VERSION "HNNBNNNYNNNNNNNNNNNNNNNNNNNNNNNNNNNNNNNNNN/4/%%%/4/'%**4NNN///"

NS_ :

BS_:

BU_: BAP_Tester BMS_NV_12V Gateway_Max Klima

BO_ 1413 Systeminfo_01: 8 Gateway_Max
 SG_ SI_Sammel_SG_Fehler : 0|6@1+ (1,0) [0|60] ""  Vector__XXX
 SG_ SI_P_Mode_gueltig : 6|1@1+ (1.0,0.0) [0.0|1] ""  Klima
 SG_ SI_Diagnose_Aktiv : 7|1@1+ (1.0,0.0) [0.0|1] ""  Vector__XXX
 SG_ SI_QRS_Mode : 8|1@1+ (1.0,0.0) [0.0|1] ""  Klima
 SG_ SI_T_Mode : 9|1@1+ (1.0,0.0) [0.0|1] ""  Klima
 SG_ SI_NWDF : 10|1@1+ (1.0,0.0) [0.0|1] ""  Klima
 SG_ SI_NWDF_gueltig : 11|1@1+ (1.0,0.0) [0.0|1] ""  Klima
 SG_ SI_Sammelfehler : 12|1@1+ (1.0,0.0) [0.0|1] ""  Vector__XXX
 SG_ GW_KD_Fehler : 13|1@1+ (1.0,0.0) [0.0|1] ""  Vector__XXX
 SG_ SI_T_Schutz : 14|1@1+ (1.0,0.0) [0.0|1] ""  Klima
 SG_ SI_P_Mode : 15|1@1+ (1.0,0.0) [0.0|1] ""  Klima
 SG_ SI_BUS_01 : 16|1@1+ (1.0,0.0) [0.0|1] ""  Vector__XXX
 SG_ SI_BUS_02 : 17|1@1+ (1.0,0.0) [0.0|1] ""  Vector__XXX
 SG_ SI_BUS_03 : 18|1@1+ (1.0,0.0) [0.0|1] ""  Vector__XXX
 SG_ SI_BUS_04 : 19|1@1+ (1.0,0.0) [0.0|1] ""  Klima
 SG_ SI_BUS_05 : 20|1@1+ (1.0,0.0) [0.0|1] ""  Vector__XXX
 SG_ SI_BUS_06 : 21|1@1+ (1.0,0.0) [0.0|1] ""  Vector__XXX
 SG_ SI_BUS_07 : 22|1@1+ (1.0,0.0) [0.0|1] ""  Vector__XXX
 SG_ SI_BUS_08 : 23|1@1+ (1.0,0.0) [0.0|1] ""  Vector__XXX
 SG_ SI_BUS_09 : 24|1@1+ (1.0,0.0) [0.0|1] ""  Vector__XXX
 SG_ SI_BUS_10 : 25|1@1+ (1.0,0.0) [0.0|1] ""  Vector__XXX
 SG_ SI_BUS_11 : 26|1@1+ (1.0,0.0) [0.0|1] ""  Vector__XXX
 SG_ SI_BUS_12 : 27|1@1+ (1.0,0.0) [0.0|1] ""  Vector__XXX
 SG_ SI_BUS_13 : 28|1@1+ (1.0,0.0) [0.0|1] ""  Vector__XXX
 SG_ SI_BUS_14 : 29|1@1+ (1.0,0.0) [0.0|1] ""  Vector__XXX
 SG_ SI_BUS_15 : 30|1@1+ (1.0,0.0) [0.0|1] ""  Vector__XXX
 SG_ SI_NWDF_30 : 31|1@1+ (1.0,0.0) [0.0|1] ""  Vector__XXX
 SG_ SI_Bus_Identifikation : 32|8@1+ (1.0,0.0) [0.0|255] ""  Vector__XXX
 SG_ SI_CAB_V14 : 40|24@1+ (1.0,0.0) [0.0|16777215] ""  Klima

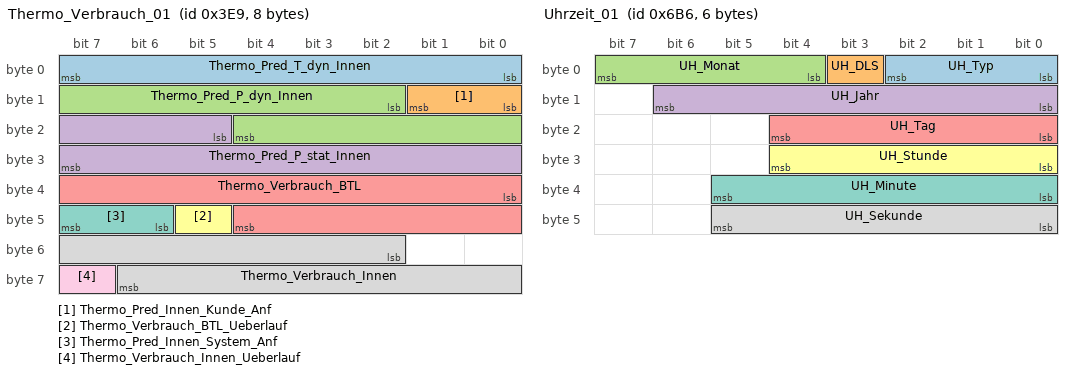
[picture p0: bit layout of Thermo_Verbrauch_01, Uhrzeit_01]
BO_ 1001 Thermo_Verbrauch_01: 8 Klima
 SG_ Thermo_Pred_T_dyn_Innen : 0|8@1+ (1,0) [0|253] "Unit_Minut"  Gateway_Max
 SG_ Thermo_Pred_Innen_Kunde_Anf : 8|2@1+ (1,0) [0|3] "Unit_None"  Gateway_Max
 SG_ Thermo_Pred_P_dyn_Innen : 10|11@1+ (10,0) [0|20450] "Unit_Watt"  Gateway_Max
 SG_ Thermo_Pred_P_stat_Innen : 21|11@1+ (10,0) [0|20450] "Unit_Watt"  Gateway_Max
 SG_ Thermo_Verbrauch_BTL : 32|13@1+ (1,0) [0|8191] "Unit_WattSecond"  Gateway_Max
 SG_ Thermo_Verbrauch_BTL_Ueberlauf : 45|1@1+ (1.0,0.0) [0.0|1] ""  Gateway_Max
 SG_ Thermo_Pred_Innen_System_Anf : 46|2@1+ (1,0) [0|3] "Unit_None"  Gateway_Max
 SG_ Thermo_Verbrauch_Innen : 50|13@1+ (1,0) [0|8191] "Unit_WattSecond"  Gateway_Max
 SG_ Thermo_Verbrauch_Innen_Ueberlauf : 63|1@1+ (1.0,0.0) [0.0|1] ""  Gateway_Max

BO_ 2527679738 Thermo_Verbrauch_02: 16 Klima
 SG_ Thermo_Pred_T_dyn_In_Standard : 12|8@1+ (1,0) [0|253] "Unit_Minut"  Vector__XXX
 SG_ Thermo_Pred_P_stat_In_Standard : 20|11@1+ (10,0) [0|20450] "Unit_Watt"  Vector__XXX
 SG_ Thermo_Pred_T_dyn_In_Efficien1 : 31|8@1+ (1,0) [0|253] "Unit_Minut"  Vector__XXX
 SG_ Thermo_Pred_P_dyn_In_Efficien1 : 39|11@1+ (10,0) [0|20450] "Unit_Watt"  Vector__XXX
 SG_ Thermo_Pred_P_stat_In_Efficien1 : 50|11@1+ (10,0) [0|20450] "Unit_Watt"  Vector__XXX
 SG_ Thermo_Pred_P_dyn_In_Efficien2 : 76|11@1+ (10,0) [0|20450] "Unit_Watt"  Vector__XXX
 SG_ Thermo_Pred_P_stat_In_Efficien2 : 87|11@1+ (10,0) [0|20450] "Unit_Watt"  Vector__XXX
 SG_ Thermo_Pred_T_dyn_In_Efficien2 : 98|8@1+ (1,0) [0|253] "Unit_Minut"  Vector__XXX
 SG_ Thermo_Pred_P_dyn_In_Standard : 106|11@1+ (10,0) [0|20450] "Unit_Watt"  Vector__XXX

BO_ 1447 TM_01: 8 Gateway_Max
 SG_ ORU_KombiTimer : 20|2@1+ (1.0,0.0) [0.0|3] ""  Vector__XXX
 SG_ MOD_Energie_Anf : 22|2@1+ (1.0,0.0) [0.0|3] ""  Vector__XXX
 SG_ FaceRec_Enroll_Challenge_Request : 24|1@1+ (1.0,0.0) [0.0|1] ""  Vector__XXX
 SG_ eCall_Mute_Anf : 25|1@1+ (1.0,0.0) [0.0|1] ""  Vector__XXX
 SG_ eCall_MCC : 26|10@1+ (1,0) [0|999] "Unit_None"  Vector__XXX
 SG_ FoD_Anz_Funktionsabschaltung : 36|2@1+ (1.0,0.0) [0.0|3] ""  Vector__XXX
 SG_ iCall_active : 38|1@1+ (1.0,0.0) [0.0|1] ""  Vector__XXX
 SG_ bCall_active : 39|1@1+ (1.0,0.0) [0.0|1] ""  Vector__XXX
 SG_ MOD_Request_ServiceKey : 40|1@1+ (1.0,0.0) [0.0|1] ""  Vector__XXX
 SG_ eCall_Funktionsstatus_02 : 41|3@1+ (1.0,0.0) [0.0|7] ""  Klima
 SG_ eCall_Funktionsstatus : 44|3@1+ (1.0,0.0) [0.0|7] ""  Vector__XXX
 SG_ TM_Spiegel_Anklappen : 47|1@1+ (1.0,0.0) [0.0|1] ""  Vector__XXX
 SG_ TM_Nur_Hupen : 48|1@1+ (1.0,0.0) [0.0|1] ""  Vector__XXX
 SG_ TM_Door_Lock : 49|1@1+ (1.0,0.0) [0.0|1] ""  Vector__XXX
 SG_ TM_Door_Unlock : 50|1@1+ (1.0,0.0) [0.0|1] ""  Vector__XXX
 SG_ TM_Warnblinken : 51|1@1+ (1.0,0.0) [0.0|1] ""  Vector__XXX
 SG_ TM_Panik_Alarm : 52|1@1+ (1.0,0.0) [0.0|1] ""  Vector__XXX
 SG_ TM_ZV_Signatur : 53|11@1+ (1,0) [1|2047] "Unit_None"  Vector__XXX

BO_ 977 TSG_BT_01: 8 Gateway_Max
 SG_ BT_Tuer_geoeffnet : 0|1@1+ (1.0,0.0) [0.0|1] ""  Vector__XXX
 SG_ BT_verriegelt : 1|1@1+ (1.0,0.0) [0.0|1] ""  Vector__XXX
 SG_ BT_gesafet : 2|1@1+ (1.0,0.0) [0.0|1] ""  Vector__XXX
 SG_ BT_Schluesselschalter_auf : 3|1@1+ (1.0,0.0) [0.0|1] ""  Vector__XXX
 SG_ BT_Schluesselschalter_zu : 4|1@1+ (1.0,0.0) [0.0|1] ""  Vector__XXX
 SG_ BT_Unlock_Taster : 5|1@1+ (1.0,0.0) [0.0|1] ""  Vector__XXX
 SG_ BT_Lock_Taster : 6|1@1+ (1.0,0.0) [0.0|1] ""  Vector__XXX
 SG_ BT_Sperrklinke : 7|1@1+ (1.0,0.0) [0.0|1] ""  Vector__XXX
 SG_ BT_TAG_betaetigt : 8|1@1+ (1.0,0.0) [0.0|1] ""  Vector__XXX
 SG_ BT_TIG_betaetigt : 9|1@1+ (1.0,0.0) [0.0|1] ""  Vector__XXX
 SG_ BT_EC_Spiegel_Helligkeit : 10|5@1+ (3.125,0) [0.000|96.875] "Unit_PerCent"  Vector__XXX
 SG_ BT_Sp_Heizung_Anf : 15|1@1+ (100,0) [0|100] "Unit_PerCent"  Vector__XXX
 SG_ BT_Tuer_Status : 16|2@1+ (1.0,0.0) [0.0|3] ""  Vector__XXX
 SG_ BT_TSG_hinten_verbaut : 18|1@1+ (1.0,0.0) [0.0|1] ""  Vector__XXX
 SG_ BT_Sp_Blk_def : 19|1@1+ (1.0,0.0) [0.0|1] ""  Vector__XXX
 SG_ BT_FH_S_ManHoch : 20|1@1+ (1.0,0.0) [0.0|1] ""  Vector__XXX
 SG_ BT_FH_S_AutoHoch : 21|1@1+ (1.0,0.0) [0.0|1] ""  Vector__XXX
 SG_ BT_FH_S_ManTief : 22|1@1+ (1.0,0.0) [0.0|1] ""  Vector__XXX
 SG_ BT_FH_S_AutoTief : 23|1@1+ (1.0,0.0) [0.0|1] ""  Vector__XXX
 SG_ BT_FH_Oeffnung : 24|8@1+ (0.5,0) [0.0|100.0] "Unit_PerCent"  Klima
 SG_ BT_FH_Bew_hoch : 32|1@1+ (1.0,0.0) [0.0|1] ""  Vector__XXX
 SG_ BT_FH_Bew_tief : 33|1@1+ (1.0,0.0) [0.0|1] ""  Vector__XXX
 SG_ BT_FH_Fang : 34|1@1+ (1.0,0.0) [0.0|1] ""  Vector__XXX
 SG_ BT_FH_Block : 35|1@1+ (1.0,0.0) [0.0|1] ""  Vector__XXX
 SG_ BT_FH_Thermo : 36|1@1+ (1.0,0.0) [0.0|1] ""  Vector__XXX
 SG_ BT_UEKB_aktiviert : 37|1@1+ (1.0,0.0) [0.0|1] ""  Vector__XXX
 SG_ BT_Kisi_Fehler : 38|1@1+ (1.0,0.0) [0.0|1] ""  Vector__XXX
 SG_ BT_FH_normiert : 39|1@1+ (1.0,0.0) [0.0|1] ""  Vector__XXX
 SG_ BT_Schliesstaster : 40|1@1+ (1.0,0.0) [0.0|1] ""  Vector__XXX
 SG_ BT_Zuziehhilfe_aktiv : 41|1@1+ (1.0,0.0) [0.0|1] ""  Vector__XXX
 SG_ BT_SP_ausgerastet : 42|1@1+ (1.0,0.0) [0.0|1] ""  Vector__XXX
 SG_ BT_SP_lr_aktiv : 43|1@1+ (1.0,0.0) [0.0|1] ""  Vector__XXX
 SG_ BT_SP_ht_aktiv : 44|1@1+ (1.0,0.0) [0.0|1] ""  Vector__XXX
 SG_ BT_SP_Heizung_aktiv : 45|1@1+ (1.0,0.0) [0.0|1] ""  Vector__XXX
 SG_ BT_Oben_Block_erw : 46|1@1+ (1.0,0.0) [0.0|1] ""  Vector__XXX
 SG_ BT_Unten_Block_erw : 47|1@1+ (1.0,0.0) [0.0|1] ""  Vector__XXX
 SG_ BT_Tuer_Status_QBit : 48|1@1+ (1.0,0.0) [0.0|1] ""  Vector__XXX
 SG_ BFS_Status_eTAG : 49|2@1+ (1.0,0.0) [0.0|3] ""  Vector__XXX
 SG_ BT_TCR_Mode_aktiv : 51|1@1+ (1.0,0.0) [0.0|1] ""  Vector__XXX
 SG_ BT_Lock_Unlock_Taster : 52|1@1+ (1.0,0.0) [0.0|1] ""  Vector__XXX
 SG_ BT_SP_Heizung_Status : 55|1@1+ (1.0,0.0) [0.0|1] ""  Vector__XXX
 SG_ ASW_Warnung_aktiv_BFS : 56|1@1+ (1.0,0.0) [0.0|1] ""  Vector__XXX
 SG_ BT_FH_Pos_oben : 57|1@1+ (1.0,0.0) [0.0|1] ""  Vector__XXX
 SG_ BT_Tuerschloss_defekt : 58|1@1+ (1.0,0.0) [0.0|1] ""  Vector__XXX
 SG_ BT_Tueroeffnen_Warnung : 59|1@1+ (1.0,0.0) [0.0|1] ""  Vector__XXX
 SG_ BT_Lock_Taster_inv : 60|1@1+ (1.0,0.0) [0.0|1] ""  Vector__XXX
 SG_ BT_Schluesselschalter_zu_inv : 61|1@1+ (1.0,0.0) [0.0|1] ""  Vector__XXX
 SG_ BT_SWA_HMI_defekt : 62|1@1+ (1.0,0.0) [0.0|1] ""  Vector__XXX
 SG_ BT_ASW_HMI_defekt : 63|1@1+ (1.0,0.0) [0.0|1] ""  Vector__XXX

BO_ 976 TSG_FT_01: 8 Gateway_Max
 SG_ FT_Tuer_geoeffnet : 0|1@1+ (1.0,0.0) [0.0|1] ""  Klima
 SG_ FT_verriegelt : 1|1@1+ (1.0,0.0) [0.0|1] ""  Vector__XXX
 SG_ FT_gesafet : 2|1@1+ (1.0,0.0) [0.0|1] ""  Vector__XXX
 SG_ FT_Schluesselschalter_auf : 3|1@1+ (1.0,0.0) [0.0|1] ""  Vector__XXX
 SG_ FT_Schluesselschalter_zu : 4|1@1+ (1.0,0.0) [0.0|1] ""  Vector__XXX
 SG_ FT_Unlock_Taster : 5|1@1+ (1.0,0.0) [0.0|1] ""  Vector__XXX
 SG_ FT_Lock_Taster : 6|1@1+ (1.0,0.0) [0.0|1] ""  Vector__XXX
 SG_ FT_Sperrklinke : 7|1@1+ (1.0,0.0) [0.0|1] ""  Vector__XXX
 SG_ FT_TAG_betaetigt : 8|1@1+ (1.0,0.0) [0.0|1] ""  Vector__XXX
 SG_ FT_TIG_betaetigt : 9|1@1+ (1.0,0.0) [0.0|1] ""  Vector__XXX
 SG_ FT_IRUE_Taste : 10|1@1+ (1.0,0.0) [0.0|1] ""  Vector__XXX
 SG_ FT_HD_Taste : 11|1@1+ (1.0,0.0) [0.0|1] ""  Vector__XXX
 SG_ FT_TD_Taste_Fehler : 12|1@1+ (1.0,0.0) [0.0|1] ""  Vector__XXX
 SG_ FT_TD_Taste : 13|1@1+ (1.0,0.0) [0.0|1] ""  Vector__XXX
 SG_ SSR_Temp_Freigabe : 14|1@1+ (1.0,0.0) [0.0|1] ""  Vector__XXX
 SG_ FT_Sp_Heizung_Anf : 15|1@1+ (100,0) [0|100] "Unit_PerCent"  Vector__XXX
 SG_ FT_HD_Taste_2 : 16|1@1+ (1.0,0.0) [0.0|1] ""  Vector__XXX
 SG_ FT_Lock_Unlock_Taster : 17|1@1+ (1.0,0.0) [0.0|1] ""  Vector__XXX
 SG_ FT_TSG_hinten_verbaut : 18|1@1+ (1.0,0.0) [0.0|1] ""  Vector__XXX
 SG_ FT_Sp_Blk_def : 19|1@1+ (1.0,0.0) [0.0|1] ""  Vector__XXX
 SG_ FT_FH_S_ManHoch : 20|1@1+ (1.0,0.0) [0.0|1] ""  Vector__XXX
 SG_ FT_FH_S_AutoHoch : 21|1@1+ (1.0,0.0) [0.0|1] ""  Vector__XXX
 SG_ FT_FH_S_ManTief : 22|1@1+ (1.0,0.0) [0.0|1] ""  Vector__XXX
 SG_ FT_FH_S_AutoTief : 23|1@1+ (1.0,0.0) [0.0|1] ""  Vector__XXX
 SG_ FT_FH_Oeffnung : 24|8@1+ (0.5,0) [0.0|100.0] "Unit_PerCent"  Klima
 SG_ FT_FH_Bew_hoch : 32|1@1+ (1.0,0.0) [0.0|1] ""  Vector__XXX
 SG_ FT_FH_Bew_tief : 33|1@1+ (1.0,0.0) [0.0|1] ""  Vector__XXX
 SG_ FT_FH_Fang : 34|1@1+ (1.0,0.0) [0.0|1] ""  Vector__XXX
 SG_ FT_FH_Block : 35|1@1+ (1.0,0.0) [0.0|1] ""  Vector__XXX
 SG_ FT_FH_Thermo : 36|1@1+ (1.0,0.0) [0.0|1] ""  Vector__XXX
 SG_ FT_UEKB_aktiviert : 37|1@1+ (1.0,0.0) [0.0|1] ""  Vector__XXX
 SG_ ASW_HMI_defekt : 38|1@1+ (1.0,0.0) [0.0|1] ""  Vector__XXX
 SG_ FT_FH_normiert : 39|1@1+ (1.0,0.0) [0.0|1] ""  Vector__XXX
 SG_ FT_Schliesstaster : 40|1@1+ (1.0,0.0) [0.0|1] ""  Vector__XXX
 SG_ FT_Zuziehhilfe_aktiv : 41|1@1+ (1.0,0.0) [0.0|1] ""  Vector__XXX
 SG_ FT_SP_ausgerastet : 42|1@1+ (1.0,0.0) [0.0|1] ""  Vector__XXX
 SG_ FT_SP_lr_aktiv : 43|1@1+ (1.0,0.0) [0.0|1] ""  Vector__XXX
 SG_ FT_SP_ht_aktiv : 44|1@1+ (1.0,0.0) [0.0|1] ""  Vector__XXX
 SG_ ASW_wakeup : 45|1@1+ (1.0,0.0) [0.0|1] ""  Vector__XXX
 SG_ FT_Oben_Block_erw : 46|1@1+ (1.0,0.0) [0.0|1] ""  Vector__XXX
 SG_ FT_Unten_Block_erw : 47|1@1+ (1.0,0.0) [0.0|1] ""  Vector__XXX
 SG_ FT_Kisi_li_aktiv : 48|1@1+ (1.0,0.0) [0.0|1] ""  Klima
 SG_ FT_Kisi_re_aktiv : 49|1@1+ (1.0,0.0) [0.0|1] ""  Vector__XXX
 SG_ FT_Kisi_Taster_li : 50|1@1+ (1.0,0.0) [0.0|1] ""  Vector__XXX
 SG_ FT_Kisi_Taster_re : 51|1@1+ (1.0,0.0) [0.0|1] ""  Vector__XXX
 SG_ FT_BFS_Fond_Freigabe : 52|1@1+ (1.0,0.0) [0.0|1] ""  Vector__XXX
 SG_ FT_Kisi_Fehler : 53|1@1+ (1.0,0.0) [0.0|1] ""  Vector__XXX
 SG_ FT_Daemmglas : 54|1@1+ (1.0,0.0) [0.0|1] ""  Vector__XXX
 SG_ FT_SP_Heizung_Status : 55|1@1+ (1.0,0.0) [0.0|1] ""  Vector__XXX
 SG_ ASW_Warnung_aktiv_FS : 56|1@1+ (1.0,0.0) [0.0|1] ""  Vector__XXX
 SG_ FT_FH_Pos_oben : 57|1@1+ (1.0,0.0) [0.0|1] ""  Vector__XXX
 SG_ FT_Tuerschloss_defekt : 58|1@1+ (1.0,0.0) [0.0|1] ""  Vector__XXX
 SG_ FT_SWA_Taster : 59|1@1+ (1.0,0.0) [0.0|1] ""  Vector__XXX
 SG_ SWA_HMI_Diagnose : 60|2@1+ (1.0,0.0) [0.0|3] ""  Vector__XXX
 SG_ FS_Status_eTAG : 62|2@1+ (1.0,0.0) [0.0|3] ""  Vector__XXX

BO_ 975 TSG_HBFS_01: 8 Gateway_Max
 SG_ HBFS_Tuer_geoeffnet : 0|1@1+ (1.0,0.0) [0.0|1] ""  Klima
 SG_ HBFS_verriegelt : 1|1@1+ (1.0,0.0) [0.0|1] ""  Vector__XXX
 SG_ HBFS_gesafet : 2|1@1+ (1.0,0.0) [0.0|1] ""  Vector__XXX
 SG_ HBFS_Heckrollotaster_betaetigt : 3|1@1+ (1.0,0.0) [0.0|1] ""  Vector__XXX
 SG_ HBFS_Tuerschloss_defekt : 4|1@1+ (1.0,0.0) [0.0|1] ""  Vector__XXX
 SG_ HBFS_Unlock_Taster : 5|1@1+ (1.0,0.0) [0.0|1] ""  Vector__XXX
 SG_ HBFS_Lock_Taster : 6|1@1+ (1.0,0.0) [0.0|1] ""  Vector__XXX
 SG_ HBFS_Sperrklinke : 7|1@1+ (1.0,0.0) [0.0|1] ""  Vector__XXX
 SG_ HBFS_TAG_betaetigt : 8|1@1+ (1.0,0.0) [0.0|1] ""  Vector__XXX
 SG_ HBFS_TIG_betaetigt : 9|1@1+ (1.0,0.0) [0.0|1] ""  Vector__XXX
 SG_ HBFS_FH_S_HFS_AutoHoch : 10|1@1+ (1.0,0.0) [0.0|1] ""  Vector__XXX
 SG_ HBFS_FH_S_HFS_AutoTief : 11|1@1+ (1.0,0.0) [0.0|1] ""  Vector__XXX
 SG_ HBFS_FH_S_HFS_ManHoch : 12|1@1+ (1.0,0.0) [0.0|1] ""  Vector__XXX
 SG_ HBFS_FH_S_HFS_ManTief : 13|1@1+ (1.0,0.0) [0.0|1] ""  Vector__XXX
 SG_ HBFS_Tuer_Status : 14|2@1+ (1.0,0.0) [0.0|3] ""  Vector__XXX
 SG_ HBFS_SAD_Schalter : 16|4@1+ (1.0,0.0) [0.0|15] ""  Vector__XXX
 SG_ HBFS_FH_S_ManHoch : 20|1@1+ (1.0,0.0) [0.0|1] ""  Vector__XXX
 SG_ HBFS_FH_S_AutoHoch : 21|1@1+ (1.0,0.0) [0.0|1] ""  Vector__XXX
 SG_ HBFS_FH_S_ManTief : 22|1@1+ (1.0,0.0) [0.0|1] ""  Vector__XXX
 SG_ HBFS_FH_S_AutoTief : 23|1@1+ (1.0,0.0) [0.0|1] ""  Vector__XXX
 SG_ HBFS_FH_Oeffnung : 24|8@1+ (0.5,0) [0.0|100.0] "Unit_PerCent"  Klima
 SG_ HBFS_FH_Bew_hoch : 32|1@1+ (1.0,0.0) [0.0|1] ""  Vector__XXX
 SG_ HBFS_FH_Bew_tief : 33|1@1+ (1.0,0.0) [0.0|1] ""  Vector__XXX
 SG_ HBFS_FH_Fang : 34|1@1+ (1.0,0.0) [0.0|1] ""  Vector__XXX
 SG_ HBFS_FH_Block : 35|1@1+ (1.0,0.0) [0.0|1] ""  Vector__XXX
 SG_ HBFS_FH_Thermo : 36|1@1+ (1.0,0.0) [0.0|1] ""  Vector__XXX
 SG_ HBFS_UEKB_aktiviert : 37|1@1+ (1.0,0.0) [0.0|1] ""  Vector__XXX
 SG_ HBFS_Tueroeffnen_Warnung : 38|1@1+ (1.0,0.0) [0.0|1] ""  Vector__XXX
 SG_ HBFS_FH_normiert : 39|1@1+ (1.0,0.0) [0.0|1] ""  Vector__XXX
 SG_ ASW_Warnung_aktiv_HBFS : 40|1@1+ (1.0,0.0) [0.0|1] ""  Vector__XXX
 SG_ HBFS_Zuziehhilfe_aktiv : 41|1@1+ (1.0,0.0) [0.0|1] ""  Vector__XXX
 SG_ HBFS_Seitenrollo_hoch : 42|1@1+ (1.0,0.0) [0.0|1] ""  Vector__XXX
 SG_ HBFS_Seitenrollo_tief : 43|1@1+ (1.0,0.0) [0.0|1] ""  Vector__XXX
 SG_ HBFS_Status_KiSi : 44|1@1+ (1.0,0.0) [0.0|1] ""  Vector__XXX
 SG_ SSR_HBFS_Pos_Unten : 45|1@1+ (1.0,0.0) [0.0|1] ""  Vector__XXX
 SG_ HBFS_Oben_Block_erw : 46|1@1+ (1.0,0.0) [0.0|1] ""  Vector__XXX
 SG_ HBFS_Unten_Block_erw : 47|1@1+ (1.0,0.0) [0.0|1] ""  Vector__XXX
 SG_ MTHBFS_M_Taste : 48|1@1+ (1.0,0.0) [0.0|1] ""  Vector__XXX
 SG_ MTHBFS_Pos1 : 49|1@1+ (1.0,0.0) [0.0|1] ""  Vector__XXX
 SG_ MTHBFS_Pos2 : 50|1@1+ (1.0,0.0) [0.0|1] ""  Vector__XXX
 SG_ MTHBFS_Pos3 : 51|1@1+ (1.0,0.0) [0.0|1] ""  Vector__XXX
 SG_ HBFS_MRollo_Schalter : 52|3@1+ (1.0,0.0) [0.0|7] ""  Vector__XXX
 SG_ HBFS_Lock_Taster_inv : 55|1@1+ (1.0,0.0) [0.0|1] ""  Vector__XXX
 SG_ HBFS_Status_KiSi_inv : 56|1@1+ (1.0,0.0) [0.0|1] ""  Vector__XXX
 SG_ HBFS_Status_eTAG : 57|2@1+ (1.0,0.0) [0.0|3] ""  Vector__XXX
 SG_ HBFS_Tuer_Status_QBit : 59|1@1+ (1.0,0.0) [0.0|1] ""  Vector__XXX
 SG_ HBFS_TIG_betaetigt_schliessen : 60|1@1+ (1.0,0.0) [0.0|1] ""  Vector__XXX
 SG_ HBFS_TIG_betaetigt_oeffnen : 61|1@1+ (1.0,0.0) [0.0|1] ""  Vector__XXX
 SG_ HBFS_Vorraste_betaetigt : 62|1@1+ (1.0,0.0) [0.0|1] ""  Vector__XXX
 SG_ HBFS_SK_betaetigt : 63|1@1+ (1.0,0.0) [0.0|1] ""  Vector__XXX

BO_ 974 TSG_HFS_01: 8 Gateway_Max
 SG_ HFS_Tuer_geoeffnet : 0|1@1+ (1.0,0.0) [0.0|1] ""  Klima
 SG_ HFS_verriegelt : 1|1@1+ (1.0,0.0) [0.0|1] ""  Vector__XXX
 SG_ HFS_gesafet : 2|1@1+ (1.0,0.0) [0.0|1] ""  Vector__XXX
 SG_ HFS_Heckrollotaster_betaetigt : 3|1@1+ (1.0,0.0) [0.0|1] ""  Vector__XXX
 SG_ HFS_Tuerschloss_defekt : 4|1@1+ (1.0,0.0) [0.0|1] ""  Vector__XXX
 SG_ HFS_Unlock_Taster : 5|1@1+ (1.0,0.0) [0.0|1] ""  Vector__XXX
 SG_ HFS_Lock_Taster : 6|1@1+ (1.0,0.0) [0.0|1] ""  Vector__XXX
 SG_ HFS_Sperrklinke : 7|1@1+ (1.0,0.0) [0.0|1] ""  Vector__XXX
 SG_ HFS_TAG_betaetigt : 8|1@1+ (1.0,0.0) [0.0|1] ""  Vector__XXX
 SG_ HFS_TIG_betaetigt : 9|1@1+ (1.0,0.0) [0.0|1] ""  Vector__XXX
 SG_ HFS_FH_S_HBFS_AutoHoch : 10|1@1+ (1.0,0.0) [0.0|1] ""  Vector__XXX
 SG_ HFS_FH_S_HBFS_AutoTief : 11|1@1+ (1.0,0.0) [0.0|1] ""  Vector__XXX
 SG_ HFS_FH_S_HBFS_ManHoch : 12|1@1+ (1.0,0.0) [0.0|1] ""  Vector__XXX
 SG_ HFS_FH_S_HBFS_ManTief : 13|1@1+ (1.0,0.0) [0.0|1] ""  Vector__XXX
 SG_ HFS_Tuer_Status : 14|2@1+ (1.0,0.0) [0.0|3] ""  Vector__XXX
 SG_ HFS_SAD_Schalter : 16|4@1+ (1.0,0.0) [0.0|15] ""  Vector__XXX
 SG_ HFS_FH_S_ManHoch : 20|1@1+ (1.0,0.0) [0.0|1] ""  Vector__XXX
 SG_ HFS_FH_S_AutoHoch : 21|1@1+ (1.0,0.0) [0.0|1] ""  Vector__XXX
 SG_ HFS_FH_S_ManTief : 22|1@1+ (1.0,0.0) [0.0|1] ""  Vector__XXX
 SG_ HFS_FH_S_AutoTief : 23|1@1+ (1.0,0.0) [0.0|1] ""  Vector__XXX
 SG_ HFS_FH_Oeffnung : 24|8@1+ (0.5,0) [0.0|100.0] "Unit_PerCent"  Klima
 SG_ HFS_FH_Bew_hoch : 32|1@1+ (1.0,0.0) [0.0|1] ""  Vector__XXX
 SG_ HFS_FH_Bew_tief : 33|1@1+ (1.0,0.0) [0.0|1] ""  Vector__XXX
 SG_ HFS_FH_Fang : 34|1@1+ (1.0,0.0) [0.0|1] ""  Vector__XXX
 SG_ HFS_FH_Block : 35|1@1+ (1.0,0.0) [0.0|1] ""  Vector__XXX
 SG_ HFS_FH_Thermo : 36|1@1+ (1.0,0.0) [0.0|1] ""  Vector__XXX
 SG_ HFS_UEKB_aktiviert : 37|1@1+ (1.0,0.0) [0.0|1] ""  Vector__XXX
 SG_ HFS_Tueroeffnen_Warnung : 38|1@1+ (1.0,0.0) [0.0|1] ""  Vector__XXX
 SG_ HFS_FH_normiert : 39|1@1+ (1.0,0.0) [0.0|1] ""  Vector__XXX
 SG_ ASW_Warnung_aktiv_HFS : 40|1@1+ (1.0,0.0) [0.0|1] ""  Vector__XXX
 SG_ HFS_Zuziehhilfe_aktiv : 41|1@1+ (1.0,0.0) [0.0|1] ""  Vector__XXX
 SG_ HFS_Seitenrollo_hoch : 42|1@1+ (1.0,0.0) [0.0|1] ""  Vector__XXX
 SG_ HFS_Seitenrollo_tief : 43|1@1+ (1.0,0.0) [0.0|1] ""  Vector__XXX
 SG_ HFS_Status_KiSi : 44|1@1+ (1.0,0.0) [0.0|1] ""  Vector__XXX
 SG_ SSR_HFS_Pos_Unten : 45|1@1+ (1.0,0.0) [0.0|1] ""  Vector__XXX
 SG_ HFS_Oben_Block_erw : 46|1@1+ (1.0,0.0) [0.0|1] ""  Vector__XXX
 SG_ HFS_Unten_Block_erw : 47|1@1+ (1.0,0.0) [0.0|1] ""  Vector__XXX
 SG_ MTHFS_M_Taste : 48|1@1+ (1.0,0.0) [0.0|1] ""  Vector__XXX
 SG_ MTHFS_Pos1 : 49|1@1+ (1.0,0.0) [0.0|1] ""  Vector__XXX
 SG_ MTHFS_Pos2 : 50|1@1+ (1.0,0.0) [0.0|1] ""  Vector__XXX
 SG_ MTHFS_Pos3 : 51|1@1+ (1.0,0.0) [0.0|1] ""  Vector__XXX
 SG_ HFS_MRollo_Schalter : 52|3@1+ (1.0,0.0) [0.0|7] ""  Vector__XXX
 SG_ HFS_Lock_Taster_inv : 55|1@1+ (1.0,0.0) [0.0|1] ""  Vector__XXX
 SG_ HFS_Status_eTAG : 56|2@1+ (1.0,0.0) [0.0|3] ""  Vector__XXX
 SG_ HFS_Tuer_Status_QBit : 58|1@1+ (1.0,0.0) [0.0|1] ""  Vector__XXX
 SG_ HFS_TCR_Mode_aktiv : 59|1@1+ (1.0,0.0) [0.0|1] ""  Vector__XXX
 SG_ HFS_TIG_betaetigt_schliessen : 60|1@1+ (1.0,0.0) [0.0|1] ""  Vector__XXX
 SG_ HFS_TIG_betaetigt_oeffnen : 61|1@1+ (1.0,0.0) [0.0|1] ""  Vector__XXX
 SG_ HFS_Vorraste_betaetigt : 62|1@1+ (1.0,0.0) [0.0|1] ""  Vector__XXX
 SG_ HFS_SK_betaetigt : 63|1@1+ (1.0,0.0) [0.0|1] ""  Vector__XXX

BO_ 1718 Uhrzeit_01: 6 Gateway_Max
 SG_ UH_Typ : 0|3@1+ (1.0,0.0) [0.0|7] ""  Vector__XXX
 SG_ UH_DLS : 3|1@1+ (1.0,0.0) [0.0|1] ""  Klima
 SG_ UH_Monat : 4|4@1+ (1,0) [1|12] "Unit_Month"  Vector__XXX
 SG_ UH_Jahr : 8|7@1+ (1,2000) [2000|2127] "Unit_Year"  Vector__XXX
 SG_ UH_Tag : 16|5@1+ (1,0) [1|31] "Unit_Day"  Vector__XXX
 SG_ UH_Stunde : 24|5@1+ (1,0) [0|23] "Unit_Hours"  Vector__XXX
 SG_ UH_Minute : 32|6@1+ (1,0) [0|59] "Unit_Minut"  Vector__XXX
 SG_ UH_Sekunde : 40|6@1+ (1,0) [0|59] "Unit_Secon"  Vector__XXX

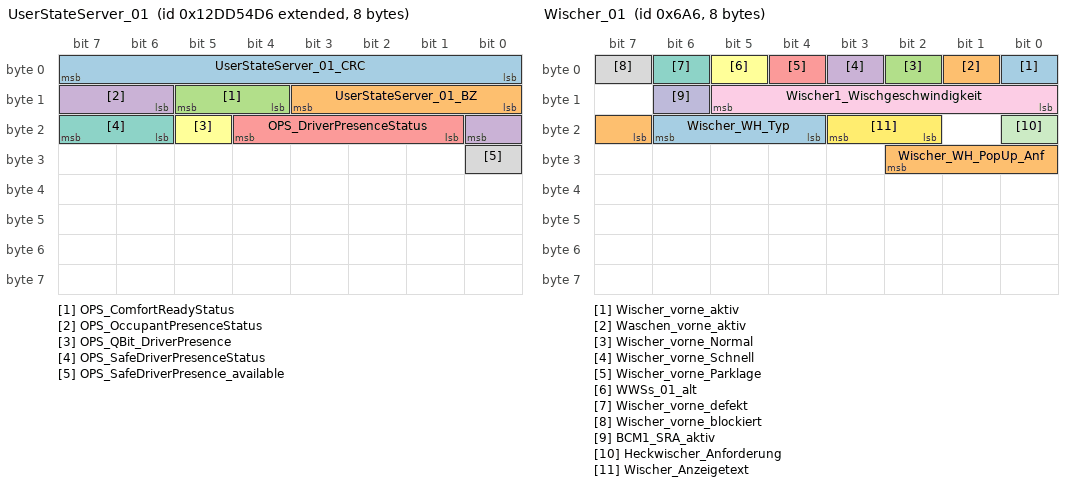
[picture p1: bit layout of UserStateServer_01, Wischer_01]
BO_ 2463978710 UserStateServer_01: 8 Gateway_Max
 SG_ UserStateServer_01_CRC : 0|8@1+ (1,0) [0|255] ""  Vector__XXX
 SG_ UserStateServer_01_BZ : 8|4@1+ (1,0) [0|15] ""  Vector__XXX
 SG_ OPS_ComfortReadyStatus : 12|2@1+ (1.0,0.0) [0.0|3] ""  Klima
 SG_ OPS_OccupantPresenceStatus : 14|3@1+ (1.0,0.0) [0.0|7] ""  Klima
 SG_ OPS_DriverPresenceStatus : 17|4@1+ (1.0,0.0) [0.0|15] ""  Klima
 SG_ OPS_QBit_DriverPresence : 21|1@1+ (1.0,0.0) [0.0|1] ""  Klima
 SG_ OPS_SafeDriverPresenceStatus : 22|2@1+ (1.0,0.0) [0.0|3] ""  Vector__XXX
 SG_ OPS_SafeDriverPresence_available : 24|1@1+ (1.0,0.0) [0.0|1] ""  Vector__XXX

BO_ 995 Verdeck_01: 8 Gateway_Max
 SG_ VS_VD_zu_ver : 16|1@1+ (1.0,0.0) [0.0|1] ""  Klima
 SG_ VS_VD_entriegelt : 17|1@1+ (1.0,0.0) [0.0|1] ""  Vector__XXX
 SG_ VS_VD_offen_ver : 18|1@1+ (1.0,0.0) [0.0|1] ""  Vector__XXX
 SG_ VS_VD_Zwischenposition : 19|1@1+ (1.0,0.0) [0.0|1] ""  Vector__XXX
 SG_ VS_VD_Bew_auf : 20|1@1+ (1.0,0.0) [0.0|1] ""  Klima
 SG_ VS_VD_Bew_zu : 21|1@1+ (1.0,0.0) [0.0|1] ""  Klima
 SG_ VS_Verdeck_Anf : 22|1@1+ (1.0,0.0) [0.0|1] ""  Vector__XXX
 SG_ VS_Hardtop : 23|1@1+ (1.0,0.0) [0.0|1] ""  Vector__XXX
 SG_ VS_VD_Fehler : 24|1@1+ (1.0,0.0) [0.0|1] ""  Vector__XXX
 SG_ VS_Lampe_Blk : 25|1@1+ (1.0,0.0) [0.0|1] ""  Vector__XXX
 SG_ VS_Buzzer : 26|1@1+ (1.0,0.0) [0.0|1] ""  Vector__XXX
 SG_ VS_HD_sperren : 27|1@1+ (1.0,0.0) [0.0|1] ""  Vector__XXX
 SG_ VS_HHS_enable : 28|1@1+ (1.0,0.0) [0.0|1] ""  Vector__XXX
 SG_ VD_SpannungsAnf : 29|2@1+ (1.0,0.0) [0.0|3] ""  Vector__XXX
 SG_ VS_VDKD_auf : 31|1@1+ (1.0,0.0) [0.0|1] ""  Vector__XXX
 SG_ VS_FS_AutoHoch : 32|1@1+ (1.0,0.0) [0.0|1] ""  Vector__XXX
 SG_ VS_FS_AutoTief : 33|1@1+ (1.0,0.0) [0.0|1] ""  Vector__XXX
 SG_ VS_FS_ManHoch : 34|1@1+ (1.0,0.0) [0.0|1] ""  Vector__XXX
 SG_ VS_FS_ManTief : 35|1@1+ (1.0,0.0) [0.0|1] ""  Vector__XXX
 SG_ VS_BFS_AutoHoch : 36|1@1+ (1.0,0.0) [0.0|1] ""  Vector__XXX
 SG_ VS_BFS_AutoTief : 37|1@1+ (1.0,0.0) [0.0|1] ""  Vector__XXX
 SG_ VS_BFS_ManHoch : 38|1@1+ (1.0,0.0) [0.0|1] ""  Vector__XXX
 SG_ VS_BFS_ManTief : 39|1@1+ (1.0,0.0) [0.0|1] ""  Vector__XXX
 SG_ VS_HFS_AutoHoch : 40|1@1+ (1.0,0.0) [0.0|1] ""  Vector__XXX
 SG_ VS_HFS_AutoTief : 41|1@1+ (1.0,0.0) [0.0|1] ""  Vector__XXX
 SG_ VS_HFS_ManHoch : 42|1@1+ (1.0,0.0) [0.0|1] ""  Vector__XXX
 SG_ VS_HFS_ManTief : 43|1@1+ (1.0,0.0) [0.0|1] ""  Vector__XXX
 SG_ VS_HBFS_AutoHoch : 44|1@1+ (1.0,0.0) [0.0|1] ""  Vector__XXX
 SG_ VS_HBFS_AutoTief : 45|1@1+ (1.0,0.0) [0.0|1] ""  Vector__XXX
 SG_ VS_HBFS_ManHoch : 46|1@1+ (1.0,0.0) [0.0|1] ""  Vector__XXX
 SG_ VS_HBFS_ManTief : 47|1@1+ (1.0,0.0) [0.0|1] ""  Vector__XXX
 SG_ VS_FH_FT_Langhub : 49|1@1+ (1.0,0.0) [0.0|1] ""  Vector__XXX
 SG_ VS_Windschott_nicht_abgelegt : 50|1@1+ (1.0,0.0) [0.0|1] ""  Vector__XXX
 SG_ VS_FH_BT_Langhub : 51|1@1+ (1.0,0.0) [0.0|1] ""  Vector__XXX
 SG_ VS_FH_HFS_Langhub : 53|1@1+ (1.0,0.0) [0.0|1] ""  Vector__XXX
 SG_ VS_Heckschloss_auf : 54|1@1+ (1.0,0.0) [0.0|1] ""  Vector__XXX
 SG_ VS_FH_HBFS_Langhub : 55|1@1+ (1.0,0.0) [0.0|1] ""  Vector__XXX
 SG_ VSG_Meldungen : 56|6@1+ (1,0) [1|63] "Unit_None"  Vector__XXX
 SG_ VS_StartStopp_Info : 62|2@1+ (1.0,0.0) [0.0|3] ""  Vector__XXX

BO_ 1716 VIN_01: 8 Gateway_Max
 SG_ VIN_01_MUX M  : 0|2@1+ (1,0) [0|3] ""  Klima
 SG_ KS_Geheimnis_1 m0  : 8|8@1+ (1,0) [0|255] ""  Vector__XXX
 SG_ VIN_4 m1  : 8|8@1+ (1,0) [0|255] ""  Klima
 SG_ VIN_11 m2  : 8|8@1+ (1,0) [0|255] ""  Klima
 SG_ KS_Geheimnis_2 m0  : 16|8@1+ (1,0) [0|255] ""  Vector__XXX
 SG_ VIN_5 m1  : 16|8@1+ (1,0) [0|255] ""  Klima
 SG_ VIN_12 m2  : 16|8@1+ (1,0) [0|255] ""  Klima
 SG_ KS_Geheimnis_3 m0  : 24|8@1+ (1,0) [0|255] ""  Vector__XXX
 SG_ VIN_6 m1  : 24|8@1+ (1,0) [0|255] ""  Klima
 SG_ VIN_13 m2  : 24|8@1+ (1,0) [0|255] ""  Klima
 SG_ KS_Geheimnis_4 m0  : 32|8@1+ (1,0) [0|255] ""  Vector__XXX
 SG_ VIN_7 m1  : 32|8@1+ (1,0) [0|255] ""  Klima
 SG_ VIN_14 m2  : 32|8@1+ (1,0) [0|255] ""  Klima
 SG_ VIN_1 m0  : 40|8@1+ (1,0) [0|255] ""  Klima
 SG_ VIN_8 m1  : 40|8@1+ (1,0) [0|255] ""  Klima
 SG_ VIN_15 m2  : 40|8@1+ (1,0) [0|255] ""  Klima
 SG_ VIN_2 m0  : 48|8@1+ (1,0) [0|255] ""  Klima
 SG_ VIN_9 m1  : 48|8@1+ (1,0) [0|255] ""  Klima
 SG_ VIN_16 m2  : 48|8@1+ (1,0) [0|255] ""  Klima
 SG_ VIN_3 m0  : 56|8@1+ (1,0) [0|255] ""  Klima
 SG_ VIN_10 m1  : 56|8@1+ (1,0) [0|255] ""  Klima
 SG_ VIN_17 m2  : 56|8@1+ (1,0) [0|255] ""  Klima

BO_ 1702 Wischer_01: 8 Gateway_Max
 SG_ Wischer_vorne_aktiv : 0|1@1+ (1.0,0.0) [0.0|1] ""  Klima
 SG_ Waschen_vorne_aktiv : 1|1@1+ (1.0,0.0) [0.0|1] ""  Klima
 SG_ Wischer_vorne_Normal : 2|1@1+ (1.0,0.0) [0.0|1] ""  Vector__XXX
 SG_ Wischer_vorne_Schnell : 3|1@1+ (1.0,0.0) [0.0|1] ""  Vector__XXX
 SG_ Wischer_vorne_Parklage : 4|1@1+ (1.0,0.0) [0.0|1] ""  Vector__XXX
 SG_ WWSs_01_alt : 5|1@1+ (1.0,0.0) [0.0|1] ""  Vector__XXX
 SG_ Wischer_vorne_defekt : 6|1@1+ (1.0,0.0) [0.0|1] ""  Klima
 SG_ Wischer_vorne_blockiert : 7|1@1+ (1.0,0.0) [0.0|1] ""  Vector__XXX
 SG_ Wischer1_Wischgeschwindigkeit : 8|6@1+ (1,9) [10|70] "Unit_MinutInver"  Klima
 SG_ BCM1_SRA_aktiv : 14|1@1+ (1.0,0.0) [0.0|1] ""  Vector__XXX
 SG_ Heckwischer_Anforderung : 16|1@1+ (1.0,0.0) [0.0|1] ""  Vector__XXX
 SG_ Wischer_Anzeigetext : 18|2@1+ (1.0,0.0) [0.0|3] ""  Vector__XXX
 SG_ Wischer_WH_Typ : 20|3@1+ (1.0,0.0) [0.0|7] ""  Vector__XXX
 SG_ Wischer_WH_PopUp_Anf : 23|4@1+ (1.0,0.0) [0.0|15] ""  Vector__XXX

BO_ 1411 ZV_02: 8 Gateway_Max
 SG_ ZV_verriegeln_Anf : 0|1@1+ (1.0,0.0) [0.0|1] ""  Vector__XXX
 SG_ ZV_STSG_HFS_Anf : 1|1@1+ (1.0,0.0) [0.0|1] ""  Vector__XXX
 SG_ ZV_STSG_HBFS_Anf : 2|1@1+ (1.0,0.0) [0.0|1] ""  Vector__XXX
 SG_ ZV_Anf_Challenge_Auth : 3|1@1+ (1.0,0.0) [0.0|1] ""  Vector__XXX
 SG_ ZV_STSG_Crashzustand : 4|1@1+ (1.0,0.0) [0.0|1] ""  Vector__XXX
 SG_ ZV_STSG_eKiSi_defekt : 5|1@1+ (1.0,0.0) [0.0|1] ""  Vector__XXX
 SG_ ZV_eRWK_Umfeld_Pruefung : 6|1@1+ (1.0,0.0) [0.0|1] ""  Vector__XXX
 SG_ VIP_Sensor_STSG_HFS_betaetigt : 10|1@1+ (1.0,0.0) [0.0|1] ""  Vector__XXX
 SG_ VIP_Sensor_STSG_HBFS_betaetigt : 11|1@1+ (1.0,0.0) [0.0|1] ""  Vector__XXX
 SG_ BCM_FH_Freigabe : 12|1@1+ (1.0,0.0) [0.0|1] ""  Vector__XXX
 SG_ BCM_Komfortfkt_Freigabe : 13|1@1+ (1.0,0.0) [0.0|1] ""  Vector__XXX
 SG_ BCM_HSK_Freigabe : 14|1@1+ (1.0,0.0) [0.0|1] ""  Vector__XXX
 SG_ BCM_Verdeck_Freigabe : 15|1@1+ (1.0,0.0) [0.0|1] ""  Vector__XXX
 SG_ ZV_verriegelt_intern_ist : 16|1@1+ (1.0,0.0) [0.0|1] ""  Klima
 SG_ ZV_verriegelt_extern_ist : 17|1@1+ (1.0,0.0) [0.0|1] ""  Klima
 SG_ ZV_verriegelt_intern_soll : 18|1@1+ (1.0,0.0) [0.0|1] ""  Klima
 SG_ ZV_verriegelt_extern_soll : 19|1@1+ (1.0,0.0) [0.0|1] ""  Klima
 SG_ ZV_gesafet_extern_ist : 20|1@1+ (1.0,0.0) [0.0|1] ""  Klima
 SG_ ZV_gesafet_extern_soll : 21|1@1+ (1.0,0.0) [0.0|1] ""  Vector__XXX
 SG_ ZV_Einzeltuerentriegelung : 22|1@1+ (1.0,0.0) [0.0|1] ""  Vector__XXX
 SG_ ZV_Heckeinzelentriegelung : 23|1@1+ (1.0,0.0) [0.0|1] ""  Vector__XXX
 SG_ ZV_FT_offen : 24|1@1+ (1.0,0.0) [0.0|1] ""  Klima
 SG_ ZV_BT_offen : 25|1@1+ (1.0,0.0) [0.0|1] ""  Klima
 SG_ ZV_HFS_offen : 26|1@1+ (1.0,0.0) [0.0|1] ""  Klima
 SG_ ZV_HBFS_offen : 27|1@1+ (1.0,0.0) [0.0|1] ""  Klima
 SG_ ZV_HD_offen : 28|1@1+ (1.0,0.0) [0.0|1] ""  Klima
 SG_ ZV_HS_offen : 29|1@1+ (1.0,0.0) [0.0|1] ""  Vector__XXX
 SG_ IRUE_aktiv : 30|1@1+ (1.0,0.0) [0.0|1] ""  Vector__XXX
 SG_ DWA_aktiv : 31|1@1+ (1.0,0.0) [0.0|1] ""  Vector__XXX
 SG_ HD_Hauptraste : 32|1@1+ (1.0,0.0) [0.0|1] ""  Vector__XXX
 SG_ HD_Vorraste : 33|1@1+ (1.0,0.0) [0.0|1] ""  Vector__XXX
 SG_ FFB_HDF_Taste : 34|1@1+ (1.0,0.0) [0.0|1] ""  Vector__XXX
 SG_ FFB_Panik_Taste : 35|1@1+ (1.0,0.0) [0.0|1] ""  Vector__XXX
 SG_ FFB_Auf_Taste : 36|1@1+ (1.0,0.0) [0.0|1] ""  Vector__XXX
 SG_ FFB_Zu_Taste : 37|1@1+ (1.0,0.0) [0.0|1] ""  Vector__XXX
 SG_ FFB_CarFinder : 38|1@1+ (1.0,0.0) [0.0|1] ""  Vector__XXX
 SG_ FFB_Komfortoeffnen : 39|1@1+ (1.0,0.0) [0.0|1] ""  Vector__XXX
 SG_ FFB_Komfortschliessen : 40|1@1+ (1.0,0.0) [0.0|1] ""  Vector__XXX
 SG_ FBS_IDG_in_Reichweite : 41|1@1+ (1.0,0.0) [0.0|1] ""  Vector__XXX
 SG_ ZV_Schluessel_Zugang : 42|4@1+ (1.0,0.0) [0.0|15] ""  Klima
 SG_ ZV_SafeFunktion_aktiv : 46|1@1+ (1.0,0.0) [0.0|1] ""  Vector__XXX
 SG_ FBS_Warn_Schluessel_Batt : 47|1@1+ (1.0,0.0) [0.0|1] ""  Vector__XXX
 SG_ ZV_Oeffnungsmodus : 48|2@1+ (1.0,0.0) [0.0|3] ""  Vector__XXX
 SG_ HFS_verriegelt : 50|1@1+ (1.0,0.0) [0.0|1] ""  Vector__XXX
 SG_ HFS_gesafet : 51|1@1+ (1.0,0.0) [0.0|1] ""  Vector__XXX
 SG_ HBFS_verriegelt : 52|1@1+ (1.0,0.0) [0.0|1] ""  Vector__XXX
 SG_ HBFS_gesafet : 53|1@1+ (1.0,0.0) [0.0|1] ""  Vector__XXX
 SG_ ZV_ist_Zustand_verfuegbar : 54|1@1+ (1.0,0.0) [0.0|1] ""  Vector__XXX
 SG_ IRUE_Taster_Fkts_LED : 55|1@1+ (1.0,0.0) [0.0|1] ""  Vector__XXX
 SG_ ZV_Tankklappe_offen : 56|1@1+ (1.0,0.0) [0.0|1] ""  Vector__XXX
 SG_ ZV_Rollo_auf : 57|1@1+ (1.0,0.0) [0.0|1] ""  Vector__XXX
 SG_ ZV_Rollo_zu : 58|1@1+ (1.0,0.0) [0.0|1] ""  Vector__XXX
 SG_ ZV_SAD_auf : 59|1@1+ (1.0,0.0) [0.0|1] ""  Vector__XXX
 SG_ ZV_SAD_zu : 60|1@1+ (1.0,0.0) [0.0|1] ""  Vector__XXX
 SG_ BCM_Tankklappensteller_Fehler : 61|1@1+ (1.0,0.0) [0.0|1] ""  Vector__XXX
 SG_ ZV_verriegelt_soll : 62|2@1+ (1.0,0.0) [0.0|3] ""  Vector__XXX

CM_ BO_ 1413 "MQB, MLBevo";
CM_ BO_ 977 "ab MQB 7.05";
CM_ BO_ 976 "ab MQB 7.05";
CM_ BO_ 995 "ab MQB IS5";
CM_ BO_ 1716 "200ms bei D4 und folgende";
CM_ BO_ 1702 "MLBevo";

CM_ SG_ 1413 GW_KD_Fehler "Kundendienstfehlerbit Gateway zur Anzeige eines im Gateway abgelegten Fehlerspeichereintrages.";
CM_ SG_ 1413 SI_BUS_01 "MQB/MQB_A0/PQ26: ACAN
MQB2020: ACAN(FD)
MLBevo: HCAN
E3_Volumen: ACAN(FD)
MQBw_Baseline: ACAN(FD)";
CM_ SG_ 1413 SI_BUS_02 "MQB/MQB A0 Standard+, High: FCAN
MQB2020: FCAN(FD)
MLBevo: Frei
E3_Volumen: FCAN(FD)
MQBw_Baseline: FCAN(FD)";
CM_ SG_ 1413 SI_BUS_03 "MQB/MQB A0/PQ26: KCAN
MQB2020: KCAN
MLBevo: KCAN
E3_Volumen: KCAN(HS) / K2CAN(FD) (Buskopplung)
MQBw_Baseline: KCAN(HS)";
CM_ SG_ 1413 SI_BUS_04 "MQB/MQB A0 Standard+, High: ICAN
MQB2020: ICAN(HS)
MLBevo: ICAN
E3_Volumen: ABCAN(FD)
MQBw_Baseline: ICAN(HS)";
CM_ SG_ 1413 SI_BUS_05 "MQB/MQB A0/PQ26: DiagCAN
MQB2020: DiagCAN(FD)
MLBevo: DiagCAN
E3_Volumen: DiagCAN(FD)
MQBw_Baseline: DiagCAN(FD)";
CM_ SG_ 1413 SI_BUS_06 "MQB/MQB A0/PQ26: ECAN
MQB2020: FASCAN(FD)
MLBevo: ECAN
E3_Volumen: FASCAN_1(FD)
MQBw_Baseline: FASCAN_1(FD)";
CM_ SG_ 1413 SI_BUS_07 "MQB: LIN1 (Energie)
MQB2020: LIN1 (Energie)
MLBevo: LIN1 (Energie)
E3_Volumen: LIN 1 (Energie)
MQBw_Baseline: LIN1 (Energie)";
CM_ SG_ 1413 SI_BUS_08 "MQB: LIN2 (MFL)
MQB2020: LIN2 (MFL)
MLBevo: LIN2 (MFL)
E3_Volumen: LIN2 (MFL)
MQBw_Baseline: LIN2 (MFL)";
CM_ SG_ 1413 SI_BUS_09 "MQB: LIN3 (unbelegt)
MQB2020: LIN3 (Uhr/FES)
MLBevo: LIN3 (Energie2)
MEB: LIN3
E³ 1.1 UNECE: MDKCAN";
CM_ SG_ 1413 SI_BUS_10 "MLBevo: Flexray
MQB2020: MCAN
MQBw_Baseline: FASCAN_2(FD)
E³ 1.1 UNECE: FASCAN_2(FD)";
CM_ SG_ 1413 SI_BUS_11 "MLBevo: Ethernet
MEB: LIN4";
CM_ SG_ 1413 SI_BUS_12 "MQB: unbelegt
MLBevo: K2CAN
E3_Volumen: MFLCAN
MQBw_Baseline: K2CAN(FD)";
CM_ SG_ 1413 SI_BUS_13 "MQB: unbelegt
MLBevo: DCAN
MEB: CCAN
MQBw_Baseline: K3CAN(FD)";
CM_ SG_ 1413 SI_BUS_14 "MQB/MQB A0: unbelegt
MQB2020: HCAN
MLBevo: CCAN
E3_Volumen: EVCAN(FD)
MQBw_Baseline: EVCANFD(FD)";
CM_ SG_ 1413 SI_BUS_15 "MQB: frei
MQB2020: frei
MLBevo: frei
MEB: AFSCAN";
CM_ SG_ 1413 SI_Bus_Identifikation "Das Signal identifiziert den Bus eindeutig. Das Signal ist konstant auf jedem Bus.
Der Signalwert entspricht dem Wert 'Busnummer' aus der VW80127 Gateway_component_list_databus_identification (0x2A2D) 'Bus-Identifier'.";
CM_ SG_ 1413 SI_CAB_V14 "CAB = Clusteraktivbits (V14)";
CM_ SG_ 1413 SI_Diagnose_Aktiv "Gibt an ob Diagnose-Botschaften empfangen werden und somit eine Diagnose aktiv ist.
MQB: Gibt an ob Diagnose-Bus Botschaften empfangen werden und somit eine Diagnose aktiv ist.";
CM_ SG_ 1413 SI_NWDF "Netzwerk-Diagnose Freigebe zur zentralen Aktivierung der Netzwerkdiagnose";
CM_ SG_ 1413 SI_NWDF_30 "Netzwerk-Diagnose Freigabe zur zentralen Aktivierung der Netzwerkdiagnose (keine Ausblendbedingung aktiv)";
CM_ SG_ 1413 SI_NWDF_gueltig "Gültigkeitsbit zu SI_NWDF gemäß Lastenheft: Zentrale Aktivierung Netzwerkdiagnose";
CM_ SG_ 1413 SI_P_Mode "Zentrale Steuerung des Produktionsmodes gemäß Q-LAH-Produktionsmode (LAH.DUM.907.AS)";
CM_ SG_ 1413 SI_P_Mode_gueltig "zeigt an, ob es sich um ein Fahrzeug mit zentraler oder dezentraler Steu-erung des Produktionsmodes handelt
Siehe Q-LAH Produktionsmode (LAH.DUM.907.AS)";
CM_ SG_ 1413 SI_QRS_Mode "Messmodus Quick-Ruhestrom";
CM_ SG_ 1413 SI_Sammel_SG_Fehler "Anzahl der gesetzten KD-Fehler direkt angeschlossener Steuergeräte der DK3 und DK4 gemäß 80127.
Hinweis: Ein Subbusmaster stellt nur die gesammelte Information der an ihn angeschlossenen Steuergeräte der DK3 und DK4 zur Verfügung.

Für ServiceKey Auswe";
CM_ SG_ 1413 SI_Sammelfehler "Sammelfehlermeldung zur Anzeige im Kombi - siehe Spez. Sammelfehlermeldung
Hinweis: Einzelne Steuergeräte können zur Anpassung an den Produktionsprozess im Gateway auskodiert werden!";
CM_ SG_ 1413 SI_T_Mode "0x0: Transportmodus nicht aktiv
0x1: Transportmodus aktiv";
CM_ SG_ 1413 SI_T_Schutz "Transportschutz-Signal, das bei Transportmodus und Motorlauf aktiv bleibt
0x0: Transportschutz nicht aktiv
0x1: Transportschutz aktiv";

CM_ SG_ 1001 Thermo_Pred_Innen_Kunde_Anf "Änderung der Prädiktion iniziiert durch Kundenaktion";
CM_ SG_ 1001 Thermo_Pred_Innen_System_Anf "Systemseitig initiierte Änderung der Prädiktion; Signal ist einheitsloser Zähler mit Überlauf. 
Eine Inkrementierung steht für die Änderung der Umgebungsbedingungen mit dazugehöriger Klimaleistungsänderung.";
CM_ SG_ 1001 Thermo_Pred_P_dyn_Innen "Dynamsiche Leistung für Headup / Cooldown";
CM_ SG_ 1001 Thermo_Pred_P_stat_Innen "Stationäre Leistung für Heizen / Kühlen";
CM_ SG_ 1001 Thermo_Pred_T_dyn_Innen "Zeit bis zum Übergang vom dynamischen in stationären Betrieb";
CM_ SG_ 1001 Thermo_Verbrauch_BTL "Verbrauch für Heizen und Kühlen der Bauteile";
CM_ SG_ 1001 Thermo_Verbrauch_BTL_Ueberlauf "Überlauf-Bit Verbrauch Bauteil";
CM_ SG_ 1001 Thermo_Verbrauch_Innen "Verbrauch für Heizen und Kühlen Innenraum";
CM_ SG_ 1001 Thermo_Verbrauch_Innen_Ueberlauf "Überlauf-Bit Verbrauch Innenraum";

CM_ SG_ 2527679738 Thermo_Pred_P_dyn_In_Efficien1 "Dynamische Leistung für Heatup / Cooldown für Fahrprofil 'Efficiency1'";
CM_ SG_ 2527679738 Thermo_Pred_P_dyn_In_Efficien2 "Dynamische Leistung für Heatup / Cooldown für Fahrprofil 'Efficiency2'";
CM_ SG_ 2527679738 Thermo_Pred_P_dyn_In_Standard "Dynamische Leistung für Heatup / Cooldown für Fahrprofil 'Standard'";
CM_ SG_ 2527679738 Thermo_Pred_P_stat_In_Efficien1 "Stationäre Leistung für Heizen / Kühlen für Fahrprofil 'Efficiency1'";
CM_ SG_ 2527679738 Thermo_Pred_P_stat_In_Efficien2 "Stationäre Leistung für Heizen / Kühlen für Fahrprofil 'Efficiency2'";
CM_ SG_ 2527679738 Thermo_Pred_P_stat_In_Standard "Stationäre Leistung für Heizen / Kühlen für Fahrprofil 'Standard'";
CM_ SG_ 2527679738 Thermo_Pred_T_dyn_In_Efficien1 "Zeit bis zum Übergang vom dynamischen in stationären Betrieb für Fahrprofil 'Efficiency1'";
CM_ SG_ 2527679738 Thermo_Pred_T_dyn_In_Efficien2 "Zeit bis zum Übergang vom dynamischen in stationären Betrieb für Fahrprofil 'Efficiency2'";
CM_ SG_ 2527679738 Thermo_Pred_T_dyn_In_Standard "Zeit bis zum Übergang vom dynamischen in stationären Betrieb für Fahrprofil 'Standard'.";

CM_ SG_ 1447 bCall_active "1: Breakdown call is active
0: BreakdownCall is inactive";
CM_ SG_ 1447 eCall_Funktionsstatus "HMI-Aufruf im Kombi (Broadcast)
Fehlerfälle die im Kombi angezeigt werden können";
CM_ SG_ 1447 eCall_Funktionsstatus_02 "Erweiterung des Funktionsstatus für andere Funktionen
ACN aktiv, MEC aktiv
MEC = manual emergency call = maueller Notruf
ACN = automatic emergency call = automatischer Notruf";
CM_ SG_ 1447 eCall_MCC "Mobile Country Code of the current mobile network
ITU-T E.212";
CM_ SG_ 1447 eCall_Mute_Anf "Signalisiert die Aufforderungen alle Soundquellen im Fahrzeug während eines aktiven Notrufs zu muten";
CM_ SG_ 1447 FaceRec_Enroll_Challenge_Request "When FaceRec on MIK receives this signal it will provide a challenge via SOK_FR_Enroll_MIK_Challenge.";
CM_ SG_ 1447 FoD_Anz_Funktionsabschaltung "Signal triggert Aufschaltung eines Popups, um dem Fahrer die Abschaltung einer Funktion zu melden.";
CM_ SG_ 1447 iCall_active "Statusrückmeldung von OCU über Infocall aktiv/inaktiv";
CM_ SG_ 1447 MOD_Energie_Anf "Anforderung Energieversorgung MOD-Job an das NVEM";
CM_ SG_ 1447 MOD_Request_ServiceKey "Sendet ein Signal zum ServiceKey-Master, welcher daraufhin einen aktuellen ServiceKey1c auf den Bus legt.";
CM_ SG_ 1447 ORU_KombiTimer "Ankündigung eines ORU OCU zum Kombi zur Darstellung entsprechender Symbole";
CM_ SG_ 1447 TM_Door_Lock "Remote Door lock angefordert: ZV zu/verriegeln";
CM_ SG_ 1447 TM_Door_Unlock "Remote Door unlock angefordert: ZV auf/entriegeln";
CM_ SG_ 1447 TM_Nur_Hupen "Remote Hupen (ohne Blinken) aktiviert";
CM_ SG_ 1447 TM_Panik_Alarm "Remote Hupen und Blinken aktiv";
CM_ SG_ 1447 TM_Spiegel_Anklappen "Anklappen der Außenspiegel über Remote MOD Anforderung";
CM_ SG_ 1447 TM_Warnblinken "Remote Blinken aktiviert";
CM_ SG_ 1447 TM_ZV_Signatur "Gespeicherte Signatur der ZV für Authentifizierung";

CM_ SG_ 977 ASW_Warnung_aktiv_BFS "Abschaltung der Ambientefunktion Beifahrertür bei aktiver ASW Warnung an der Fahrertür";
CM_ SG_ 977 BFS_Status_eTAG "Status des elektrischen Tueraussengriffes Beifahrertuer";
CM_ SG_ 977 BT_ASW_HMI_defekt "Zeigt an, ob die ASW-Anzeige defekt ist.";
CM_ SG_ 977 BT_EC_Spiegel_Helligkeit "Dimmung für den Aussenspiegel in %";
CM_ SG_ 977 BT_FH_Bew_hoch "Fensterheber in Bewegung Richtung hoch";
CM_ SG_ 977 BT_FH_Bew_tief "Fensterheber in Bewegung Richtung tief";
CM_ SG_ 977 BT_FH_Block "Fensterscheibe befindet sich im mechanischen Block (oben oder unten)";
CM_ SG_ 977 BT_FH_Fang "Fangbereich ist 4mm von oberer Lippendichtung";
CM_ SG_ 977 BT_FH_normiert "Die Position der Fensterheberscheibe ist bekannt";
CM_ SG_ 977 BT_FH_Oeffnung "Gibt den Fensteröffnungswert in % an.";
CM_ SG_ 977 BT_FH_S_AutoHoch "FH Schalter automatisch hoch gedrückt";
CM_ SG_ 977 BT_FH_S_AutoTief "FH Schalter automatisch tief gedrückt";
CM_ SG_ 977 BT_FH_S_ManHoch "FH Schalter manuell hoch gedrückt";
CM_ SG_ 977 BT_FH_S_ManTief "FH Schalter manuell tief gedrückt";
CM_ SG_ 977 BT_FH_Thermo "gibt an ob Fensterheber im Thermoschutz ist";
CM_ SG_ 977 BT_gesafet "Im Zustand Safe wird auch das Signal BT_verriegelt = 1 gesendet";
CM_ SG_ 977 BT_Kisi_Fehler "Fehlerstatus Kindersicherungsfunktion";
CM_ SG_ 977 BT_Lock_Taster "Verriegelungstaster";
CM_ SG_ 977 BT_Lock_Taster_inv "Lock Taster nicht betätigt";
CM_ SG_ 977 BT_Lock_Unlock_Taster "ZV Funktion Lock Unlock mit Toggle-Logik";
CM_ SG_ 977 BT_Oben_Block_erw "Fensterheber in Blockerwartung oben";
CM_ SG_ 977 BT_Schliesstaster "Schliesstaster Beifahrertür";
CM_ SG_ 977 BT_Schluesselschalter_auf "Schlüsselschalter Richtung auf betätigt";
CM_ SG_ 977 BT_Schluesselschalter_zu "Schluesselschalter Richtung zu betaetigt";
CM_ SG_ 977 BT_Schluesselschalter_zu_inv "Schluesselschalter zu nicht betaetigt";
CM_ SG_ 977 BT_SP_ausgerastet "Spiegel ausgerastet";
CM_ SG_ 977 BT_Sp_Blk_def "Blinker am Spiegel defekt";
CM_ SG_ 977 BT_SP_Heizung_aktiv "Zustand Spiegelheizung Beifahrertür";
CM_ SG_ 977 BT_Sp_Heizung_Anf "Kundenanforderung der Außenspiegelheizung Beifahrertür";
CM_ SG_ 977 BT_SP_Heizung_Status "Status der Spiegelheizung";
CM_ SG_ 977 BT_SP_ht_aktiv "Spiegelverstellung in Richtung hoch/tief aktiv";
CM_ SG_ 977 BT_SP_lr_aktiv "Spiegelverstellung in Richtung links/rechts aktiv";
CM_ SG_ 977 BT_Sperrklinke "Vorraste für Schloß

zwischen Vor- und Hauptraste Signal kurz auf 1, danach wieder auf 0 wenn Tür in Hauptraste (Tür ist sicher zu wenn Sperrklinke und Türkontakt auf 0 sind)";
CM_ SG_ 977 BT_SWA_HMI_defekt "Zeigt an, ob die SWA-Anzeige defekt ist.";
CM_ SG_ 977 BT_TAG_betaetigt "Türaussengriff";
CM_ SG_ 977 BT_TCR_Mode_aktiv "Signal zeigt eine aktive mechanische Redundanz am Türschloss an.";
CM_ SG_ 977 BT_TIG_betaetigt "Türinnengriff";
CM_ SG_ 977 BT_Tuer_geoeffnet "Zeigt eine geöffnete Tür an";
CM_ SG_ 977 BT_Tuer_Status "Türstatus mit Fehler und Initwert";
CM_ SG_ 977 BT_Tuer_Status_QBit "Dieses Bit gibt die Zuverlässigkeit des Türkontakts an. Ein auf dieses Bit folgender Fehlereintrag ist mit dem Sender des Bits abzustimmen (gültig ab PPE).";
CM_ SG_ 977 BT_Tueroeffnen_Warnung "Bit wird gesetzt, wenn Tür während der Fahrt geoeffnet werden soll.";
CM_ SG_ 977 BT_Tuerschloss_defekt "Das Beifahrertürschloss ist nicht mehr funktionsfähig.";
CM_ SG_ 977 BT_UEKB_aktiviert "Überschutzbegrenzungskraft bei Reversieren";
CM_ SG_ 977 BT_Unlock_Taster "Entriegelungstaster betätigt";
CM_ SG_ 977 BT_Unten_Block_erw "Fensterheber in Blockerwartung unten";
CM_ SG_ 977 BT_verriegelt "Zeigt eine verriegelte Tür an ( Status wird erst nach vollständiger Schlossansteuerung ausgegeben (<=1,5sek))";
CM_ SG_ 977 BT_Zuziehhilfe_aktiv "Zuziehhilfe aktiv";

CM_ SG_ 976 ASW_HMI_defekt "HMI Status der Funktion AusstiegsWarnung (ASW). HMI wird durch das TSG angesteuert.";
CM_ SG_ 976 ASW_wakeup "Trigger Start Nachlaufzeit t_1 für die Funktion Ausstieswarnung (ASW)";
CM_ SG_ 976 ASW_Warnung_aktiv_FS "Abschaltung der Ambientefunktion Fahrertür bei aktiver ASW Warnung an der Fahrertür";
CM_ SG_ 976 FS_Status_eTAG "Status des elektrischen Tueraussengriffes Fahrertuer";
CM_ SG_ 976 FT_BFS_Fond_Freigabe "Freigabe für Fondverstellung";
CM_ SG_ 976 FT_Daemmglas "Daemmglas verbaut";
CM_ SG_ 976 FT_FH_Bew_hoch "Fensterheber in Bewegung Richtung hoch";
CM_ SG_ 976 FT_FH_Bew_tief "Fensterheber in Bewegung Richtung tief";
CM_ SG_ 976 FT_FH_Block "Fensterscheibe befindet sich im mechanischen Block (oben oder unten)";
CM_ SG_ 976 FT_FH_Fang "Fangbereich ist 4mm von oberer Lippendichtung";
CM_ SG_ 976 FT_FH_normiert "Die Position der Fensterheberscheibe ist bekannt";
CM_ SG_ 976 FT_FH_Oeffnung "Gibt den Fensteröffnungswert in % an.";
CM_ SG_ 976 FT_FH_S_AutoHoch "FH Schalter automatisch hoch gedrückt";
CM_ SG_ 976 FT_FH_S_AutoTief "FH Schalter automatisch tief gedrückt";
CM_ SG_ 976 FT_FH_S_ManHoch "FH Schalter manuell hoch gedrückt";
CM_ SG_ 976 FT_FH_S_ManTief "FH Schalter manuell tief gedrückt";
CM_ SG_ 976 FT_FH_Thermo "gibt an ob Fensterheber im Thermoschutz ist";
CM_ SG_ 976 FT_gesafet "Im Zustand Safe wird auch das Signal FT_verriegelt = 1 gesendet";
CM_ SG_ 976 FT_HD_Taste "Taste in der Fahrertür zum Öffnen des Heckschlosses";
CM_ SG_ 976 FT_HD_Taste_2 "2. HD-Taste im Bedienfeld 
Funktion: Heckdeckel schließen";
CM_ SG_ 976 FT_IRUE_Taste "Betätigung IRUE-Taster (Innenraumüberwachung)
MQB: Bei Verbau eines einzelnen Taster zur Deaktivierung von IRUE und NGS wird dieses Signal als Deaktivierungsanforderung beider DWA-Alarmquellen gesendet.";
CM_ SG_ 976 FT_Kisi_Fehler "Fehlerstatus Kindersicherungsfunktion";
CM_ SG_ 976 FT_Kisi_li_aktiv "Aktivierungsstatus der Kindersicherung links";
CM_ SG_ 976 FT_Kisi_re_aktiv "Aktivierungsstatus der Kindersicherung rechts";
CM_ SG_ 976 FT_Kisi_Taster_li "Linker Kisi Taster betaetigt";
CM_ SG_ 976 FT_Kisi_Taster_re "Rechter Kisi Taster betaetigt";
CM_ SG_ 976 FT_Lock_Taster "Verriegelungstaster betätigt";
CM_ SG_ 976 FT_Lock_Unlock_Taster "ZV Funktion Lock Unlock mit Toggle-Logik";
CM_ SG_ 976 FT_Oben_Block_erw "Fensterheber in Blockerwartung oben";
CM_ SG_ 976 FT_Schliesstaster "Vorhalt";
CM_ SG_ 976 FT_Schluesselschalter_auf "Schlüsselschalter Richtung auf betätigt";
CM_ SG_ 976 FT_SP_ausgerastet "Spiegel ausgerastet";
CM_ SG_ 976 FT_Sp_Blk_def "Blinker am Spiegel defekt";
CM_ SG_ 976 FT_Sp_Heizung_Anf "Kundenanforderung der Außenspiegelheizung Fahrertür";
CM_ SG_ 976 FT_SP_Heizung_Status "Status der Spiegelheizung";
CM_ SG_ 976 FT_SP_ht_aktiv "Spiegelverstellung in Richtung hoch/tief aktiv";
CM_ SG_ 976 FT_SP_lr_aktiv "Spiegelverstellung in Richtung links/rechts aktiv";
CM_ SG_ 976 FT_Sperrklinke "Vorraste für Schloß

zwischen Vor- und Hauptraste Signal kurz auf 1, danach wieder auf 0 wenn Tür in Hauptraste (Tür ist sicher zu wenn Sperrklinke und Türkontakt auf 0 sind)";
CM_ SG_ 976 FT_SWA_Taster "SWA/ASW Taster Fahrertür";
CM_ SG_ 976 FT_TAG_betaetigt "Türaussengriff

wird nicht im MLB-B8 verwendet";
CM_ SG_ 976 FT_TD_Taste "Tankdeckelentriegelungs-Taste betätigt";
CM_ SG_ 976 FT_TD_Taste_Fehler "Fehlerstatus des Tankdeckelentriegelungstasters. Wird bei Drucktankkonzepten vom MSG zusammen mit dem Signal FT_TD_Taste ausgewertet, um Tankbereitschaft herzustellen.
Der Fehler beschreibt einen hängenden TD_Taster. Ein Kurzschluss oder Leitungsunterbre";
CM_ SG_ 976 FT_TIG_betaetigt "Türinnengriff

wird nicht im MLB-B8 verwendet";
CM_ SG_ 976 FT_Tuer_geoeffnet "Zeigt eine geöffnete Tür an";
CM_ SG_ 976 FT_Tuerschloss_defekt "Das Fahrertürschloss ist nicht mehr funktionsfähig.";
CM_ SG_ 976 FT_UEKB_aktiviert "Überschutzbegrenzungskraft bei Reversieren";
CM_ SG_ 976 FT_Unlock_Taster "Entriegelungstaster betätigt";
CM_ SG_ 976 FT_Unten_Block_erw "Fensterheber in Blockerwartung unten";
CM_ SG_ 976 FT_verriegelt "Zeigt eine verriegelte Tür an ( Status wird erst nach vollständiger Schlossansteuerung ausgegeben (<=1,5sek))";
CM_ SG_ 976 FT_Zuziehhilfe_aktiv "Zuziehhilfe aktiv";
CM_ SG_ 976 SSR_Temp_Freigabe "Freigabe des Seitenscheibenrollos. Bit wird  für die Deaktivierung des SSR bei Innenraumtemperaturen kleiner -10 Grad verwendet.";
CM_ SG_ 976 SWA_HMI_Diagnose "SWA HMI Diagnose beim TSG";

CM_ SG_ 975 ASW_Warnung_aktiv_HBFS "Abschaltung der Ambientefunktion Tür hinten der Beifahrerseite bei aktiver ASW Warnung an der Fahrertür";
CM_ SG_ 975 HBFS_FH_Bew_hoch "HBFS Fenster bewegt sich in Richtung hoch";
CM_ SG_ 975 HBFS_FH_Bew_tief "HBFS Fenster bewegt sich in Richtung tief";
CM_ SG_ 975 HBFS_FH_Block "Fensterscheibe befindet sich im mechanischen Block (oben oder unten)";
CM_ SG_ 975 HBFS_FH_Fang "Fangbereich ist 4mm von oberer Lippendichtung";
CM_ SG_ 975 HBFS_FH_normiert "Die Position der Fensterheberscheibe ist bekannt.";
CM_ SG_ 975 HBFS_FH_Oeffnung "Gibt den Fensteröffnungswert in % an.";
CM_ SG_ 975 HBFS_FH_S_AutoHoch "Betaetigung FH Schalter auto tief ";
CM_ SG_ 975 HBFS_FH_S_AutoTief "Betaetigung FH Schalter auto hoch";
CM_ SG_ 975 HBFS_FH_S_HFS_AutoHoch "Automatisches Hochfahren der Seitenscheibe HFS";
CM_ SG_ 975 HBFS_FH_S_HFS_AutoTief "Automatisches Absenken der Seitenscheibe HFS";
CM_ SG_ 975 HBFS_FH_S_HFS_ManHoch "Manuelles Hochfahren der Seitenscheibe HFS";
CM_ SG_ 975 HBFS_FH_S_HFS_ManTief "Manuelles Absenken der Seitenscheibe HFS";
CM_ SG_ 975 HBFS_FH_S_ManHoch "Betaetigung FH Schalter man hoch ";
CM_ SG_ 975 HBFS_FH_S_ManTief "Betaetigung FH Schalter man tief";
CM_ SG_ 975 HBFS_FH_Thermo "gibt an ob Fensterheber im Thermoschutz ist";
CM_ SG_ 975 HBFS_gesafet "HBFS Tuer gesafet.
Im Zustand Safe wird auch das Signal HBFS_verriegelt = 1 gesendet.";
CM_ SG_ 975 HBFS_Heckrollotaster_betaetigt "Verfahren des Heckrollos in Richtung Hoch

Bei Einfachtaster wird Bit als Togglebit verwendet (Heckrollo hoch, tief)";
CM_ SG_ 975 HBFS_Lock_Taster "Betaetigung Lock-Taster";
CM_ SG_ 975 HBFS_Lock_Taster_inv "Lock Taster nicht betätigt";
CM_ SG_ 975 HBFS_MRollo_Schalter "  | MRollo2
-----------------------------
0 | nicht_betaetigt
1 | (m) Zu
2 | (a) Zu
3 | (m) Auf
4 | (a) Auf
5 | Schalter nicht verfuegbar
6 | Init
7 | Fehlerfall";
CM_ SG_ 975 HBFS_Oben_Block_erw "Fensterheber in Blockerwartung oben";
CM_ SG_ 975 HBFS_SAD_Schalter "  |   Ausstelldach MD3
-----------------------------
0 | nicht_betaetigt
1 |
2 |
3 |
4 |
5 | (m) Auf
6 | (a) Auf
7 | (m) Zu
8 | (a) Zu
13| Schalter nicht verfuegbar
14| Init
15| Fehlerfall";
CM_ SG_ 975 HBFS_Seitenrollo_tief "Seitenrollo in Bewegung Richtung tief";
CM_ SG_ 975 HBFS_SK_betaetigt "Status der Sperrklinke";
CM_ SG_ 975 HBFS_Sperrklinke "Vorraste für Schloß

zwischen Vor- und Hauptraste Signal kurz auf 1, danach wieder auf 0 wenn Tür in Hauptraste (Tür ist sicher zu wenn Sperrklinke und Türkontakt auf 0 sind)";
CM_ SG_ 975 HBFS_Status_eTAG "Status des elektrischen Tueraussengriffes Tuer Beifahrerseite hinten";
CM_ SG_ 975 HBFS_Status_KiSi "Status Kindersicherung HBFS
";
CM_ SG_ 975 HBFS_Status_KiSi_inv "Inverser Status der elektrischen Kindersicherung Beifahrerseite hinten";
CM_ SG_ 975 HBFS_TAG_betaetigt "Betaetigung Türaussengriff";
CM_ SG_ 975 HBFS_TIG_betaetigt "Betaetigung Tuerinnengriff";
CM_ SG_ 975 HBFS_TIG_betaetigt_oeffnen "Türinnenbetätigung, Taster Tür öffnen.";
CM_ SG_ 975 HBFS_TIG_betaetigt_schliessen "Türinnenbetätigung, Taster Tür schließen.";
CM_ SG_ 975 HBFS_Tuer_geoeffnet "HBFS Tuer geoeffnet";
CM_ SG_ 975 HBFS_Tuer_Status "Türstatus mit Fehler und Initwert";
CM_ SG_ 975 HBFS_Tuer_Status_QBit "Dieses Bit gibt die Zuverlässigkeit des Türkontakts an. Ein auf dieses Bit folgender Fehlereintrag ist mit dem Sender des Bits abzustimmen (gültig ab PPE).";
CM_ SG_ 975 HBFS_Tueroeffnen_Warnung "Bit wird gesetzt, wenn Tür während der Fahrt geoeffnet werden soll.";
CM_ SG_ 975 HBFS_Tuerschloss_defekt "Das hintere Tuerschloss auf der Beifahrerseite ist nicht mehr funktionsfähig.";
CM_ SG_ 975 HBFS_UEKB_aktiviert "Überschutzbegrenzungskraft bei Reversieren";
CM_ SG_ 975 HBFS_Unlock_Taster "Betaetigung Unlock Taster";
CM_ SG_ 975 HBFS_Unten_Block_erw "Fensterheber in Blockerwartung unten";
CM_ SG_ 975 HBFS_verriegelt "Verriegelungsstatus Tür";
CM_ SG_ 975 HBFS_Vorraste_betaetigt "Status der Vorraste";
CM_ SG_ 975 HBFS_Zuziehhilfe_aktiv "Zuziehhilfe aktiv";
CM_ SG_ 975 MTHBFS_M_Taste "Betätigung M-Taste HBFS";
CM_ SG_ 975 MTHBFS_Pos1 "Betätigung Postionstaste 1 HBFS";
CM_ SG_ 975 MTHBFS_Pos2 "Betätigung Postionstaste 2 HBFS
";
CM_ SG_ 975 MTHBFS_Pos3 "Betätigung Postionstaste 3 HBFS";
CM_ SG_ 975 SSR_HBFS_Pos_Unten "Signal für die 'Global Close'. Über dieses Bit wissen die anderen TSGs, ob der SSR oder der FH verfahren werden darf.";

CM_ SG_ 974 ASW_Warnung_aktiv_HFS "Abschaltung der Ambientefunktion Tür hinten der Fahrerseite bei aktiver ASW Warnung an der Fahrertür";
CM_ SG_ 974 HFS_FH_Bew_hoch "HFS Fenster bewegt sich in Richtung hoch";
CM_ SG_ 974 HFS_FH_Bew_tief "HFS Fenster bewegt sich in Richtung tief";
CM_ SG_ 974 HFS_FH_Block "Fensterscheibe befindet sich im mechanischen Block (oben oder unten)";
CM_ SG_ 974 HFS_FH_Fang "Fangbereich ist 4mm von oberer Lippendichtung";
CM_ SG_ 974 HFS_FH_normiert "Die Position der Fensterheberscheibe ist bekannt.";
CM_ SG_ 974 HFS_FH_Oeffnung "Gibt den Fensteröffnungswert in % an.";
CM_ SG_ 974 HFS_FH_S_AutoHoch "Betaetigung FH Schalter auto hoch";
CM_ SG_ 974 HFS_FH_S_AutoTief "Betaetigung FH Schalter auto tief ";
CM_ SG_ 974 HFS_FH_S_HBFS_AutoHoch "Automatisches Hochfahren der Seitenscheibe HBFS";
CM_ SG_ 974 HFS_FH_S_HBFS_AutoTief "Automatisches Absenken der Seitenscheibe HBFS";
CM_ SG_ 974 HFS_FH_S_HBFS_ManHoch "Manuelles Hochfahren der Seitenscheibe HBFS";
CM_ SG_ 974 HFS_FH_S_HBFS_ManTief "Manuelles Absenken der Seitenscheibe HBFS";
CM_ SG_ 974 HFS_FH_S_ManHoch "Betaetigung FH Schalter man hoch ";
CM_ SG_ 974 HFS_FH_S_ManTief "Betaetigung FH Schalter man tief";
CM_ SG_ 974 HFS_FH_Thermo "gibt an ob Fensterheber im Thermoschutz ist";
CM_ SG_ 974 HFS_gesafet "HFS Tuer gesafet.
Im Zustand Safe wird auch das Signal HFS_verriegelt = 1 gesendet.";
CM_ SG_ 974 HFS_Heckrollotaster_betaetigt "Verfahren des Heckrollos in Richtung Hoch

Bei Einfachtaster wird Bit als Togglebit verwendet (Heckrollo hoch, tief)";
CM_ SG_ 974 HFS_Lock_Taster "Betätigung Lock-Taster";
CM_ SG_ 974 HFS_Lock_Taster_inv "Lock Taster nicht betätigt";
CM_ SG_ 974 HFS_MRollo_Schalter "  | MRollo2
-----------------------------
0 | nicht_betaetigt
1 | (m) Zu
2 | (a) Zu
3 | (m) Auf
4 | (a) Auf
5 | Schalter nicht verfuegbar
6 | Init
7 | Fehlerfall";
CM_ SG_ 974 HFS_Oben_Block_erw "Fensterheber in Blockerwartung oben";
CM_ SG_ 974 HFS_SAD_Schalter "  |   Ausstelldach MD3
-----------------------------
0 | nicht_betaetigt
1 |
2 |
3 |
4 |
5 | (m) Auf
6 | (a) Auf
7 | (m) Zu
8 | (a) Zu
13| Schalter nicht verfuegbar
14| Init
15| Fehlerfall";
CM_ SG_ 974 HFS_Seitenrollo_hoch "Seitenrollo in Bewegung Richtung hoch";
CM_ SG_ 974 HFS_Seitenrollo_tief "Seitenrollo in Bewegung Richtung tief";
CM_ SG_ 974 HFS_SK_betaetigt "Status der Sperrklinke";
CM_ SG_ 974 HFS_Sperrklinke "Vorraste für Schloß

zwischen Vor- und Hauptraste Signal kurz auf 1, danach wieder auf 0 wenn Tür in Hauptraste (Tür ist sicher zu wenn Sperrklinke und Türkontakt auf 0 sind)";
CM_ SG_ 974 HFS_Status_eTAG "Status des elektrischen Tueraussengriffes Tuer Fahrerseite hinten";
CM_ SG_ 974 HFS_Status_KiSi "Status Kindersicherung hinten Fahrerseite";
CM_ SG_ 974 HFS_TAG_betaetigt "Betaetigung Türaussengriff";
CM_ SG_ 974 HFS_TCR_Mode_aktiv "Signal zeigt eine aktive mechanische Redundanz am Türschloss an.";
CM_ SG_ 974 HFS_TIG_betaetigt "Betaetigung Türinnengriff";
CM_ SG_ 974 HFS_TIG_betaetigt_oeffnen "Türinnenbetätigung, Taster Tür öffnen.";
CM_ SG_ 974 HFS_TIG_betaetigt_schliessen "Türinnenbetätigung, Taster Tür schließen.";
CM_ SG_ 974 HFS_Tuer_geoeffnet "HFS Tuer geoeffnet";
CM_ SG_ 974 HFS_Tuer_Status "Türstatus mit Fehler und Initwert";
CM_ SG_ 974 HFS_Tuer_Status_QBit "Dieses Bit gibt die Zuverlässigkeit des Türkontakts an. Ein auf dieses Bit folgender Fehlereintrag ist mit dem Sender des Bits abzustimmen (gültig ab PPE).";
CM_ SG_ 974 HFS_Tueroeffnen_Warnung "Bit wird gesetzt, wenn Tür während der Fahrt geoeffnet werden soll.";
CM_ SG_ 974 HFS_Tuerschloss_defekt "Das hintere Tuerschloss auf der Fahrerseite ist nicht mehr funktionsfähig.";
CM_ SG_ 974 HFS_UEKB_aktiviert "Überschutzbegrenzungskraft bei Reversieren";
CM_ SG_ 974 HFS_Unlock_Taster "Betaetigung Unlock Taster";
CM_ SG_ 974 HFS_Unten_Block_erw "Fensterheber in Blockerwartung unten";
CM_ SG_ 974 HFS_verriegelt "HFS Tuer verriegelt";
CM_ SG_ 974 HFS_Vorraste_betaetigt "Status der Vorraste";
CM_ SG_ 974 HFS_Zuziehhilfe_aktiv "Zuziehhilfe aktiv";
CM_ SG_ 974 MTHFS_M_Taste "Betätigung M-Taste HFS";
CM_ SG_ 974 MTHFS_Pos1 "Betätigung Postionstaste 1 HFS";
CM_ SG_ 974 MTHFS_Pos2 "Betätigung Postionstaste 2 HFS
";
CM_ SG_ 974 MTHFS_Pos3 "Betätigung Postionstaste 3 HFS";
CM_ SG_ 974 SSR_HFS_Pos_Unten "Signal für die 'Global Close'. Über dieses Bit wissen die anderen TSGs, ob der SSR oder der FH verfahren werden darf.";

CM_ SG_ 1718 UH_Minute "0x3C- 0x3f = Werte ungültig";
CM_ SG_ 1718 UH_Monat "0x0D, 0xF =  Werte ungültig
0x0E = Relatives Datum (nur VW)";
CM_ SG_ 1718 UH_Sekunde "0x3C- 0x3f = Werte ungültig";
CM_ SG_ 1718 UH_Stunde "0x18 - 0x1F = Werte ungültig";
CM_ SG_ 1718 UH_Tag "0x0: reserviert bei VW";
CM_ SG_ 1718 UH_Typ "0x4 - 0x7 = tbd. ";

CM_ SG_ 2463978710 OPS_ComfortReadyStatus "Das Signal wird durch den Basisdienst User State Server (Technikvariante: OccupantPresenceService) erzeugt und bildet einen neuen Zustand, bestehend aus einer Verknüpfung der Fahreranwesenheit (Fahrer abwesend / Fahrer anwesend) und der Klemmensteuerung (";
CM_ SG_ 2463978710 OPS_DriverPresenceStatus "Das Signal wird durch den Basisdienst User State Server (Service: OccupantPresenceService) erzeugt und bildet die Fahrerzustände im Fahrzeug ab.";
CM_ SG_ 2463978710 OPS_OccupantPresenceStatus "Das Signal wird durch den Basisdienst User State Server (Service: OccupantPresenceService) erzeugt und bildet die Anwesenheit und Abwesenheit aller Insassen im Fahrzeug ab.";
CM_ SG_ 2463978710 OPS_QBit_DriverPresence "Das Signal wird durch den Basisdienst User State Server (Service: OccupantPresenceService) erzeugt und signalisiert die Qualität der Fahrerzustände.";
CM_ SG_ 2463978710 OPS_SafeDriverPresence_available "Das Signal signalisiert inwiefern alle vorgesehene Sensoren  für die Anwesenheit verwendet werden oder möglichweise bestimmte Sensoren nicht verfügbar sind.
In beiden Fällen wird eine Anwesenheit berechnet, jedoch bei Ausfall bestimmter Sensoren kann zu ";
CM_ SG_ 2463978710 OPS_SafeDriverPresenceStatus "Signalisierung einer sicheren Fahreranwesenheit nach ASIL B";
CM_ SG_ 2463978710 UserStateServer_01_BZ "4bit Botschaftszähler, wird mit jeder Sendebotschaft inkrementiert";
CM_ SG_ 2463978710 UserStateServer_01_CRC "Für MLB:
Berechnung siehe Lastenheft 'Kommunikationsabsicherung für FlexRay und CAN'
Ab MQB und MLBevo:
Berechnung siehe Lastenheft 'End-to-End Kommunikationsabsicherung'

Endwerte siehe Begleitdokument 'S-PDU Kennungsfolgen'";

CM_ SG_ 995 VD_SpannungsAnf "Anforderung Forderung des Verdecks zur Spannungsanhebung des Bordnetzes.";
CM_ SG_ 995 VS_BFS_AutoHoch "automatischer Hochlauf des BFS Fenster ausgelöst durch die Verdecksteuerung";
CM_ SG_ 995 VS_BFS_AutoTief "automatischer Tieflauf des BFS Fenster ausgelöst durch die Verdecksteuerung";
CM_ SG_ 995 VS_BFS_ManHoch "manueller Hochlauf des BFS Fenster ausgelöst durch die Verdecksteuerung";
CM_ SG_ 995 VS_BFS_ManTief "manueller Tieflauf des BFS Fenster ausgelöst durch die Verdecksteuerung";
CM_ SG_ 995 VS_Buzzer "Buzzeransteuerung: 'Buzzeransteuerung' für Gong 200ms (Kombi)";
CM_ SG_ 995 VS_FH_BT_Langhub "Ansteuerung Fensterheber vom Verdecksteuergeraet";
CM_ SG_ 995 VS_FH_FT_Langhub "Ansteuerung Fensterheber vom Verdecksteuergeraet";
CM_ SG_ 995 VS_FH_HBFS_Langhub "Ansteuerung Fensterheber vom Verdecksteuergeraet";
CM_ SG_ 995 VS_FH_HFS_Langhub "Ansteuerung Fensterheber vom Verdecksteuergeraet";
CM_ SG_ 995 VS_FS_AutoHoch "automatischer Hochlauf des FS Fenster ausgelöst durch die Verdecksteuerung";
CM_ SG_ 995 VS_FS_AutoTief "automatischer Tieflauf des FS Fenster ausgelöst durch die Verdecksteuerung";
CM_ SG_ 995 VS_FS_ManHoch "manueller Hochlauf des FS Fenster ausgelöst durch die Verdecksteuerung";
CM_ SG_ 995 VS_FS_ManTief "manueller Tieflauf des FS Fenster ausgelöst durch die Verdecksteuerung";
CM_ SG_ 995 VS_Hardtop "Hardtop montiert";
CM_ SG_ 995 VS_HBFS_AutoHoch "automatischer Hochlauf des HBFS Fenster ausgelöst durch die Verdecksteuerung";
CM_ SG_ 995 VS_HBFS_AutoTief "automatischer Tieflauf des HBFS Fenster ausgelöst durch die Verdecksteuerung";
CM_ SG_ 995 VS_HBFS_ManHoch "manueller Hochlauf des HBFS Fenster ausgelöst durch die Verdecksteuerung";
CM_ SG_ 995 VS_HBFS_ManTief "manueller Tieflauf des HBFS Fenster ausgelöst durch die Verdecksteuerung";
CM_ SG_ 995 VS_HD_sperren "Bei gesetztem Signal wird der Kofferraum/Heckdeckel durch den BCM2 nicht entriegelt werden.";
CM_ SG_ 995 VS_Heckschloss_auf "Signal wird gesetzt, wenn fuer einen Verdeckbetrieb das Öffnen des Heckschlosses erforderlich ist.";
CM_ SG_ 995 VS_HFS_AutoHoch "automatischer Hochlauf des HFS Fenster ausgelöst durch die Verdecksteuerung";
CM_ SG_ 995 VS_HFS_AutoTief "automatischer Tieflauf des HFS Fenster ausgelöst durch die Verdecksteuerung";
CM_ SG_ 995 VS_HFS_ManHoch "manueller Hochlauf des HFS Fenster ausgelöst durch die Verdecksteuerung";
CM_ SG_ 995 VS_HFS_ManTief "manueller Tieflauf des HFS Fenster ausgelöst durch die Verdecksteuerung";
CM_ SG_ 995 VS_HHS_enable "Fehlende Beschreibung (Import)";
CM_ SG_ 995 VS_Lampe_Blk "Ansteuerung Lampe im Kombi

Wird aktiviert bei Aufprüfen, Verdecklauf und Fehlerfall (blinkend).


";
CM_ SG_ 995 VS_StartStopp_Info "Stopp-Freigabe und Start-Anforderung an den Start-Stopp-Koordinator";
CM_ SG_ 995 VS_VD_Bew_auf "



";
CM_ SG_ 995 VS_VD_Bew_zu "


";
CM_ SG_ 995 VS_VD_entriegelt "Zustand des Verdeck entriegelt";
CM_ SG_ 995 VS_VD_Fehler "Fehlerzustand Verdeck";
CM_ SG_ 995 VS_VD_offen_ver "Zustand des Verdecks verriegelt und offen";
CM_ SG_ 995 VS_VD_zu_ver "
";
CM_ SG_ 995 VS_VD_Zwischenposition "Verdeck in Zwischenposition";
CM_ SG_ 995 VS_VDKD_auf "Signal wird gesetzt, wenn der Verdeckkastendeckel vollstaendig geoeffnet ist



";
CM_ SG_ 995 VS_Verdeck_Anf "Verdeckanforderung (Signalisierung der Bereitschaft zur Verdeckbetaetigung ueber Komfortfunktion)";
CM_ SG_ 995 VS_Windschott_nicht_abgelegt "Windschott ist aufgestellt, in Zwischenposition oder die Position ist unbekannt";
CM_ SG_ 995 VSG_Meldungen "Meldungen fuers Kombi lt. konzernübergreifender Abstimmung

0 -> keine Meldung
1 -> 'Verdeckbetrieb RDW aktiv'
2 -> 'Verdeckbetrieb NAR aktiv'
3 -> 'stehendes Verdeck in Zwischenposition (ZP)'
4 -> 'autom. Verdeck in ZP und KL15 aus'
5 -> 'manuelle";

CM_ SG_ 1716 VIN_01_MUX "Achtung:
Die Botschaft ist nicht linear gemultiplext!!!
Sondern 0,1,0,2,0, usw.";
CM_ SG_ 1716 VIN_1 "Initwert:
0x2D bei Fahrzeugen mit Wegfahrsperrengeneration >= 5 
0x58 bei Fahrzeugen mit Wegfahrsperrengeneration < 5 (z.B. WFS-4)";
CM_ SG_ 1716 VIN_10 "Initwert:
0x2D bei Fahrzeugen mit Wegfahrsperrengeneration >= 5 
0x58 bei Fahrzeugen mit Wegfahrsperrengeneration < 5 (z.B. WFS-4)";
CM_ SG_ 1716 VIN_11 "Initwert:
0x2D bei Fahrzeugen mit Wegfahrsperrengeneration >= 5 
0x58 bei Fahrzeugen mit Wegfahrsperrengeneration < 5 (z.B. WFS-4)";
CM_ SG_ 1716 VIN_12 "Initwert:
0x2D bei Fahrzeugen mit Wegfahrsperrengeneration >= 5 
0x58 bei Fahrzeugen mit Wegfahrsperrengeneration < 5 (z.B. WFS-4)";
CM_ SG_ 1716 VIN_13 "Initwert:
0x2D bei Fahrzeugen mit Wegfahrsperrengeneration >= 5 
0x58 bei Fahrzeugen mit Wegfahrsperrengeneration < 5 (z.B. WFS-4)";
CM_ SG_ 1716 VIN_14 "Initwert:
0x2D bei Fahrzeugen mit Wegfahrsperrengeneration >= 5 
0x58 bei Fahrzeugen mit Wegfahrsperrengeneration < 5 (z.B. WFS-4)";
CM_ SG_ 1716 VIN_15 "Initwert:
0x2D bei Fahrzeugen mit Wegfahrsperrengeneration >= 5 
0x58 bei Fahrzeugen mit Wegfahrsperrengeneration < 5 (z.B. WFS-4)";
CM_ SG_ 1716 VIN_16 "Initwert:
0x2D bei Fahrzeugen mit Wegfahrsperrengeneration >= 5 
0x58 bei Fahrzeugen mit Wegfahrsperrengeneration < 5 (z.B. WFS-4)";
CM_ SG_ 1716 VIN_17 "Initwert:
0x2D bei Fahrzeugen mit Wegfahrsperrengeneration >= 5 
0x58 bei Fahrzeugen mit Wegfahrsperrengeneration < 5 (z.B. WFS-4)";
CM_ SG_ 1716 VIN_2 "Initwert:
0x2D bei Fahrzeugen mit Wegfahrsperrengeneration >= 5 
0x58 bei Fahrzeugen mit Wegfahrsperrengeneration < 5 (z.B. WFS-4)";
CM_ SG_ 1716 VIN_3 "Initwert:
0x2D bei Fahrzeugen mit Wegfahrsperrengeneration >= 5 
0x58 bei Fahrzeugen mit Wegfahrsperrengeneration < 5 (z.B. WFS-4)";
CM_ SG_ 1716 VIN_4 "Initwert:
0x2D bei Fahrzeugen mit Wegfahrsperrengeneration >= 5 
0x58 bei Fahrzeugen mit Wegfahrsperrengeneration < 5 (z.B. WFS-4)";
CM_ SG_ 1716 VIN_5 "Initwert:
0x2D bei Fahrzeugen mit Wegfahrsperrengeneration >= 5 
0x58 bei Fahrzeugen mit Wegfahrsperrengeneration < 5 (z.B. WFS-4)";
CM_ SG_ 1716 VIN_6 "Initwert:
0x2D bei Fahrzeugen mit Wegfahrsperrengeneration >= 5 
0x58 bei Fahrzeugen mit Wegfahrsperrengeneration < 5 (z.B. WFS-4)";
CM_ SG_ 1716 VIN_7 "Initwert:
0x2D bei Fahrzeugen mit Wegfahrsperrengeneration >= 5 
0x58 bei Fahrzeugen mit Wegfahrsperrengeneration < 5 (z.B. WFS-4)";
CM_ SG_ 1716 VIN_8 "Initwert:
0x2D bei Fahrzeugen mit Wegfahrsperrengeneration >= 5 
0x58 bei Fahrzeugen mit Wegfahrsperrengeneration < 5 (z.B. WFS-4)";
CM_ SG_ 1716 VIN_9 "Initwert:
0x2D bei Fahrzeugen mit Wegfahrsperrengeneration >= 5 
0x58 bei Fahrzeugen mit Wegfahrsperrengeneration < 5 (z.B. WFS-4)";

CM_ SG_ 1702 BCM1_SRA_aktiv "Status Scheinwerferreinigungsanlage";
CM_ SG_ 1702 Heckwischer_Anforderung "Das Signal beschreibt die Anforderung an den Signalausgang im BCM2 zur Ansteuerung des Heckwischers.";
CM_ SG_ 1702 Waschen_vorne_aktiv "Status: Waschen vorne aktiv";
CM_ SG_ 1702 Wischer1_Wischgeschwindigkeit "aktuelle, durch Sensorik gemessene Wischgeschwindigkeit";
CM_ SG_ 1702 Wischer_Anzeigetext "Das Signal fordert einen Kombi-Pop-Up mit entsprechenden Texten an";
CM_ SG_ 1702 Wischer_vorne_aktiv "Status: Wischer vorne";
CM_ SG_ 1702 Wischer_vorne_blockiert "Blockade Wischer vorne (z.B. durch Schnee)";
CM_ SG_ 1702 Wischer_vorne_defekt "Fehlerstatus Wischer vorne (Anzeige im Kombi)";
CM_ SG_ 1702 Wischer_vorne_Normal "Wischer Front normal aktiv";
CM_ SG_ 1702 Wischer_vorne_Parklage "Wischer Front in Parklage";
CM_ SG_ 1702 Wischer_vorne_Schnell "Wischer vorne schnell aktiv";
CM_ SG_ 1702 Wischer_WH_PopUp_Anf "Anzeige von Wischerstufen im Kombi.";
CM_ SG_ 1702 Wischer_WH_Typ "Signal beinhaltet Lenkstockschaltertyp für grafische Anzeige im Kombi zur Wischerfunktion";
CM_ SG_ 1702 WWSs_01_alt "Veraltet Bit für die LIN-Botschaft WWSs_01.

Betroffene Signale:

Wischer_vorne_aktiv";

CM_ SG_ 1411 BCM_FH_Freigabe "Funktionsfreigabe Fensterheber";
CM_ SG_ 1411 BCM_HSK_Freigabe "Handschuhkastenfreigabe";
CM_ SG_ 1411 BCM_Komfortfkt_Freigabe "globale Freigabe der Komfortfunktion";
CM_ SG_ 1411 BCM_Tankklappensteller_Fehler "Fehler: nicht Funktionalität des Tankklappenstellers";
CM_ SG_ 1411 BCM_Verdeck_Freigabe "Freigabe Verdeckbetrieb
";
CM_ SG_ 1411 DWA_aktiv "Status DWA  aktiv";
CM_ SG_ 1411 FBS_IDG_in_Reichweite "Für elektrisch betätigte Türen und Klappen muss für eine Betätigung über Funk eine Reichweitenbegrenzung eingeführt werden. Diese Bit zeigt an, dass sich der Funkschlüssel innerhalb der geforderten Reichweite befindet";
CM_ SG_ 1411 FBS_Warn_Schluessel_Batt "Kombi Prio Warnung Schluessel Batterie
'Bitte Schlüsselbatterie wechseln!'";
CM_ SG_ 1411 FFB_Auf_Taste "Auf-Taste Funkschluessel

";
CM_ SG_ 1411 FFB_CarFinder "Car Finder Funktion (Blinken ohne zu entriegeln)";
CM_ SG_ 1411 FFB_HDF_Taste "HDF Taste am Funkschluessel
";
CM_ SG_ 1411 FFB_Komfortoeffnen "Komfortoeffnen Funk
";
CM_ SG_ 1411 FFB_Komfortschliessen "Komfortschliessen Funk
";
CM_ SG_ 1411 FFB_Panik_Taste "Panik Taste Funkschluessel
";
CM_ SG_ 1411 FFB_Zu_Taste "Zu-Taste Funkschluessel
";
CM_ SG_ 1411 HBFS_gesafet "HBFS Tuer gesafet.
Im Zustand Safe wird auch das Signal HBFS_verriegelt = 1 gesendet.";
CM_ SG_ 1411 HBFS_verriegelt "Verriegelungsstatus Tür";
CM_ SG_ 1411 HD_Hauptraste "SBL-Schloss (MQB/MLBevo): Drehfalle Heckdeckel
sonst (MQB): Hauptraste Heckdeckel";
CM_ SG_ 1411 HD_Vorraste "SBL_Schloss (MQB/MLBevo): Sperrklinke Heckdeckel
sonst (MQB): Vorraste Heckdeckel";
CM_ SG_ 1411 HFS_gesafet "HFS Tuer gesafet.
Im Zustand Safe wird auch das Signal HFS_verriegelt = 1 gesendet.";
CM_ SG_ 1411 HFS_verriegelt "HFS Tuer verriegelt";
CM_ SG_ 1411 IRUE_aktiv "Status Innenraumüberwachung
";
CM_ SG_ 1411 IRUE_Taster_Fkts_LED "Anforderung Funktions-LED IRUE-Taster (LED wird vom TSG angesteuert)
MQB: Bei Verbau eines einzelnen Taster zur Deaktivierung von IRUE und NGS wird dieses Signal zur Ansteuerung der Funktions-LED gesendet.";
CM_ SG_ 1411 VIP_Sensor_STSG_HBFS_betaetigt "Schiebetürlauf HBFS wurde durch VIP angefordert und als berechtigt eingestuft.";
CM_ SG_ 1411 VIP_Sensor_STSG_HFS_betaetigt "Schiebetürlauf HFS wurde durch VIP angefordert und als berechtigt eingestuft.";
CM_ SG_ 1411 ZV_Anf_Challenge_Auth "Anforderung an alle beteiligten Steuergeräte die Challenge an den ZV-Master zu senden.";
CM_ SG_ 1411 ZV_BT_offen "gespiegeltes Bit BT_Tuer_geoeffnet TSG_BT_1 Botschaft";
CM_ SG_ 1411 ZV_Einzeltuerentriegelung "Einzeltürentriegelung ZV
";
CM_ SG_ 1411 ZV_eRWK_Umfeld_Pruefung "Anforderung an PDC/PLA im eRWK-Modus eine Umfeldprüfung durchzuführen";
CM_ SG_ 1411 ZV_FT_offen "gespiegeltes Bit FT_Tuer_geoeffnet TSG_FT_1 Botschaft";
CM_ SG_ 1411 ZV_gesafet_extern_ist "Istzustand: Fahrzeug aussen gesafet
";
CM_ SG_ 1411 ZV_gesafet_extern_soll "Sollzustand: Fahrzeug gesafet extern
";
CM_ SG_ 1411 ZV_HBFS_offen "gespiegeltes Bit HBFS_Tuer_geoeffnet TSG_HBFS_1 Botschaft";
CM_ SG_ 1411 ZV_HD_offen "Status Heckdeckel
";
CM_ SG_ 1411 ZV_Heckeinzelentriegelung "Heckdeckeleinzelentriegelung";
CM_ SG_ 1411 ZV_HFS_offen "gespiegeltes Bit HFS_Tuer_geoeffnet TSG_HFS_1 Botschaft";
CM_ SG_ 1411 ZV_HS_offen "Status Heckscheibe
";
CM_ SG_ 1411 ZV_ist_Zustand_verfuegbar "Verfügbarkeit IST-Zustand ZV

";
CM_ SG_ 1411 ZV_Oeffnungsmodus "Konfigurierter Oeffnungsmodus fuer ZV:
0 = globale Oeffnung (alle Tueren)
1 = ZV mit Einzeltuerentriegelung (FFB - nur Fahrertuer, Kessy - nur bediente Tuer)
2 = ZV individuell selektive Oeffnung (FFB - Fahrerseite, Kessy - bediente Tuer + Fahrertuer)";
CM_ SG_ 1411 ZV_Rollo_auf "Komfortöffnen des Dachrollos";
CM_ SG_ 1411 ZV_Rollo_zu "Komfortschließen des Dachrollos";
CM_ SG_ 1411 ZV_SAD_auf "Komfortöffnen des Schiebeausstelldaches";
CM_ SG_ 1411 ZV_SAD_zu "Komfortschließen des Schiebeausstelldaches";
CM_ SG_ 1411 ZV_SafeFunktion_aktiv "Statusübermittlung ob die Safe Funktion im Fzg. aktiv ist. Das Kombi benötigt das Signal, um den Text Safelock aktiv anzuzeigen. ";
CM_ SG_ 1411 ZV_Schluessel_Zugang "aktuelle Funkschlüsselnummer";
CM_ SG_ 1411 ZV_STSG_Crashzustand "Statusübermittlung ob der Crashzustand der Schiebetüren dauerhaft im Fzg. aktiv ist. Das Kombi benötigt das Signal, um die Meldung anzuzeigen.";
CM_ SG_ 1411 ZV_STSG_eKiSi_defekt "Statusübermittlung ob die elektronische Kindersicherung der Schiebetüren im Fzg. defekt ist. Das Kombi benötigt das Signal, um die Meldung anzuzeigen.";
CM_ SG_ 1411 ZV_STSG_HBFS_Anf "Die ZV fordert einen Lauf bzw. Stopp der Schiebetür an.";
CM_ SG_ 1411 ZV_STSG_HFS_Anf "Die ZV fordert einen Lauf bzw. Stopp der Schiebetür an.";
CM_ SG_ 1411 ZV_Tankklappe_offen "Öffnungsstatus der Tankklappe";
CM_ SG_ 1411 ZV_verriegeln_Anf "Gesammelte externe ZV-Verriegelungsanforderung des Kunden (z. B. zur Aktivierung der Anzeige des Ladezustands über Aussenlicht).";
CM_ SG_ 1411 ZV_verriegelt_extern_ist "Istzustand: Verriegelung Fahrzeug aussen
";
CM_ SG_ 1411 ZV_verriegelt_extern_soll "Sollzustand: Verriegelung Fahrzeug aussen
";
CM_ SG_ 1411 ZV_verriegelt_intern_ist "Istzustand: Verriegelung Fahrzeug innen
";
CM_ SG_ 1411 ZV_verriegelt_intern_soll "Sollzustand: Verriegelung Fahrzeug innen
";
CM_ SG_ 1411 ZV_verriegelt_soll "Fahrzeug Gesamtverriegelungsstatus Sollzustand für Ladestecker- und Ladeklappenverriegelung. ";
BA_DEF_REL_ BU_SG_REL_  "GenSigTimeoutTime" INT 0 65535;
BA_DEF_ BO_  "DiagRequest" ENUM "No", "Yes";
BA_DEF_ BO_  "DiagResponse" ENUM "No", "Yes";
BA_DEF_ BO_  "DiagState" ENUM "No", "Yes";
BA_DEF_ BO_  "GenMsgChkConstant" HEX 0 4095;
BA_DEF_ BO_  "GenMsgCycleTime" INT 0 65535;
BA_DEF_ BO_  "GenMsgCycleTimeFast" INT 0 65535;
BA_DEF_ BO_  "GenMsgDelayTime" INT 0 100000;
BA_DEF_ BO_  "GenMsgILSupport" ENUM "No", "Yes";
BA_DEF_ BO_  "GenMsgNrOfRepetition" INT 0 100;
BA_DEF_ BO_  "GenMsgPDUConstants" STRING;
BA_DEF_ BO_  "GenMsgSendType" ENUM "Cyclic", "not_used", "not_used", "not_used", "not_used", "not_used", "not_used", "IfActive", "NoMsgSendType";
BA_DEF_ BO_  "GenMsgStartDelayTime" INT 0 100000;
BA_DEF_ BO_  "NmMessage" ENUM "No", "Yes";
BA_DEF_ BO_  "NmhMessage" ENUM "No", "Yes";
BA_DEF_ BO_  "MsgType" ENUM "Application", "NM ", "NMH", "TP2.0", "ISO-TP ", "BAP", "EID", "KS", "XCP_PRE_CONFIGURED", "XCP_RUNTIME_CONFIGURED";
BA_DEF_ BO_  "VAGTP20_API" HEX 0 255;
BA_DEF_ BO_  "VAGTP20_DynConnection" ENUM "No", "Yes";
BA_DEF_ BO_  "VAGTP20_DynSetup" ENUM "No", "Yes";
BA_DEF_ BO_  "VAGTP20_StatConnection" ENUM "No", "Yes";
BA_DEF_ BO_  "CANFD_BRS" ENUM "0", "1";
BA_DEF_ BO_  "VFrameFormat" ENUM "StandardCAN", "ExtendedCAN", "reserved", "reserved", "reserved", "reserved", "reserved", "reserved", "reserved", "reserved", "reserved", "reserved", "reserved", "reserved", "StandardCAN_FD", "ExtendedCAN_FD";
BA_DEF_ SG_  "GenSigActiveRepetitions" INT -2147483648 2147483647;
BA_DEF_ SG_  "GenSigInactiveValue" INT -2147483648 2147483647;
BA_DEF_ SG_  "GenSigSendType" ENUM "Cyclic", "OnWrite", "OnWriteWithRepetition", "OnChange", "OnChangeWithRepetition", "IfActive", "IfActiveWithRepetition", "NoSigSendType", "OnChangeAndIfActive", "OnChangeAndIfActiveWithRepetition";
BA_DEF_ SG_  "GenSigStartValue" INT -2147483648 2147483647;
BA_DEF_ SG_  "NWM-WakeupAllowed" ENUM "No", "Yes";
BA_DEF_ SG_  "GenSigFuncType" ENUM "NoFunction", "MsgCounter", "CRC-8", "XOR", "XOR-2", "DatedBit", "SW-Kl15", "CHK", "Constant", "Protocol", "CRC-8-SAE_J1850", "CRC-32", "DataLength", "DataID", "MsgCounter16", "SOK-Signatur", "Cluster";
BA_DEF_ SG_  "GenSigSwitchedByIgnition" ENUM "No", "Yes";
BA_DEF_ SG_  "Fehlerwert" HEX 0 2147483647;
BA_DEF_ SG_  "GenSigMissingSourceValue" HEX 0 2147483647;
BA_DEF_DEF_REL_  "GenSigTimeoutTime" 0;
BA_DEF_DEF_  "DiagRequest" "No";
BA_DEF_DEF_  "DiagResponse" "No";
BA_DEF_DEF_  "DiagState" "No";
BA_DEF_DEF_  "GenMsgChkConstant" 0;
BA_DEF_DEF_  "GenMsgCycleTime" 0;
BA_DEF_DEF_  "GenMsgCycleTimeFast" 0;
BA_DEF_DEF_  "GenMsgDelayTime" 0;
BA_DEF_DEF_  "GenMsgILSupport" "No";
BA_DEF_DEF_  "GenMsgNrOfRepetition" 0;
BA_DEF_DEF_  "GenMsgPDUConstants" "";
BA_DEF_DEF_  "GenMsgSendType" "NoMsgSendType";
BA_DEF_DEF_  "GenMsgStartDelayTime" 0;
BA_DEF_DEF_  "NmMessage" "No";
BA_DEF_DEF_  "NmhMessage" "No";
BA_DEF_DEF_  "MsgType" "Application";
BA_DEF_DEF_  "VAGTP20_API" 0;
BA_DEF_DEF_  "VAGTP20_DynConnection" "No";
BA_DEF_DEF_  "VAGTP20_DynSetup" "No";
BA_DEF_DEF_  "VAGTP20_StatConnection" "No";
BA_DEF_DEF_  "CANFD_BRS" "1";
BA_DEF_DEF_  "VFrameFormat" "StandardCAN";
BA_DEF_DEF_  "GenSigActiveRepetitions" 0;
BA_DEF_DEF_  "GenSigInactiveValue" 0;
BA_DEF_DEF_  "GenSigSendType" "NoSigSendType";
BA_DEF_DEF_  "GenSigStartValue" 0;
BA_DEF_DEF_  "NWM-WakeupAllowed" "No";
BA_DEF_DEF_  "GenSigFuncType" "NoFunction";
BA_DEF_DEF_  "GenSigSwitchedByIgnition" "Yes";
BA_DEF_DEF_  "Fehlerwert" 0;
BA_DEF_DEF_  "GenSigMissingSourceValue" 0;
BA_ "GenMsgCycleTime" BO_ 1413 1000;
BA_ "GenMsgDelayTime" BO_ 1413 10;
BA_ "GenMsgILSupport" BO_ 1413 1;
BA_ "GenMsgSendType" BO_ 1413 0;
BA_ "VFrameFormat" BO_ 1413 14;
BA_ "GenMsgCycleTime" BO_ 1001 100;
BA_ "GenMsgILSupport" BO_ 1001 1;
BA_ "GenMsgSendType" BO_ 1001 0;
BA_ "VFrameFormat" BO_ 1001 14;
BA_ "GenMsgCycleTime" BO_ 2527679738 200;
BA_ "GenMsgILSupport" BO_ 2527679738 1;
BA_ "GenMsgSendType" BO_ 2527679738 0;
BA_ "VFrameFormat" BO_ 2527679738 15;
BA_ "GenMsgCycleTime" BO_ 1447 1000;
BA_ "GenMsgCycleTimeFast" BO_ 1447 100;
BA_ "GenMsgDelayTime" BO_ 1447 50;
BA_ "GenMsgILSupport" BO_ 1447 1;
BA_ "GenMsgSendType" BO_ 1447 0;
BA_ "VFrameFormat" BO_ 1447 14;
BA_ "GenMsgCycleTime" BO_ 977 100;
BA_ "GenMsgDelayTime" BO_ 977 20;
BA_ "GenMsgILSupport" BO_ 977 1;
BA_ "GenMsgSendType" BO_ 977 0;
BA_ "VFrameFormat" BO_ 977 14;
BA_ "GenMsgCycleTime" BO_ 976 100;
BA_ "GenMsgDelayTime" BO_ 976 20;
BA_ "GenMsgILSupport" BO_ 976 1;
BA_ "GenMsgSendType" BO_ 976 0;
BA_ "VFrameFormat" BO_ 976 14;
BA_ "GenMsgCycleTime" BO_ 975 100;
BA_ "GenMsgDelayTime" BO_ 975 20;
BA_ "GenMsgILSupport" BO_ 975 1;
BA_ "GenMsgSendType" BO_ 975 0;
BA_ "VFrameFormat" BO_ 975 14;
BA_ "GenMsgCycleTime" BO_ 974 100;
BA_ "GenMsgDelayTime" BO_ 974 20;
BA_ "GenMsgILSupport" BO_ 974 1;
BA_ "GenMsgSendType" BO_ 974 0;
BA_ "VFrameFormat" BO_ 974 14;
BA_ "GenMsgCycleTime" BO_ 1718 1000;
BA_ "GenMsgILSupport" BO_ 1718 1;
BA_ "GenMsgSendType" BO_ 1718 0;
BA_ "VFrameFormat" BO_ 1718 14;
BA_ "GenMsgCycleTime" BO_ 2463978710 100;
BA_ "GenMsgCycleTimeFast" BO_ 2463978710 10;
BA_ "GenMsgDelayTime" BO_ 2463978710 10;
BA_ "GenMsgILSupport" BO_ 2463978710 1;
BA_ "GenMsgNrOfRepetition" BO_ 2463978710 5;
BA_ "GenMsgPDUConstants" BO_ 2463978710 "0xf3,0xbb,0x4c,0x48,0x05,0x08,0x69,0xc8,0x60,0x76,0x27,0x02,0x3a,0xa8,0x32,0x51";
BA_ "GenMsgSendType" BO_ 2463978710 0;
BA_ "VFrameFormat" BO_ 2463978710 15;
BA_ "GenMsgCycleTime" BO_ 995 100;
BA_ "GenMsgCycleTimeFast" BO_ 995 50;
BA_ "GenMsgDelayTime" BO_ 995 50;
BA_ "GenMsgILSupport" BO_ 995 1;
BA_ "GenMsgNrOfRepetition" BO_ 995 5;
BA_ "GenMsgSendType" BO_ 995 0;
BA_ "VFrameFormat" BO_ 995 14;
BA_ "GenMsgCycleTime" BO_ 1716 200;
BA_ "GenMsgILSupport" BO_ 1716 1;
BA_ "GenMsgSendType" BO_ 1716 0;
BA_ "VFrameFormat" BO_ 1716 14;
BA_ "GenMsgCycleTime" BO_ 1702 1000;
BA_ "GenMsgDelayTime" BO_ 1702 50;
BA_ "GenMsgILSupport" BO_ 1702 1;
BA_ "GenMsgSendType" BO_ 1702 0;
BA_ "VFrameFormat" BO_ 1702 14;
BA_ "GenMsgCycleTime" BO_ 1411 200;
BA_ "GenMsgCycleTimeFast" BO_ 1411 50;
BA_ "GenMsgDelayTime" BO_ 1411 20;
BA_ "GenMsgILSupport" BO_ 1411 1;
BA_ "GenMsgNrOfRepetition" BO_ 1411 3;
BA_ "GenMsgSendType" BO_ 1411 0;
BA_ "VFrameFormat" BO_ 1411 14;
BA_ "GenSigSendType" SG_ 1413 GW_KD_Fehler 3;
BA_ "GenSigSendType" SG_ 1413 SI_BUS_01 3;
BA_ "GenSigStartValue" SG_ 1413 SI_BUS_01 1;
BA_ "GenSigSwitchedByIgnition" SG_ 1413 SI_BUS_01 0;
BA_ "GenSigSendType" SG_ 1413 SI_BUS_02 3;
BA_ "GenSigStartValue" SG_ 1413 SI_BUS_02 1;
BA_ "GenSigSwitchedByIgnition" SG_ 1413 SI_BUS_02 0;
BA_ "GenSigSendType" SG_ 1413 SI_BUS_03 3;
BA_ "GenSigStartValue" SG_ 1413 SI_BUS_03 1;
BA_ "GenSigSwitchedByIgnition" SG_ 1413 SI_BUS_03 0;
BA_ "GenSigSendType" SG_ 1413 SI_BUS_04 3;
BA_ "GenSigStartValue" SG_ 1413 SI_BUS_04 1;
BA_ "GenSigSwitchedByIgnition" SG_ 1413 SI_BUS_04 0;
BA_ "GenSigSendType" SG_ 1413 SI_BUS_05 3;
BA_ "GenSigStartValue" SG_ 1413 SI_BUS_05 1;
BA_ "GenSigSwitchedByIgnition" SG_ 1413 SI_BUS_05 0;
BA_ "GenSigSendType" SG_ 1413 SI_BUS_06 3;
BA_ "GenSigStartValue" SG_ 1413 SI_BUS_06 1;
BA_ "GenSigSwitchedByIgnition" SG_ 1413 SI_BUS_06 0;
BA_ "GenSigSendType" SG_ 1413 SI_BUS_07 3;
BA_ "GenSigStartValue" SG_ 1413 SI_BUS_07 1;
BA_ "GenSigSwitchedByIgnition" SG_ 1413 SI_BUS_07 0;
BA_ "GenSigSendType" SG_ 1413 SI_BUS_08 3;
BA_ "GenSigStartValue" SG_ 1413 SI_BUS_08 1;
BA_ "GenSigSwitchedByIgnition" SG_ 1413 SI_BUS_08 0;
BA_ "GenSigSendType" SG_ 1413 SI_BUS_09 3;
BA_ "GenSigStartValue" SG_ 1413 SI_BUS_09 1;
BA_ "GenSigSwitchedByIgnition" SG_ 1413 SI_BUS_09 0;
BA_ "GenSigSendType" SG_ 1413 SI_BUS_10 3;
BA_ "GenSigStartValue" SG_ 1413 SI_BUS_10 1;
BA_ "GenSigSwitchedByIgnition" SG_ 1413 SI_BUS_10 0;
BA_ "GenSigSendType" SG_ 1413 SI_BUS_11 3;
BA_ "GenSigStartValue" SG_ 1413 SI_BUS_11 1;
BA_ "GenSigSwitchedByIgnition" SG_ 1413 SI_BUS_11 0;
BA_ "GenSigSendType" SG_ 1413 SI_BUS_12 3;
BA_ "GenSigStartValue" SG_ 1413 SI_BUS_12 1;
BA_ "GenSigSwitchedByIgnition" SG_ 1413 SI_BUS_12 0;
BA_ "GenSigSendType" SG_ 1413 SI_BUS_13 3;
BA_ "GenSigStartValue" SG_ 1413 SI_BUS_13 1;
BA_ "GenSigSwitchedByIgnition" SG_ 1413 SI_BUS_13 0;
BA_ "GenSigSendType" SG_ 1413 SI_BUS_14 3;
BA_ "GenSigStartValue" SG_ 1413 SI_BUS_14 1;
BA_ "GenSigSwitchedByIgnition" SG_ 1413 SI_BUS_14 0;
BA_ "GenSigSendType" SG_ 1413 SI_BUS_15 3;
BA_ "GenSigStartValue" SG_ 1413 SI_BUS_15 1;
BA_ "GenSigSwitchedByIgnition" SG_ 1413 SI_BUS_15 0;
BA_ "GenSigSendType" SG_ 1413 SI_Bus_Identifikation 0;
BA_ "GenSigSwitchedByIgnition" SG_ 1413 SI_Bus_Identifikation 0;
BA_ "GenSigSendType" SG_ 1413 SI_CAB_V14 3;
BA_ "GenSigSwitchedByIgnition" SG_ 1413 SI_CAB_V14 0;
BA_ "GenSigSendType" SG_ 1413 SI_Diagnose_Aktiv 3;
BA_ "GenSigSwitchedByIgnition" SG_ 1413 SI_Diagnose_Aktiv 0;
BA_ "GenSigSendType" SG_ 1413 SI_NWDF 3;
BA_ "GenSigSwitchedByIgnition" SG_ 1413 SI_NWDF 0;
BA_ "GenSigSendType" SG_ 1413 SI_NWDF_30 3;
BA_ "GenSigSwitchedByIgnition" SG_ 1413 SI_NWDF_30 0;
BA_ "GenSigSendType" SG_ 1413 SI_NWDF_gueltig 3;
BA_ "GenSigFuncType" SG_ 1413 SI_NWDF_gueltig 8;
BA_ "GenSigSwitchedByIgnition" SG_ 1413 SI_NWDF_gueltig 0;
BA_ "GenSigSendType" SG_ 1413 SI_P_Mode 3;
BA_ "GenSigSwitchedByIgnition" SG_ 1413 SI_P_Mode 0;
BA_ "GenSigSendType" SG_ 1413 SI_P_Mode_gueltig 3;
BA_ "GenSigSwitchedByIgnition" SG_ 1413 SI_P_Mode_gueltig 0;
BA_ "GenSigSendType" SG_ 1413 SI_QRS_Mode 3;
BA_ "GenSigSwitchedByIgnition" SG_ 1413 SI_QRS_Mode 0;
BA_ "GenSigSendType" SG_ 1413 SI_Sammel_SG_Fehler 0;
BA_ "GenSigStartValue" SG_ 1413 SI_Sammel_SG_Fehler 63;
BA_ "GenSigSwitchedByIgnition" SG_ 1413 SI_Sammel_SG_Fehler 0;
BA_ "GenSigSendType" SG_ 1413 SI_Sammelfehler 3;
BA_ "GenSigSwitchedByIgnition" SG_ 1413 SI_Sammelfehler 0;
BA_ "GenSigSendType" SG_ 1413 SI_T_Mode 3;
BA_ "GenSigSwitchedByIgnition" SG_ 1413 SI_T_Mode 0;
BA_ "GenSigSendType" SG_ 1413 SI_T_Schutz 3;
BA_ "GenSigSwitchedByIgnition" SG_ 1413 SI_T_Schutz 0;
BA_ "GenSigSendType" SG_ 1001 Thermo_Pred_Innen_Kunde_Anf 0;
BA_ "GenSigSwitchedByIgnition" SG_ 1001 Thermo_Pred_Innen_Kunde_Anf 0;
BA_ "GenSigSendType" SG_ 1001 Thermo_Pred_Innen_System_Anf 0;
BA_ "GenSigSwitchedByIgnition" SG_ 1001 Thermo_Pred_Innen_System_Anf 0;
BA_ "GenSigSendType" SG_ 1001 Thermo_Pred_P_dyn_Innen 0;
BA_ "GenSigStartValue" SG_ 1001 Thermo_Pred_P_dyn_Innen 2046;
BA_ "GenSigSwitchedByIgnition" SG_ 1001 Thermo_Pred_P_dyn_Innen 0;
BA_ "Fehlerwert" SG_ 1001 Thermo_Pred_P_dyn_Innen 2047;
BA_ "GenSigSendType" SG_ 1001 Thermo_Pred_P_stat_Innen 0;
BA_ "GenSigStartValue" SG_ 1001 Thermo_Pred_P_stat_Innen 2046;
BA_ "GenSigSwitchedByIgnition" SG_ 1001 Thermo_Pred_P_stat_Innen 0;
BA_ "Fehlerwert" SG_ 1001 Thermo_Pred_P_stat_Innen 2047;
BA_ "GenSigSendType" SG_ 1001 Thermo_Pred_T_dyn_Innen 0;
BA_ "GenSigStartValue" SG_ 1001 Thermo_Pred_T_dyn_Innen 254;
BA_ "GenSigSwitchedByIgnition" SG_ 1001 Thermo_Pred_T_dyn_Innen 0;
BA_ "Fehlerwert" SG_ 1001 Thermo_Pred_T_dyn_Innen 255;
BA_ "GenSigSendType" SG_ 1001 Thermo_Verbrauch_BTL 0;
BA_ "GenSigSwitchedByIgnition" SG_ 1001 Thermo_Verbrauch_BTL 0;
BA_ "GenSigSendType" SG_ 1001 Thermo_Verbrauch_BTL_Ueberlauf 0;
BA_ "GenSigSwitchedByIgnition" SG_ 1001 Thermo_Verbrauch_BTL_Ueberlauf 0;
BA_ "GenSigSendType" SG_ 1001 Thermo_Verbrauch_Innen 0;
BA_ "GenSigSwitchedByIgnition" SG_ 1001 Thermo_Verbrauch_Innen 0;
BA_ "GenSigSendType" SG_ 1001 Thermo_Verbrauch_Innen_Ueberlauf 0;
BA_ "GenSigSwitchedByIgnition" SG_ 1001 Thermo_Verbrauch_Innen_Ueberlauf 0;
BA_ "GenSigSendType" SG_ 2527679738 Thermo_Pred_P_dyn_In_Efficien1 0;
BA_ "GenSigStartValue" SG_ 2527679738 Thermo_Pred_P_dyn_In_Efficien1 2046;
BA_ "GenSigSwitchedByIgnition" SG_ 2527679738 Thermo_Pred_P_dyn_In_Efficien1 0;
BA_ "Fehlerwert" SG_ 2527679738 Thermo_Pred_P_dyn_In_Efficien1 2047;
BA_ "GenSigSendType" SG_ 2527679738 Thermo_Pred_P_dyn_In_Efficien2 0;
BA_ "GenSigStartValue" SG_ 2527679738 Thermo_Pred_P_dyn_In_Efficien2 2046;
BA_ "GenSigSwitchedByIgnition" SG_ 2527679738 Thermo_Pred_P_dyn_In_Efficien2 0;
BA_ "Fehlerwert" SG_ 2527679738 Thermo_Pred_P_dyn_In_Efficien2 2047;
BA_ "GenSigSendType" SG_ 2527679738 Thermo_Pred_P_dyn_In_Standard 0;
BA_ "GenSigStartValue" SG_ 2527679738 Thermo_Pred_P_dyn_In_Standard 2046;
BA_ "GenSigSwitchedByIgnition" SG_ 2527679738 Thermo_Pred_P_dyn_In_Standard 0;
BA_ "Fehlerwert" SG_ 2527679738 Thermo_Pred_P_dyn_In_Standard 2047;
BA_ "GenSigSendType" SG_ 2527679738 Thermo_Pred_P_stat_In_Efficien1 0;
BA_ "GenSigStartValue" SG_ 2527679738 Thermo_Pred_P_stat_In_Efficien1 2046;
BA_ "GenSigSwitchedByIgnition" SG_ 2527679738 Thermo_Pred_P_stat_In_Efficien1 0;
BA_ "Fehlerwert" SG_ 2527679738 Thermo_Pred_P_stat_In_Efficien1 2047;
BA_ "GenSigSendType" SG_ 2527679738 Thermo_Pred_P_stat_In_Efficien2 0;
BA_ "GenSigStartValue" SG_ 2527679738 Thermo_Pred_P_stat_In_Efficien2 2046;
BA_ "GenSigSwitchedByIgnition" SG_ 2527679738 Thermo_Pred_P_stat_In_Efficien2 0;
BA_ "Fehlerwert" SG_ 2527679738 Thermo_Pred_P_stat_In_Efficien2 2047;
BA_ "GenSigSendType" SG_ 2527679738 Thermo_Pred_P_stat_In_Standard 0;
BA_ "GenSigStartValue" SG_ 2527679738 Thermo_Pred_P_stat_In_Standard 2046;
BA_ "GenSigSwitchedByIgnition" SG_ 2527679738 Thermo_Pred_P_stat_In_Standard 0;
BA_ "Fehlerwert" SG_ 2527679738 Thermo_Pred_P_stat_In_Standard 2047;
BA_ "GenSigSendType" SG_ 2527679738 Thermo_Pred_T_dyn_In_Efficien1 0;
BA_ "GenSigStartValue" SG_ 2527679738 Thermo_Pred_T_dyn_In_Efficien1 254;
BA_ "GenSigSwitchedByIgnition" SG_ 2527679738 Thermo_Pred_T_dyn_In_Efficien1 0;
BA_ "Fehlerwert" SG_ 2527679738 Thermo_Pred_T_dyn_In_Efficien1 255;
BA_ "GenSigSendType" SG_ 2527679738 Thermo_Pred_T_dyn_In_Efficien2 0;
BA_ "GenSigStartValue" SG_ 2527679738 Thermo_Pred_T_dyn_In_Efficien2 254;
BA_ "GenSigSwitchedByIgnition" SG_ 2527679738 Thermo_Pred_T_dyn_In_Efficien2 0;
BA_ "Fehlerwert" SG_ 2527679738 Thermo_Pred_T_dyn_In_Efficien2 255;
BA_ "GenSigSendType" SG_ 2527679738 Thermo_Pred_T_dyn_In_Standard 0;
BA_ "GenSigStartValue" SG_ 2527679738 Thermo_Pred_T_dyn_In_Standard 254;
BA_ "GenSigSwitchedByIgnition" SG_ 2527679738 Thermo_Pred_T_dyn_In_Standard 0;
BA_ "Fehlerwert" SG_ 2527679738 Thermo_Pred_T_dyn_In_Standard 255;
BA_ "GenSigSendType" SG_ 1447 bCall_active 3;
BA_ "GenSigSwitchedByIgnition" SG_ 1447 bCall_active 0;
BA_ "GenSigSendType" SG_ 1447 eCall_Funktionsstatus 0;
BA_ "GenSigSwitchedByIgnition" SG_ 1447 eCall_Funktionsstatus 0;
BA_ "GenSigSendType" SG_ 1447 eCall_Funktionsstatus_02 0;
BA_ "GenSigStartValue" SG_ 1447 eCall_Funktionsstatus_02 7;
BA_ "GenSigSwitchedByIgnition" SG_ 1447 eCall_Funktionsstatus_02 0;
BA_ "GenSigSendType" SG_ 1447 eCall_MCC 0;
BA_ "GenSigSwitchedByIgnition" SG_ 1447 eCall_MCC 0;
BA_ "GenSigSendType" SG_ 1447 eCall_Mute_Anf 3;
BA_ "GenSigSwitchedByIgnition" SG_ 1447 eCall_Mute_Anf 0;
BA_ "GenSigSendType" SG_ 1447 FaceRec_Enroll_Challenge_Request 3;
BA_ "GenSigSwitchedByIgnition" SG_ 1447 FaceRec_Enroll_Challenge_Request 0;
BA_ "GenSigSendType" SG_ 1447 FoD_Anz_Funktionsabschaltung 3;
BA_ "GenSigSwitchedByIgnition" SG_ 1447 FoD_Anz_Funktionsabschaltung 0;
BA_ "GenSigSendType" SG_ 1447 iCall_active 3;
BA_ "GenSigSwitchedByIgnition" SG_ 1447 iCall_active 0;
BA_ "GenSigSendType" SG_ 1447 MOD_Energie_Anf 0;
BA_ "GenSigSwitchedByIgnition" SG_ 1447 MOD_Energie_Anf 0;
BA_ "Fehlerwert" SG_ 1447 MOD_Energie_Anf 3;
BA_ "GenSigSendType" SG_ 1447 MOD_Request_ServiceKey 3;
BA_ "GenSigSwitchedByIgnition" SG_ 1447 MOD_Request_ServiceKey 0;
BA_ "GenSigSendType" SG_ 1447 ORU_KombiTimer 0;
BA_ "GenSigSwitchedByIgnition" SG_ 1447 ORU_KombiTimer 0;
BA_ "GenSigSendType" SG_ 1447 TM_Door_Lock 5;
BA_ "GenSigSwitchedByIgnition" SG_ 1447 TM_Door_Lock 0;
BA_ "GenSigSendType" SG_ 1447 TM_Door_Unlock 5;
BA_ "GenSigSwitchedByIgnition" SG_ 1447 TM_Door_Unlock 0;
BA_ "GenSigSendType" SG_ 1447 TM_Nur_Hupen 5;
BA_ "GenSigSwitchedByIgnition" SG_ 1447 TM_Nur_Hupen 0;
BA_ "GenSigSendType" SG_ 1447 TM_Panik_Alarm 5;
BA_ "GenSigSwitchedByIgnition" SG_ 1447 TM_Panik_Alarm 0;
BA_ "GenSigSendType" SG_ 1447 TM_Spiegel_Anklappen 5;
BA_ "GenSigSwitchedByIgnition" SG_ 1447 TM_Spiegel_Anklappen 0;
BA_ "GenSigSendType" SG_ 1447 TM_Warnblinken 5;
BA_ "GenSigSwitchedByIgnition" SG_ 1447 TM_Warnblinken 0;
BA_ "GenSigSendType" SG_ 1447 TM_ZV_Signatur 0;
BA_ "GenSigSwitchedByIgnition" SG_ 1447 TM_ZV_Signatur 0;
BA_ "GenSigSendType" SG_ 977 ASW_Warnung_aktiv_BFS 3;
BA_ "GenSigSwitchedByIgnition" SG_ 977 ASW_Warnung_aktiv_BFS 0;
BA_ "GenSigSendType" SG_ 977 BFS_Status_eTAG 0;
BA_ "GenSigSwitchedByIgnition" SG_ 977 BFS_Status_eTAG 0;
BA_ "Fehlerwert" SG_ 977 BFS_Status_eTAG 3;
BA_ "GenSigSendType" SG_ 977 BT_ASW_HMI_defekt 0;
BA_ "GenSigSwitchedByIgnition" SG_ 977 BT_ASW_HMI_defekt 0;
BA_ "GenSigSendType" SG_ 977 BT_EC_Spiegel_Helligkeit 3;
BA_ "GenSigSwitchedByIgnition" SG_ 977 BT_EC_Spiegel_Helligkeit 0;
BA_ "GenSigSendType" SG_ 977 BT_FH_Bew_hoch 3;
BA_ "GenSigSwitchedByIgnition" SG_ 977 BT_FH_Bew_hoch 0;
BA_ "GenSigSendType" SG_ 977 BT_FH_Bew_tief 3;
BA_ "GenSigSwitchedByIgnition" SG_ 977 BT_FH_Bew_tief 0;
BA_ "GenSigSendType" SG_ 977 BT_FH_Block 3;
BA_ "GenSigSwitchedByIgnition" SG_ 977 BT_FH_Block 0;
BA_ "GenSigSendType" SG_ 977 BT_FH_Fang 3;
BA_ "GenSigSwitchedByIgnition" SG_ 977 BT_FH_Fang 0;
BA_ "GenSigSendType" SG_ 977 BT_FH_normiert 3;
BA_ "GenSigSwitchedByIgnition" SG_ 977 BT_FH_normiert 0;
BA_ "GenSigSendType" SG_ 977 BT_FH_Oeffnung 3;
BA_ "GenSigSwitchedByIgnition" SG_ 977 BT_FH_Oeffnung 0;
BA_ "GenSigSendType" SG_ 977 BT_FH_Pos_oben 3;
BA_ "GenSigSwitchedByIgnition" SG_ 977 BT_FH_Pos_oben 0;
BA_ "GenSigSendType" SG_ 977 BT_FH_S_AutoHoch 3;
BA_ "GenSigSwitchedByIgnition" SG_ 977 BT_FH_S_AutoHoch 0;
BA_ "GenSigSendType" SG_ 977 BT_FH_S_AutoTief 3;
BA_ "GenSigSwitchedByIgnition" SG_ 977 BT_FH_S_AutoTief 0;
BA_ "GenSigSendType" SG_ 977 BT_FH_S_ManHoch 3;
BA_ "GenSigSwitchedByIgnition" SG_ 977 BT_FH_S_ManHoch 0;
BA_ "GenSigSendType" SG_ 977 BT_FH_S_ManTief 3;
BA_ "GenSigSwitchedByIgnition" SG_ 977 BT_FH_S_ManTief 0;
BA_ "GenSigSendType" SG_ 977 BT_FH_Thermo 3;
BA_ "GenSigSwitchedByIgnition" SG_ 977 BT_FH_Thermo 0;
BA_ "GenSigSendType" SG_ 977 BT_gesafet 3;
BA_ "GenSigSwitchedByIgnition" SG_ 977 BT_gesafet 0;
BA_ "GenSigSendType" SG_ 977 BT_Kisi_Fehler 3;
BA_ "GenSigSwitchedByIgnition" SG_ 977 BT_Kisi_Fehler 0;
BA_ "Fehlerwert" SG_ 977 BT_Kisi_Fehler 1;
BA_ "GenSigSendType" SG_ 977 BT_Lock_Taster 3;
BA_ "GenSigSwitchedByIgnition" SG_ 977 BT_Lock_Taster 0;
BA_ "GenSigSendType" SG_ 977 BT_Lock_Taster_inv 3;
BA_ "GenSigSwitchedByIgnition" SG_ 977 BT_Lock_Taster_inv 0;
BA_ "GenSigSendType" SG_ 977 BT_Lock_Unlock_Taster 3;
BA_ "GenSigSwitchedByIgnition" SG_ 977 BT_Lock_Unlock_Taster 0;
BA_ "GenSigSendType" SG_ 977 BT_Oben_Block_erw 3;
BA_ "GenSigSwitchedByIgnition" SG_ 977 BT_Oben_Block_erw 0;
BA_ "GenSigSendType" SG_ 977 BT_Schliesstaster 3;
BA_ "GenSigSwitchedByIgnition" SG_ 977 BT_Schliesstaster 0;
BA_ "GenSigSendType" SG_ 977 BT_Schluesselschalter_auf 3;
BA_ "GenSigSwitchedByIgnition" SG_ 977 BT_Schluesselschalter_auf 0;
BA_ "GenSigSendType" SG_ 977 BT_Schluesselschalter_zu 3;
BA_ "GenSigSwitchedByIgnition" SG_ 977 BT_Schluesselschalter_zu 0;
BA_ "GenSigSendType" SG_ 977 BT_Schluesselschalter_zu_inv 3;
BA_ "GenSigSwitchedByIgnition" SG_ 977 BT_Schluesselschalter_zu_inv 0;
BA_ "GenSigSendType" SG_ 977 BT_SP_ausgerastet 3;
BA_ "GenSigSwitchedByIgnition" SG_ 977 BT_SP_ausgerastet 0;
BA_ "GenSigSendType" SG_ 977 BT_Sp_Blk_def 3;
BA_ "GenSigSwitchedByIgnition" SG_ 977 BT_Sp_Blk_def 0;
BA_ "GenSigSendType" SG_ 977 BT_SP_Heizung_aktiv 3;
BA_ "GenSigSwitchedByIgnition" SG_ 977 BT_SP_Heizung_aktiv 0;
BA_ "GenSigSendType" SG_ 977 BT_Sp_Heizung_Anf 0;
BA_ "GenSigSwitchedByIgnition" SG_ 977 BT_Sp_Heizung_Anf 0;
BA_ "GenSigSendType" SG_ 977 BT_SP_Heizung_Status 3;
BA_ "GenSigSwitchedByIgnition" SG_ 977 BT_SP_Heizung_Status 0;
BA_ "GenSigSendType" SG_ 977 BT_SP_ht_aktiv 3;
BA_ "GenSigSwitchedByIgnition" SG_ 977 BT_SP_ht_aktiv 0;
BA_ "GenSigSendType" SG_ 977 BT_SP_lr_aktiv 3;
BA_ "GenSigSwitchedByIgnition" SG_ 977 BT_SP_lr_aktiv 0;
BA_ "GenSigSendType" SG_ 977 BT_Sperrklinke 3;
BA_ "GenSigSwitchedByIgnition" SG_ 977 BT_Sperrklinke 0;
BA_ "GenSigSendType" SG_ 977 BT_SWA_HMI_defekt 0;
BA_ "GenSigSwitchedByIgnition" SG_ 977 BT_SWA_HMI_defekt 0;
BA_ "GenSigSendType" SG_ 977 BT_TAG_betaetigt 3;
BA_ "GenSigSwitchedByIgnition" SG_ 977 BT_TAG_betaetigt 0;
BA_ "GenSigSendType" SG_ 977 BT_TCR_Mode_aktiv 3;
BA_ "GenSigSwitchedByIgnition" SG_ 977 BT_TCR_Mode_aktiv 0;
BA_ "GenSigSendType" SG_ 977 BT_TIG_betaetigt 3;
BA_ "GenSigSwitchedByIgnition" SG_ 977 BT_TIG_betaetigt 0;
BA_ "GenSigSendType" SG_ 977 BT_TSG_hinten_verbaut 3;
BA_ "GenSigSwitchedByIgnition" SG_ 977 BT_TSG_hinten_verbaut 0;
BA_ "GenSigSendType" SG_ 977 BT_Tuer_geoeffnet 3;
BA_ "GenSigSwitchedByIgnition" SG_ 977 BT_Tuer_geoeffnet 0;
BA_ "GenSigSendType" SG_ 977 BT_Tuer_Status 3;
BA_ "GenSigSwitchedByIgnition" SG_ 977 BT_Tuer_Status 0;
BA_ "Fehlerwert" SG_ 977 BT_Tuer_Status 3;
BA_ "GenSigSendType" SG_ 977 BT_Tuer_Status_QBit 0;
BA_ "GenSigSwitchedByIgnition" SG_ 977 BT_Tuer_Status_QBit 0;
BA_ "GenSigSendType" SG_ 977 BT_Tueroeffnen_Warnung 3;
BA_ "GenSigSwitchedByIgnition" SG_ 977 BT_Tueroeffnen_Warnung 0;
BA_ "GenSigSendType" SG_ 977 BT_Tuerschloss_defekt 0;
BA_ "GenSigSwitchedByIgnition" SG_ 977 BT_Tuerschloss_defekt 0;
BA_ "GenSigSendType" SG_ 977 BT_UEKB_aktiviert 3;
BA_ "GenSigSwitchedByIgnition" SG_ 977 BT_UEKB_aktiviert 0;
BA_ "GenSigSendType" SG_ 977 BT_Unlock_Taster 3;
BA_ "GenSigSwitchedByIgnition" SG_ 977 BT_Unlock_Taster 0;
BA_ "GenSigSendType" SG_ 977 BT_Unten_Block_erw 3;
BA_ "GenSigSwitchedByIgnition" SG_ 977 BT_Unten_Block_erw 0;
BA_ "GenSigSendType" SG_ 977 BT_verriegelt 3;
BA_ "GenSigSwitchedByIgnition" SG_ 977 BT_verriegelt 0;
BA_ "GenSigSendType" SG_ 977 BT_Zuziehhilfe_aktiv 3;
BA_ "GenSigSwitchedByIgnition" SG_ 977 BT_Zuziehhilfe_aktiv 0;
BA_ "GenSigSendType" SG_ 976 ASW_HMI_defekt 0;
BA_ "GenSigSwitchedByIgnition" SG_ 976 ASW_HMI_defekt 0;
BA_ "GenSigSendType" SG_ 976 ASW_wakeup 3;
BA_ "GenSigSwitchedByIgnition" SG_ 976 ASW_wakeup 0;
BA_ "GenSigSendType" SG_ 976 ASW_Warnung_aktiv_FS 3;
BA_ "GenSigSwitchedByIgnition" SG_ 976 ASW_Warnung_aktiv_FS 0;
BA_ "GenSigSendType" SG_ 976 FS_Status_eTAG 3;
BA_ "GenSigSwitchedByIgnition" SG_ 976 FS_Status_eTAG 0;
BA_ "Fehlerwert" SG_ 976 FS_Status_eTAG 3;
BA_ "GenSigSendType" SG_ 976 FT_BFS_Fond_Freigabe 3;
BA_ "GenSigSwitchedByIgnition" SG_ 976 FT_BFS_Fond_Freigabe 0;
BA_ "GenSigSendType" SG_ 976 FT_Daemmglas 3;
BA_ "GenSigSwitchedByIgnition" SG_ 976 FT_Daemmglas 0;
BA_ "GenSigSendType" SG_ 976 FT_FH_Bew_hoch 3;
BA_ "GenSigSwitchedByIgnition" SG_ 976 FT_FH_Bew_hoch 0;
BA_ "GenSigSendType" SG_ 976 FT_FH_Bew_tief 3;
BA_ "GenSigSwitchedByIgnition" SG_ 976 FT_FH_Bew_tief 0;
BA_ "GenSigSendType" SG_ 976 FT_FH_Block 3;
BA_ "GenSigSwitchedByIgnition" SG_ 976 FT_FH_Block 0;
BA_ "GenSigSendType" SG_ 976 FT_FH_Fang 3;
BA_ "GenSigSwitchedByIgnition" SG_ 976 FT_FH_Fang 0;
BA_ "GenSigSendType" SG_ 976 FT_FH_normiert 3;
BA_ "GenSigSwitchedByIgnition" SG_ 976 FT_FH_normiert 0;
BA_ "GenSigSendType" SG_ 976 FT_FH_Oeffnung 3;
BA_ "GenSigSwitchedByIgnition" SG_ 976 FT_FH_Oeffnung 0;
BA_ "GenSigSendType" SG_ 976 FT_FH_Pos_oben 3;
BA_ "GenSigSwitchedByIgnition" SG_ 976 FT_FH_Pos_oben 0;
BA_ "GenSigSendType" SG_ 976 FT_FH_S_AutoHoch 3;
BA_ "GenSigSwitchedByIgnition" SG_ 976 FT_FH_S_AutoHoch 0;
BA_ "GenSigSendType" SG_ 976 FT_FH_S_AutoTief 3;
BA_ "GenSigSwitchedByIgnition" SG_ 976 FT_FH_S_AutoTief 0;
BA_ "GenSigSendType" SG_ 976 FT_FH_S_ManHoch 3;
BA_ "GenSigSwitchedByIgnition" SG_ 976 FT_FH_S_ManHoch 0;
BA_ "GenSigSendType" SG_ 976 FT_FH_S_ManTief 3;
BA_ "GenSigSwitchedByIgnition" SG_ 976 FT_FH_S_ManTief 0;
BA_ "GenSigSendType" SG_ 976 FT_FH_Thermo 3;
BA_ "GenSigSwitchedByIgnition" SG_ 976 FT_FH_Thermo 0;
BA_ "GenSigSendType" SG_ 976 FT_gesafet 3;
BA_ "GenSigSwitchedByIgnition" SG_ 976 FT_gesafet 0;
BA_ "GenSigSendType" SG_ 976 FT_HD_Taste 3;
BA_ "GenSigSwitchedByIgnition" SG_ 976 FT_HD_Taste 0;
BA_ "GenSigSendType" SG_ 976 FT_HD_Taste_2 3;
BA_ "GenSigSwitchedByIgnition" SG_ 976 FT_HD_Taste_2 0;
BA_ "GenSigSendType" SG_ 976 FT_IRUE_Taste 3;
BA_ "GenSigSwitchedByIgnition" SG_ 976 FT_IRUE_Taste 0;
BA_ "GenSigSendType" SG_ 976 FT_Kisi_Fehler 3;
BA_ "GenSigSwitchedByIgnition" SG_ 976 FT_Kisi_Fehler 0;
BA_ "Fehlerwert" SG_ 976 FT_Kisi_Fehler 1;
BA_ "GenSigSendType" SG_ 976 FT_Kisi_li_aktiv 3;
BA_ "GenSigSwitchedByIgnition" SG_ 976 FT_Kisi_li_aktiv 0;
BA_ "GenSigSendType" SG_ 976 FT_Kisi_re_aktiv 3;
BA_ "GenSigSwitchedByIgnition" SG_ 976 FT_Kisi_re_aktiv 0;
BA_ "GenSigSendType" SG_ 976 FT_Kisi_Taster_li 3;
BA_ "GenSigSwitchedByIgnition" SG_ 976 FT_Kisi_Taster_li 0;
BA_ "GenSigSendType" SG_ 976 FT_Kisi_Taster_re 3;
BA_ "GenSigSwitchedByIgnition" SG_ 976 FT_Kisi_Taster_re 0;
BA_ "GenSigSendType" SG_ 976 FT_Lock_Taster 3;
BA_ "GenSigSwitchedByIgnition" SG_ 976 FT_Lock_Taster 0;
BA_ "GenSigSendType" SG_ 976 FT_Lock_Unlock_Taster 3;
BA_ "GenSigSwitchedByIgnition" SG_ 976 FT_Lock_Unlock_Taster 0;
BA_ "GenSigSendType" SG_ 976 FT_Oben_Block_erw 3;
BA_ "GenSigSwitchedByIgnition" SG_ 976 FT_Oben_Block_erw 0;
BA_ "GenSigSendType" SG_ 976 FT_Schliesstaster 3;
BA_ "GenSigSwitchedByIgnition" SG_ 976 FT_Schliesstaster 0;
BA_ "GenSigSendType" SG_ 976 FT_Schluesselschalter_auf 3;
BA_ "GenSigSwitchedByIgnition" SG_ 976 FT_Schluesselschalter_auf 0;
BA_ "GenSigSendType" SG_ 976 FT_Schluesselschalter_zu 3;
BA_ "GenSigSwitchedByIgnition" SG_ 976 FT_Schluesselschalter_zu 0;
BA_ "GenSigSendType" SG_ 976 FT_SP_ausgerastet 3;
BA_ "GenSigSwitchedByIgnition" SG_ 976 FT_SP_ausgerastet 0;
BA_ "GenSigSendType" SG_ 976 FT_Sp_Blk_def 3;
BA_ "GenSigSwitchedByIgnition" SG_ 976 FT_Sp_Blk_def 0;
BA_ "GenSigSendType" SG_ 976 FT_Sp_Heizung_Anf 0;
BA_ "GenSigSwitchedByIgnition" SG_ 976 FT_Sp_Heizung_Anf 0;
BA_ "GenSigSendType" SG_ 976 FT_SP_Heizung_Status 3;
BA_ "GenSigSwitchedByIgnition" SG_ 976 FT_SP_Heizung_Status 0;
BA_ "GenSigSendType" SG_ 976 FT_SP_ht_aktiv 3;
BA_ "GenSigSwitchedByIgnition" SG_ 976 FT_SP_ht_aktiv 0;
BA_ "GenSigSendType" SG_ 976 FT_SP_lr_aktiv 3;
BA_ "GenSigSwitchedByIgnition" SG_ 976 FT_SP_lr_aktiv 0;
BA_ "GenSigSendType" SG_ 976 FT_Sperrklinke 3;
BA_ "GenSigSwitchedByIgnition" SG_ 976 FT_Sperrklinke 0;
BA_ "GenSigSendType" SG_ 976 FT_SWA_Taster 3;
BA_ "GenSigSwitchedByIgnition" SG_ 976 FT_SWA_Taster 0;
BA_ "GenSigSendType" SG_ 976 FT_TAG_betaetigt 3;
BA_ "GenSigSwitchedByIgnition" SG_ 976 FT_TAG_betaetigt 0;
BA_ "GenSigSendType" SG_ 976 FT_TD_Taste 3;
BA_ "GenSigSwitchedByIgnition" SG_ 976 FT_TD_Taste 0;
BA_ "GenSigSendType" SG_ 976 FT_TD_Taste_Fehler 0;
BA_ "GenSigSwitchedByIgnition" SG_ 976 FT_TD_Taste_Fehler 0;
BA_ "GenSigSendType" SG_ 976 FT_TIG_betaetigt 3;
BA_ "GenSigSwitchedByIgnition" SG_ 976 FT_TIG_betaetigt 0;
BA_ "GenSigSendType" SG_ 976 FT_TSG_hinten_verbaut 3;
BA_ "GenSigSwitchedByIgnition" SG_ 976 FT_TSG_hinten_verbaut 0;
BA_ "GenSigSendType" SG_ 976 FT_Tuer_geoeffnet 3;
BA_ "GenSigSwitchedByIgnition" SG_ 976 FT_Tuer_geoeffnet 0;
BA_ "GenSigSendType" SG_ 976 FT_Tuerschloss_defekt 0;
BA_ "GenSigSwitchedByIgnition" SG_ 976 FT_Tuerschloss_defekt 0;
BA_ "GenSigSendType" SG_ 976 FT_UEKB_aktiviert 3;
BA_ "GenSigSwitchedByIgnition" SG_ 976 FT_UEKB_aktiviert 0;
BA_ "GenSigSendType" SG_ 976 FT_Unlock_Taster 3;
BA_ "GenSigSwitchedByIgnition" SG_ 976 FT_Unlock_Taster 0;
BA_ "GenSigSendType" SG_ 976 FT_Unten_Block_erw 3;
BA_ "GenSigSwitchedByIgnition" SG_ 976 FT_Unten_Block_erw 0;
BA_ "GenSigSendType" SG_ 976 FT_verriegelt 3;
BA_ "GenSigSwitchedByIgnition" SG_ 976 FT_verriegelt 0;
BA_ "GenSigSendType" SG_ 976 FT_Zuziehhilfe_aktiv 3;
BA_ "GenSigSwitchedByIgnition" SG_ 976 FT_Zuziehhilfe_aktiv 0;
BA_ "GenSigSendType" SG_ 976 SSR_Temp_Freigabe 0;
BA_ "GenSigSwitchedByIgnition" SG_ 976 SSR_Temp_Freigabe 0;
BA_ "GenSigSendType" SG_ 976 SWA_HMI_Diagnose 0;
BA_ "GenSigSwitchedByIgnition" SG_ 976 SWA_HMI_Diagnose 0;
BA_ "GenSigSendType" SG_ 975 ASW_Warnung_aktiv_HBFS 3;
BA_ "GenSigSwitchedByIgnition" SG_ 975 ASW_Warnung_aktiv_HBFS 0;
BA_ "GenSigSendType" SG_ 975 HBFS_FH_Bew_hoch 3;
BA_ "GenSigSwitchedByIgnition" SG_ 975 HBFS_FH_Bew_hoch 0;
BA_ "GenSigSendType" SG_ 975 HBFS_FH_Bew_tief 3;
BA_ "GenSigSwitchedByIgnition" SG_ 975 HBFS_FH_Bew_tief 0;
BA_ "GenSigSendType" SG_ 975 HBFS_FH_Block 3;
BA_ "GenSigSwitchedByIgnition" SG_ 975 HBFS_FH_Block 0;
BA_ "GenSigSendType" SG_ 975 HBFS_FH_Fang 3;
BA_ "GenSigSwitchedByIgnition" SG_ 975 HBFS_FH_Fang 0;
BA_ "GenSigSendType" SG_ 975 HBFS_FH_normiert 3;
BA_ "GenSigSwitchedByIgnition" SG_ 975 HBFS_FH_normiert 0;
BA_ "GenSigSendType" SG_ 975 HBFS_FH_Oeffnung 3;
BA_ "GenSigSwitchedByIgnition" SG_ 975 HBFS_FH_Oeffnung 0;
BA_ "GenSigSendType" SG_ 975 HBFS_FH_S_AutoHoch 3;
BA_ "GenSigSwitchedByIgnition" SG_ 975 HBFS_FH_S_AutoHoch 0;
BA_ "GenSigSendType" SG_ 975 HBFS_FH_S_AutoTief 3;
BA_ "GenSigSwitchedByIgnition" SG_ 975 HBFS_FH_S_AutoTief 0;
BA_ "GenSigSendType" SG_ 975 HBFS_FH_S_HFS_AutoHoch 3;
BA_ "GenSigSwitchedByIgnition" SG_ 975 HBFS_FH_S_HFS_AutoHoch 0;
BA_ "GenSigSendType" SG_ 975 HBFS_FH_S_HFS_AutoTief 3;
BA_ "GenSigSwitchedByIgnition" SG_ 975 HBFS_FH_S_HFS_AutoTief 0;
BA_ "GenSigSendType" SG_ 975 HBFS_FH_S_HFS_ManHoch 3;
BA_ "GenSigSwitchedByIgnition" SG_ 975 HBFS_FH_S_HFS_ManHoch 0;
BA_ "GenSigSendType" SG_ 975 HBFS_FH_S_HFS_ManTief 3;
BA_ "GenSigSwitchedByIgnition" SG_ 975 HBFS_FH_S_HFS_ManTief 0;
BA_ "GenSigSendType" SG_ 975 HBFS_FH_S_ManHoch 3;
BA_ "GenSigSwitchedByIgnition" SG_ 975 HBFS_FH_S_ManHoch 0;
BA_ "GenSigSendType" SG_ 975 HBFS_FH_S_ManTief 3;
BA_ "GenSigSwitchedByIgnition" SG_ 975 HBFS_FH_S_ManTief 0;
BA_ "GenSigSendType" SG_ 975 HBFS_FH_Thermo 3;
BA_ "GenSigSwitchedByIgnition" SG_ 975 HBFS_FH_Thermo 0;
BA_ "GenSigSendType" SG_ 975 HBFS_gesafet 3;
BA_ "GenSigSwitchedByIgnition" SG_ 975 HBFS_gesafet 0;
BA_ "GenSigSendType" SG_ 975 HBFS_Heckrollotaster_betaetigt 3;
BA_ "GenSigSwitchedByIgnition" SG_ 975 HBFS_Heckrollotaster_betaetigt 0;
BA_ "GenSigSendType" SG_ 975 HBFS_Lock_Taster 3;
BA_ "GenSigSwitchedByIgnition" SG_ 975 HBFS_Lock_Taster 0;
BA_ "GenSigSendType" SG_ 975 HBFS_Lock_Taster_inv 3;
BA_ "GenSigStartValue" SG_ 975 HBFS_Lock_Taster_inv 1;
BA_ "GenSigSwitchedByIgnition" SG_ 975 HBFS_Lock_Taster_inv 0;
BA_ "GenSigSendType" SG_ 975 HBFS_MRollo_Schalter 3;
BA_ "GenSigStartValue" SG_ 975 HBFS_MRollo_Schalter 6;
BA_ "GenSigSwitchedByIgnition" SG_ 975 HBFS_MRollo_Schalter 0;
BA_ "Fehlerwert" SG_ 975 HBFS_MRollo_Schalter 7;
BA_ "GenSigSendType" SG_ 975 HBFS_Oben_Block_erw 3;
BA_ "GenSigSwitchedByIgnition" SG_ 975 HBFS_Oben_Block_erw 0;
BA_ "GenSigSendType" SG_ 975 HBFS_SAD_Schalter 3;
BA_ "GenSigSwitchedByIgnition" SG_ 975 HBFS_SAD_Schalter 0;
BA_ "Fehlerwert" SG_ 975 HBFS_SAD_Schalter 15;
BA_ "GenSigSendType" SG_ 975 HBFS_Seitenrollo_hoch 3;
BA_ "GenSigSwitchedByIgnition" SG_ 975 HBFS_Seitenrollo_hoch 0;
BA_ "GenSigSendType" SG_ 975 HBFS_Seitenrollo_tief 3;
BA_ "GenSigSwitchedByIgnition" SG_ 975 HBFS_Seitenrollo_tief 0;
BA_ "GenSigSendType" SG_ 975 HBFS_SK_betaetigt 3;
BA_ "GenSigSwitchedByIgnition" SG_ 975 HBFS_SK_betaetigt 0;
BA_ "GenSigSendType" SG_ 975 HBFS_Sperrklinke 3;
BA_ "GenSigSwitchedByIgnition" SG_ 975 HBFS_Sperrklinke 0;
BA_ "GenSigSendType" SG_ 975 HBFS_Status_eTAG 0;
BA_ "GenSigSwitchedByIgnition" SG_ 975 HBFS_Status_eTAG 0;
BA_ "Fehlerwert" SG_ 975 HBFS_Status_eTAG 3;
BA_ "GenSigSendType" SG_ 975 HBFS_Status_KiSi 3;
BA_ "GenSigSwitchedByIgnition" SG_ 975 HBFS_Status_KiSi 0;
BA_ "GenSigSendType" SG_ 975 HBFS_Status_KiSi_inv 3;
BA_ "GenSigStartValue" SG_ 975 HBFS_Status_KiSi_inv 1;
BA_ "GenSigSwitchedByIgnition" SG_ 975 HBFS_Status_KiSi_inv 0;
BA_ "GenSigSendType" SG_ 975 HBFS_TAG_betaetigt 3;
BA_ "GenSigSwitchedByIgnition" SG_ 975 HBFS_TAG_betaetigt 0;
BA_ "GenSigSendType" SG_ 975 HBFS_TIG_betaetigt 3;
BA_ "GenSigSwitchedByIgnition" SG_ 975 HBFS_TIG_betaetigt 0;
BA_ "GenSigSendType" SG_ 975 HBFS_TIG_betaetigt_oeffnen 3;
BA_ "GenSigSwitchedByIgnition" SG_ 975 HBFS_TIG_betaetigt_oeffnen 0;
BA_ "GenSigSendType" SG_ 975 HBFS_TIG_betaetigt_schliessen 3;
BA_ "GenSigSwitchedByIgnition" SG_ 975 HBFS_TIG_betaetigt_schliessen 0;
BA_ "GenSigSendType" SG_ 975 HBFS_Tuer_geoeffnet 3;
BA_ "GenSigSwitchedByIgnition" SG_ 975 HBFS_Tuer_geoeffnet 0;
BA_ "GenSigSendType" SG_ 975 HBFS_Tuer_Status 3;
BA_ "GenSigSwitchedByIgnition" SG_ 975 HBFS_Tuer_Status 0;
BA_ "Fehlerwert" SG_ 975 HBFS_Tuer_Status 3;
BA_ "GenSigSendType" SG_ 975 HBFS_Tuer_Status_QBit 3;
BA_ "GenSigSwitchedByIgnition" SG_ 975 HBFS_Tuer_Status_QBit 0;
BA_ "GenSigSendType" SG_ 975 HBFS_Tueroeffnen_Warnung 3;
BA_ "GenSigSwitchedByIgnition" SG_ 975 HBFS_Tueroeffnen_Warnung 0;
BA_ "GenSigSendType" SG_ 975 HBFS_Tuerschloss_defekt 0;
BA_ "GenSigSwitchedByIgnition" SG_ 975 HBFS_Tuerschloss_defekt 0;
BA_ "GenSigSendType" SG_ 975 HBFS_UEKB_aktiviert 3;
BA_ "GenSigSwitchedByIgnition" SG_ 975 HBFS_UEKB_aktiviert 0;
BA_ "GenSigSendType" SG_ 975 HBFS_Unlock_Taster 3;
BA_ "GenSigSwitchedByIgnition" SG_ 975 HBFS_Unlock_Taster 0;
BA_ "GenSigSendType" SG_ 975 HBFS_Unten_Block_erw 3;
BA_ "GenSigSwitchedByIgnition" SG_ 975 HBFS_Unten_Block_erw 0;
BA_ "GenSigSendType" SG_ 975 HBFS_verriegelt 3;
BA_ "GenSigSwitchedByIgnition" SG_ 975 HBFS_verriegelt 0;
BA_ "GenSigSendType" SG_ 975 HBFS_Vorraste_betaetigt 3;
BA_ "GenSigSwitchedByIgnition" SG_ 975 HBFS_Vorraste_betaetigt 0;
BA_ "GenSigSendType" SG_ 975 HBFS_Zuziehhilfe_aktiv 3;
BA_ "GenSigSwitchedByIgnition" SG_ 975 HBFS_Zuziehhilfe_aktiv 0;
BA_ "GenSigSendType" SG_ 975 MTHBFS_M_Taste 3;
BA_ "GenSigSwitchedByIgnition" SG_ 975 MTHBFS_M_Taste 0;
BA_ "GenSigSendType" SG_ 975 MTHBFS_Pos1 3;
BA_ "GenSigSwitchedByIgnition" SG_ 975 MTHBFS_Pos1 0;
BA_ "GenSigSendType" SG_ 975 MTHBFS_Pos2 3;
BA_ "GenSigSwitchedByIgnition" SG_ 975 MTHBFS_Pos2 0;
BA_ "GenSigSendType" SG_ 975 MTHBFS_Pos3 3;
BA_ "GenSigSwitchedByIgnition" SG_ 975 MTHBFS_Pos3 0;
BA_ "GenSigSendType" SG_ 975 SSR_HBFS_Pos_Unten 0;
BA_ "GenSigSwitchedByIgnition" SG_ 975 SSR_HBFS_Pos_Unten 0;
BA_ "GenSigSendType" SG_ 974 ASW_Warnung_aktiv_HFS 3;
BA_ "GenSigSwitchedByIgnition" SG_ 974 ASW_Warnung_aktiv_HFS 0;
BA_ "GenSigSendType" SG_ 974 HFS_FH_Bew_hoch 3;
BA_ "GenSigSwitchedByIgnition" SG_ 974 HFS_FH_Bew_hoch 0;
BA_ "GenSigSendType" SG_ 974 HFS_FH_Bew_tief 3;
BA_ "GenSigSwitchedByIgnition" SG_ 974 HFS_FH_Bew_tief 0;
BA_ "GenSigSendType" SG_ 974 HFS_FH_Block 3;
BA_ "GenSigSwitchedByIgnition" SG_ 974 HFS_FH_Block 0;
BA_ "GenSigSendType" SG_ 974 HFS_FH_Fang 3;
BA_ "GenSigSwitchedByIgnition" SG_ 974 HFS_FH_Fang 0;
BA_ "GenSigSendType" SG_ 974 HFS_FH_normiert 3;
BA_ "GenSigSwitchedByIgnition" SG_ 974 HFS_FH_normiert 0;
BA_ "GenSigSendType" SG_ 974 HFS_FH_Oeffnung 3;
BA_ "GenSigSwitchedByIgnition" SG_ 974 HFS_FH_Oeffnung 0;
BA_ "GenSigSendType" SG_ 974 HFS_FH_S_AutoHoch 3;
BA_ "GenSigSwitchedByIgnition" SG_ 974 HFS_FH_S_AutoHoch 0;
BA_ "GenSigSendType" SG_ 974 HFS_FH_S_AutoTief 3;
BA_ "GenSigSwitchedByIgnition" SG_ 974 HFS_FH_S_AutoTief 0;
BA_ "GenSigSendType" SG_ 974 HFS_FH_S_HBFS_AutoHoch 3;
BA_ "GenSigSwitchedByIgnition" SG_ 974 HFS_FH_S_HBFS_AutoHoch 0;
BA_ "GenSigSendType" SG_ 974 HFS_FH_S_HBFS_AutoTief 3;
BA_ "GenSigSwitchedByIgnition" SG_ 974 HFS_FH_S_HBFS_AutoTief 0;
BA_ "GenSigSendType" SG_ 974 HFS_FH_S_HBFS_ManHoch 3;
BA_ "GenSigSwitchedByIgnition" SG_ 974 HFS_FH_S_HBFS_ManHoch 0;
BA_ "GenSigSendType" SG_ 974 HFS_FH_S_HBFS_ManTief 3;
BA_ "GenSigSwitchedByIgnition" SG_ 974 HFS_FH_S_HBFS_ManTief 0;
BA_ "GenSigSendType" SG_ 974 HFS_FH_S_ManHoch 3;
BA_ "GenSigSwitchedByIgnition" SG_ 974 HFS_FH_S_ManHoch 0;
BA_ "GenSigSendType" SG_ 974 HFS_FH_S_ManTief 3;
BA_ "GenSigSwitchedByIgnition" SG_ 974 HFS_FH_S_ManTief 0;
BA_ "GenSigSendType" SG_ 974 HFS_FH_Thermo 3;
BA_ "GenSigSwitchedByIgnition" SG_ 974 HFS_FH_Thermo 0;
BA_ "GenSigSendType" SG_ 974 HFS_gesafet 3;
BA_ "GenSigSwitchedByIgnition" SG_ 974 HFS_gesafet 0;
BA_ "GenSigSendType" SG_ 974 HFS_Heckrollotaster_betaetigt 3;
BA_ "GenSigSwitchedByIgnition" SG_ 974 HFS_Heckrollotaster_betaetigt 0;
BA_ "GenSigSendType" SG_ 974 HFS_Lock_Taster 3;
BA_ "GenSigSwitchedByIgnition" SG_ 974 HFS_Lock_Taster 0;
BA_ "GenSigSendType" SG_ 974 HFS_Lock_Taster_inv 3;
BA_ "GenSigSwitchedByIgnition" SG_ 974 HFS_Lock_Taster_inv 0;
BA_ "GenSigSendType" SG_ 974 HFS_MRollo_Schalter 3;
BA_ "GenSigStartValue" SG_ 974 HFS_MRollo_Schalter 6;
BA_ "GenSigSwitchedByIgnition" SG_ 974 HFS_MRollo_Schalter 0;
BA_ "Fehlerwert" SG_ 974 HFS_MRollo_Schalter 7;
BA_ "GenSigSendType" SG_ 974 HFS_Oben_Block_erw 3;
BA_ "GenSigSwitchedByIgnition" SG_ 974 HFS_Oben_Block_erw 0;
BA_ "GenSigSendType" SG_ 974 HFS_SAD_Schalter 3;
BA_ "GenSigStartValue" SG_ 974 HFS_SAD_Schalter 14;
BA_ "GenSigSwitchedByIgnition" SG_ 974 HFS_SAD_Schalter 0;
BA_ "Fehlerwert" SG_ 974 HFS_SAD_Schalter 15;
BA_ "GenSigSendType" SG_ 974 HFS_Seitenrollo_hoch 3;
BA_ "GenSigSwitchedByIgnition" SG_ 974 HFS_Seitenrollo_hoch 0;
BA_ "GenSigSendType" SG_ 974 HFS_Seitenrollo_tief 3;
BA_ "GenSigSwitchedByIgnition" SG_ 974 HFS_Seitenrollo_tief 0;
BA_ "GenSigSendType" SG_ 974 HFS_SK_betaetigt 3;
BA_ "GenSigSwitchedByIgnition" SG_ 974 HFS_SK_betaetigt 0;
BA_ "GenSigSendType" SG_ 974 HFS_Sperrklinke 3;
BA_ "GenSigSwitchedByIgnition" SG_ 974 HFS_Sperrklinke 0;
BA_ "GenSigSendType" SG_ 974 HFS_Status_eTAG 0;
BA_ "GenSigSwitchedByIgnition" SG_ 974 HFS_Status_eTAG 0;
BA_ "Fehlerwert" SG_ 974 HFS_Status_eTAG 3;
BA_ "GenSigSendType" SG_ 974 HFS_Status_KiSi 3;
BA_ "GenSigSwitchedByIgnition" SG_ 974 HFS_Status_KiSi 0;
BA_ "GenSigSendType" SG_ 974 HFS_TAG_betaetigt 3;
BA_ "GenSigSwitchedByIgnition" SG_ 974 HFS_TAG_betaetigt 0;
BA_ "GenSigSendType" SG_ 974 HFS_TCR_Mode_aktiv 3;
BA_ "GenSigSwitchedByIgnition" SG_ 974 HFS_TCR_Mode_aktiv 0;
BA_ "GenSigSendType" SG_ 974 HFS_TIG_betaetigt 3;
BA_ "GenSigSwitchedByIgnition" SG_ 974 HFS_TIG_betaetigt 0;
BA_ "GenSigSendType" SG_ 974 HFS_TIG_betaetigt_oeffnen 3;
BA_ "GenSigSwitchedByIgnition" SG_ 974 HFS_TIG_betaetigt_oeffnen 0;
BA_ "GenSigSendType" SG_ 974 HFS_TIG_betaetigt_schliessen 3;
BA_ "GenSigSwitchedByIgnition" SG_ 974 HFS_TIG_betaetigt_schliessen 0;
BA_ "GenSigSendType" SG_ 974 HFS_Tuer_geoeffnet 3;
BA_ "GenSigSwitchedByIgnition" SG_ 974 HFS_Tuer_geoeffnet 0;
BA_ "GenSigSendType" SG_ 974 HFS_Tuer_Status 3;
BA_ "GenSigSwitchedByIgnition" SG_ 974 HFS_Tuer_Status 0;
BA_ "Fehlerwert" SG_ 974 HFS_Tuer_Status 3;
BA_ "GenSigSendType" SG_ 974 HFS_Tuer_Status_QBit 0;
BA_ "GenSigSwitchedByIgnition" SG_ 974 HFS_Tuer_Status_QBit 0;
BA_ "GenSigSendType" SG_ 974 HFS_Tueroeffnen_Warnung 3;
BA_ "GenSigSwitchedByIgnition" SG_ 974 HFS_Tueroeffnen_Warnung 0;
BA_ "GenSigSendType" SG_ 974 HFS_Tuerschloss_defekt 0;
BA_ "GenSigSwitchedByIgnition" SG_ 974 HFS_Tuerschloss_defekt 0;
BA_ "GenSigSendType" SG_ 974 HFS_UEKB_aktiviert 3;
BA_ "GenSigSwitchedByIgnition" SG_ 974 HFS_UEKB_aktiviert 0;
BA_ "GenSigSendType" SG_ 974 HFS_Unlock_Taster 3;
BA_ "GenSigSwitchedByIgnition" SG_ 974 HFS_Unlock_Taster 0;
BA_ "GenSigSendType" SG_ 974 HFS_Unten_Block_erw 3;
BA_ "GenSigSwitchedByIgnition" SG_ 974 HFS_Unten_Block_erw 0;
BA_ "GenSigSendType" SG_ 974 HFS_verriegelt 3;
BA_ "GenSigSwitchedByIgnition" SG_ 974 HFS_verriegelt 0;
BA_ "GenSigSendType" SG_ 974 HFS_Vorraste_betaetigt 3;
BA_ "GenSigSwitchedByIgnition" SG_ 974 HFS_Vorraste_betaetigt 0;
BA_ "GenSigSendType" SG_ 974 HFS_Zuziehhilfe_aktiv 3;
BA_ "GenSigSwitchedByIgnition" SG_ 974 HFS_Zuziehhilfe_aktiv 0;
BA_ "GenSigSendType" SG_ 974 MTHFS_M_Taste 3;
BA_ "GenSigSwitchedByIgnition" SG_ 974 MTHFS_M_Taste 0;
BA_ "GenSigSendType" SG_ 974 MTHFS_Pos1 3;
BA_ "GenSigSwitchedByIgnition" SG_ 974 MTHFS_Pos1 0;
BA_ "GenSigSendType" SG_ 974 MTHFS_Pos2 3;
BA_ "GenSigSwitchedByIgnition" SG_ 974 MTHFS_Pos2 0;
BA_ "GenSigSendType" SG_ 974 MTHFS_Pos3 3;
BA_ "GenSigSwitchedByIgnition" SG_ 974 MTHFS_Pos3 0;
BA_ "GenSigSendType" SG_ 974 SSR_HFS_Pos_Unten 0;
BA_ "GenSigSwitchedByIgnition" SG_ 974 SSR_HFS_Pos_Unten 0;
BA_ "GenSigSendType" SG_ 1718 UH_DLS 0;
BA_ "GenSigSwitchedByIgnition" SG_ 1718 UH_DLS 0;
BA_ "GenSigSendType" SG_ 1718 UH_Jahr 0;
BA_ "GenSigSwitchedByIgnition" SG_ 1718 UH_Jahr 0;
BA_ "GenSigSendType" SG_ 1718 UH_Minute 0;
BA_ "GenSigSwitchedByIgnition" SG_ 1718 UH_Minute 0;
BA_ "GenSigSendType" SG_ 1718 UH_Monat 0;
BA_ "GenSigSwitchedByIgnition" SG_ 1718 UH_Monat 0;
BA_ "Fehlerwert" SG_ 1718 UH_Monat 15;
BA_ "GenSigSendType" SG_ 1718 UH_Sekunde 0;
BA_ "GenSigSwitchedByIgnition" SG_ 1718 UH_Sekunde 0;
BA_ "GenSigSendType" SG_ 1718 UH_Stunde 0;
BA_ "GenSigSwitchedByIgnition" SG_ 1718 UH_Stunde 0;
BA_ "GenSigSendType" SG_ 1718 UH_Tag 0;
BA_ "GenSigSwitchedByIgnition" SG_ 1718 UH_Tag 0;
BA_ "GenSigSendType" SG_ 1718 UH_Typ 0;
BA_ "GenSigFuncType" SG_ 1718 UH_Typ 8;
BA_ "GenSigSwitchedByIgnition" SG_ 1718 UH_Typ 0;
BA_ "GenSigSendType" SG_ 2463978710 OPS_ComfortReadyStatus 4;
BA_ "GenSigSwitchedByIgnition" SG_ 2463978710 OPS_ComfortReadyStatus 0;
BA_ "Fehlerwert" SG_ 2463978710 OPS_ComfortReadyStatus 3;
BA_ "GenSigSendType" SG_ 2463978710 OPS_DriverPresenceStatus 4;
BA_ "GenSigSwitchedByIgnition" SG_ 2463978710 OPS_DriverPresenceStatus 0;
BA_ "Fehlerwert" SG_ 2463978710 OPS_DriverPresenceStatus 15;
BA_ "GenSigSendType" SG_ 2463978710 OPS_OccupantPresenceStatus 4;
BA_ "GenSigSwitchedByIgnition" SG_ 2463978710 OPS_OccupantPresenceStatus 0;
BA_ "Fehlerwert" SG_ 2463978710 OPS_OccupantPresenceStatus 7;
BA_ "GenSigSendType" SG_ 2463978710 OPS_QBit_DriverPresence 4;
BA_ "GenSigStartValue" SG_ 2463978710 OPS_QBit_DriverPresence 1;
BA_ "GenSigSwitchedByIgnition" SG_ 2463978710 OPS_QBit_DriverPresence 0;
BA_ "GenSigSendType" SG_ 2463978710 OPS_SafeDriverPresence_available 4;
BA_ "GenSigSwitchedByIgnition" SG_ 2463978710 OPS_SafeDriverPresence_available 0;
BA_ "GenSigSendType" SG_ 2463978710 OPS_SafeDriverPresenceStatus 4;
BA_ "GenSigSwitchedByIgnition" SG_ 2463978710 OPS_SafeDriverPresenceStatus 0;
BA_ "Fehlerwert" SG_ 2463978710 OPS_SafeDriverPresenceStatus 3;
BA_ "GenSigSendType" SG_ 2463978710 UserStateServer_01_BZ 0;
BA_ "GenSigFuncType" SG_ 2463978710 UserStateServer_01_BZ 1;
BA_ "GenSigSwitchedByIgnition" SG_ 2463978710 UserStateServer_01_BZ 0;
BA_ "GenSigSendType" SG_ 2463978710 UserStateServer_01_CRC 0;
BA_ "GenSigFuncType" SG_ 2463978710 UserStateServer_01_CRC 2;
BA_ "GenSigSwitchedByIgnition" SG_ 2463978710 UserStateServer_01_CRC 0;
BA_ "GenSigSendType" SG_ 995 VD_SpannungsAnf 3;
BA_ "GenSigSwitchedByIgnition" SG_ 995 VD_SpannungsAnf 0;
BA_ "GenSigActiveRepetitions" SG_ 995 VS_BFS_AutoHoch 5;
BA_ "GenSigSendType" SG_ 995 VS_BFS_AutoHoch 4;
BA_ "GenSigSwitchedByIgnition" SG_ 995 VS_BFS_AutoHoch 0;
BA_ "GenSigActiveRepetitions" SG_ 995 VS_BFS_AutoTief 5;
BA_ "GenSigSendType" SG_ 995 VS_BFS_AutoTief 4;
BA_ "GenSigSwitchedByIgnition" SG_ 995 VS_BFS_AutoTief 0;
BA_ "GenSigActiveRepetitions" SG_ 995 VS_BFS_ManHoch 5;
BA_ "GenSigSendType" SG_ 995 VS_BFS_ManHoch 4;
BA_ "GenSigSwitchedByIgnition" SG_ 995 VS_BFS_ManHoch 0;
BA_ "GenSigActiveRepetitions" SG_ 995 VS_BFS_ManTief 5;
BA_ "GenSigSendType" SG_ 995 VS_BFS_ManTief 4;
BA_ "GenSigSwitchedByIgnition" SG_ 995 VS_BFS_ManTief 0;
BA_ "GenSigSendType" SG_ 995 VS_Buzzer 3;
BA_ "GenSigSwitchedByIgnition" SG_ 995 VS_Buzzer 0;
BA_ "GenSigSendType" SG_ 995 VS_FH_BT_Langhub 3;
BA_ "GenSigSwitchedByIgnition" SG_ 995 VS_FH_BT_Langhub 0;
BA_ "GenSigSendType" SG_ 995 VS_FH_FT_Langhub 3;
BA_ "GenSigSwitchedByIgnition" SG_ 995 VS_FH_FT_Langhub 0;
BA_ "GenSigSendType" SG_ 995 VS_FH_HBFS_Langhub 3;
BA_ "GenSigSwitchedByIgnition" SG_ 995 VS_FH_HBFS_Langhub 0;
BA_ "GenSigSendType" SG_ 995 VS_FH_HFS_Langhub 3;
BA_ "GenSigSwitchedByIgnition" SG_ 995 VS_FH_HFS_Langhub 0;
BA_ "GenSigActiveRepetitions" SG_ 995 VS_FS_AutoHoch 5;
BA_ "GenSigSendType" SG_ 995 VS_FS_AutoHoch 4;
BA_ "GenSigSwitchedByIgnition" SG_ 995 VS_FS_AutoHoch 0;
BA_ "GenSigActiveRepetitions" SG_ 995 VS_FS_AutoTief 5;
BA_ "GenSigSendType" SG_ 995 VS_FS_AutoTief 4;
BA_ "GenSigSwitchedByIgnition" SG_ 995 VS_FS_AutoTief 0;
BA_ "GenSigActiveRepetitions" SG_ 995 VS_FS_ManHoch 5;
BA_ "GenSigSendType" SG_ 995 VS_FS_ManHoch 4;
BA_ "GenSigSwitchedByIgnition" SG_ 995 VS_FS_ManHoch 0;
BA_ "GenSigActiveRepetitions" SG_ 995 VS_FS_ManTief 5;
BA_ "GenSigSendType" SG_ 995 VS_FS_ManTief 4;
BA_ "GenSigSwitchedByIgnition" SG_ 995 VS_FS_ManTief 0;
BA_ "GenSigSendType" SG_ 995 VS_Hardtop 3;
BA_ "GenSigSwitchedByIgnition" SG_ 995 VS_Hardtop 0;
BA_ "GenSigActiveRepetitions" SG_ 995 VS_HBFS_AutoHoch 5;
BA_ "GenSigSendType" SG_ 995 VS_HBFS_AutoHoch 4;
BA_ "GenSigSwitchedByIgnition" SG_ 995 VS_HBFS_AutoHoch 0;
BA_ "GenSigActiveRepetitions" SG_ 995 VS_HBFS_AutoTief 5;
BA_ "GenSigSendType" SG_ 995 VS_HBFS_AutoTief 4;
BA_ "GenSigSwitchedByIgnition" SG_ 995 VS_HBFS_AutoTief 0;
BA_ "GenSigActiveRepetitions" SG_ 995 VS_HBFS_ManHoch 5;
BA_ "GenSigSendType" SG_ 995 VS_HBFS_ManHoch 4;
BA_ "GenSigSwitchedByIgnition" SG_ 995 VS_HBFS_ManHoch 0;
BA_ "GenSigActiveRepetitions" SG_ 995 VS_HBFS_ManTief 5;
BA_ "GenSigSendType" SG_ 995 VS_HBFS_ManTief 4;
BA_ "GenSigSwitchedByIgnition" SG_ 995 VS_HBFS_ManTief 0;
BA_ "GenSigSendType" SG_ 995 VS_HD_sperren 3;
BA_ "GenSigSwitchedByIgnition" SG_ 995 VS_HD_sperren 0;
BA_ "GenSigSendType" SG_ 995 VS_Heckschloss_auf 3;
BA_ "GenSigSwitchedByIgnition" SG_ 995 VS_Heckschloss_auf 0;
BA_ "GenSigActiveRepetitions" SG_ 995 VS_HFS_AutoHoch 5;
BA_ "GenSigSendType" SG_ 995 VS_HFS_AutoHoch 4;
BA_ "GenSigSwitchedByIgnition" SG_ 995 VS_HFS_AutoHoch 0;
BA_ "GenSigActiveRepetitions" SG_ 995 VS_HFS_AutoTief 5;
BA_ "GenSigSendType" SG_ 995 VS_HFS_AutoTief 4;
BA_ "GenSigSwitchedByIgnition" SG_ 995 VS_HFS_AutoTief 0;
BA_ "GenSigActiveRepetitions" SG_ 995 VS_HFS_ManHoch 5;
BA_ "GenSigSendType" SG_ 995 VS_HFS_ManHoch 4;
BA_ "GenSigSwitchedByIgnition" SG_ 995 VS_HFS_ManHoch 0;
BA_ "GenSigActiveRepetitions" SG_ 995 VS_HFS_ManTief 5;
BA_ "GenSigSendType" SG_ 995 VS_HFS_ManTief 4;
BA_ "GenSigSwitchedByIgnition" SG_ 995 VS_HFS_ManTief 0;
BA_ "GenSigSendType" SG_ 995 VS_HHS_enable 3;
BA_ "GenSigSwitchedByIgnition" SG_ 995 VS_HHS_enable 0;
BA_ "GenSigSendType" SG_ 995 VS_Lampe_Blk 3;
BA_ "GenSigSwitchedByIgnition" SG_ 995 VS_Lampe_Blk 0;
BA_ "GenSigSendType" SG_ 995 VS_StartStopp_Info 3;
BA_ "GenSigSwitchedByIgnition" SG_ 995 VS_StartStopp_Info 0;
BA_ "Fehlerwert" SG_ 995 VS_StartStopp_Info 3;
BA_ "GenSigSendType" SG_ 995 VS_VD_Bew_auf 3;
BA_ "GenSigSwitchedByIgnition" SG_ 995 VS_VD_Bew_auf 0;
BA_ "GenSigSendType" SG_ 995 VS_VD_Bew_zu 3;
BA_ "GenSigSwitchedByIgnition" SG_ 995 VS_VD_Bew_zu 0;
BA_ "GenSigSendType" SG_ 995 VS_VD_entriegelt 3;
BA_ "GenSigSwitchedByIgnition" SG_ 995 VS_VD_entriegelt 0;
BA_ "GenSigSendType" SG_ 995 VS_VD_Fehler 3;
BA_ "GenSigSwitchedByIgnition" SG_ 995 VS_VD_Fehler 0;
BA_ "GenSigSendType" SG_ 995 VS_VD_offen_ver 3;
BA_ "GenSigSwitchedByIgnition" SG_ 995 VS_VD_offen_ver 0;
BA_ "GenSigSendType" SG_ 995 VS_VD_zu_ver 3;
BA_ "GenSigSwitchedByIgnition" SG_ 995 VS_VD_zu_ver 0;
BA_ "GenSigSendType" SG_ 995 VS_VD_Zwischenposition 3;
BA_ "GenSigSwitchedByIgnition" SG_ 995 VS_VD_Zwischenposition 0;
BA_ "GenSigSendType" SG_ 995 VS_VDKD_auf 3;
BA_ "GenSigSwitchedByIgnition" SG_ 995 VS_VDKD_auf 0;
BA_ "GenSigSendType" SG_ 995 VS_Verdeck_Anf 3;
BA_ "GenSigSwitchedByIgnition" SG_ 995 VS_Verdeck_Anf 0;
BA_ "GenSigSendType" SG_ 995 VS_Windschott_nicht_abgelegt 3;
BA_ "GenSigSwitchedByIgnition" SG_ 995 VS_Windschott_nicht_abgelegt 0;
BA_ "GenSigSendType" SG_ 995 VSG_Meldungen 3;
BA_ "GenSigSwitchedByIgnition" SG_ 995 VSG_Meldungen 0;
BA_ "GenSigSwitchedByIgnition" SG_ 1716 KS_Geheimnis_1 0;
BA_ "GenSigSwitchedByIgnition" SG_ 1716 KS_Geheimnis_2 0;
BA_ "GenSigSwitchedByIgnition" SG_ 1716 KS_Geheimnis_3 0;
BA_ "GenSigSwitchedByIgnition" SG_ 1716 KS_Geheimnis_4 0;
BA_ "GenSigSendType" SG_ 1716 VIN_01_MUX 0;
BA_ "GenSigSwitchedByIgnition" SG_ 1716 VIN_01_MUX 0;
BA_ "GenSigStartValue" SG_ 1716 VIN_1 45;
BA_ "GenSigSwitchedByIgnition" SG_ 1716 VIN_1 0;
BA_ "GenSigStartValue" SG_ 1716 VIN_10 45;
BA_ "GenSigSwitchedByIgnition" SG_ 1716 VIN_10 0;
BA_ "GenSigStartValue" SG_ 1716 VIN_11 45;
BA_ "GenSigSwitchedByIgnition" SG_ 1716 VIN_11 0;
BA_ "GenSigStartValue" SG_ 1716 VIN_12 45;
BA_ "GenSigSwitchedByIgnition" SG_ 1716 VIN_12 0;
BA_ "GenSigStartValue" SG_ 1716 VIN_13 45;
BA_ "GenSigSwitchedByIgnition" SG_ 1716 VIN_13 0;
BA_ "GenSigStartValue" SG_ 1716 VIN_14 45;
BA_ "GenSigSwitchedByIgnition" SG_ 1716 VIN_14 0;
BA_ "GenSigStartValue" SG_ 1716 VIN_15 45;
BA_ "GenSigSwitchedByIgnition" SG_ 1716 VIN_15 0;
BA_ "GenSigStartValue" SG_ 1716 VIN_16 45;
BA_ "GenSigSwitchedByIgnition" SG_ 1716 VIN_16 0;
BA_ "GenSigStartValue" SG_ 1716 VIN_17 45;
BA_ "GenSigSwitchedByIgnition" SG_ 1716 VIN_17 0;
BA_ "GenSigStartValue" SG_ 1716 VIN_2 45;
BA_ "GenSigSwitchedByIgnition" SG_ 1716 VIN_2 0;
BA_ "GenSigStartValue" SG_ 1716 VIN_3 45;
BA_ "GenSigSwitchedByIgnition" SG_ 1716 VIN_3 0;
BA_ "GenSigStartValue" SG_ 1716 VIN_4 45;
BA_ "GenSigSwitchedByIgnition" SG_ 1716 VIN_4 0;
BA_ "GenSigStartValue" SG_ 1716 VIN_5 45;
BA_ "GenSigSwitchedByIgnition" SG_ 1716 VIN_5 0;
BA_ "GenSigStartValue" SG_ 1716 VIN_6 45;
BA_ "GenSigSwitchedByIgnition" SG_ 1716 VIN_6 0;
BA_ "GenSigStartValue" SG_ 1716 VIN_7 45;
BA_ "GenSigSwitchedByIgnition" SG_ 1716 VIN_7 0;
BA_ "GenSigStartValue" SG_ 1716 VIN_8 45;
BA_ "GenSigSwitchedByIgnition" SG_ 1716 VIN_8 0;
BA_ "GenSigStartValue" SG_ 1716 VIN_9 45;
BA_ "GenSigSwitchedByIgnition" SG_ 1716 VIN_9 0;
BA_ "GenSigSendType" SG_ 1702 BCM1_SRA_aktiv 3;
BA_ "GenSigSwitchedByIgnition" SG_ 1702 BCM1_SRA_aktiv 0;
BA_ "GenSigActiveRepetitions" SG_ 1702 Heckwischer_Anforderung 3;
BA_ "GenSigSendType" SG_ 1702 Heckwischer_Anforderung 4;
BA_ "GenSigSwitchedByIgnition" SG_ 1702 Heckwischer_Anforderung 0;
BA_ "GenSigSendType" SG_ 1702 Waschen_vorne_aktiv 3;
BA_ "GenSigSwitchedByIgnition" SG_ 1702 Waschen_vorne_aktiv 0;
BA_ "GenSigSendType" SG_ 1702 Wischer1_Wischgeschwindigkeit 0;
BA_ "GenSigStartValue" SG_ 1702 Wischer1_Wischgeschwindigkeit 62;
BA_ "GenSigSwitchedByIgnition" SG_ 1702 Wischer1_Wischgeschwindigkeit 0;
BA_ "Fehlerwert" SG_ 1702 Wischer1_Wischgeschwindigkeit 63;
BA_ "GenSigSendType" SG_ 1702 Wischer_Anzeigetext 3;
BA_ "GenSigSwitchedByIgnition" SG_ 1702 Wischer_Anzeigetext 0;
BA_ "GenSigSendType" SG_ 1702 Wischer_vorne_aktiv 3;
BA_ "GenSigSwitchedByIgnition" SG_ 1702 Wischer_vorne_aktiv 0;
BA_ "GenSigSendType" SG_ 1702 Wischer_vorne_blockiert 3;
BA_ "GenSigSwitchedByIgnition" SG_ 1702 Wischer_vorne_blockiert 0;
BA_ "GenSigSendType" SG_ 1702 Wischer_vorne_defekt 3;
BA_ "GenSigSwitchedByIgnition" SG_ 1702 Wischer_vorne_defekt 0;
BA_ "GenSigSendType" SG_ 1702 Wischer_vorne_Normal 3;
BA_ "GenSigSwitchedByIgnition" SG_ 1702 Wischer_vorne_Normal 0;
BA_ "GenSigSendType" SG_ 1702 Wischer_vorne_Parklage 3;
BA_ "GenSigStartValue" SG_ 1702 Wischer_vorne_Parklage 1;
BA_ "GenSigSwitchedByIgnition" SG_ 1702 Wischer_vorne_Parklage 0;
BA_ "GenSigSendType" SG_ 1702 Wischer_vorne_Schnell 3;
BA_ "GenSigSwitchedByIgnition" SG_ 1702 Wischer_vorne_Schnell 0;
BA_ "GenSigSendType" SG_ 1702 Wischer_WH_PopUp_Anf 3;
BA_ "GenSigSwitchedByIgnition" SG_ 1702 Wischer_WH_PopUp_Anf 0;
BA_ "GenSigSendType" SG_ 1702 Wischer_WH_Typ 0;
BA_ "GenSigSwitchedByIgnition" SG_ 1702 Wischer_WH_Typ 0;
BA_ "GenSigSendType" SG_ 1702 WWSs_01_alt 0;
BA_ "GenSigStartValue" SG_ 1702 WWSs_01_alt 1;
BA_ "GenSigFuncType" SG_ 1702 WWSs_01_alt 5;
BA_ "GenSigSwitchedByIgnition" SG_ 1702 WWSs_01_alt 0;
BA_ "GenSigSendType" SG_ 1411 BCM_FH_Freigabe 3;
BA_ "GenSigSwitchedByIgnition" SG_ 1411 BCM_FH_Freigabe 0;
BA_ "GenSigSendType" SG_ 1411 BCM_HSK_Freigabe 3;
BA_ "GenSigSwitchedByIgnition" SG_ 1411 BCM_HSK_Freigabe 0;
BA_ "GenSigSendType" SG_ 1411 BCM_Komfortfkt_Freigabe 3;
BA_ "GenSigSwitchedByIgnition" SG_ 1411 BCM_Komfortfkt_Freigabe 0;
BA_ "GenSigSendType" SG_ 1411 BCM_Tankklappensteller_Fehler 0;
BA_ "GenSigSwitchedByIgnition" SG_ 1411 BCM_Tankklappensteller_Fehler 0;
BA_ "Fehlerwert" SG_ 1411 BCM_Tankklappensteller_Fehler 1;
BA_ "GenSigSendType" SG_ 1411 BCM_Verdeck_Freigabe 3;
BA_ "GenSigSwitchedByIgnition" SG_ 1411 BCM_Verdeck_Freigabe 0;
BA_ "GenSigSendType" SG_ 1411 DWA_aktiv 3;
BA_ "GenSigSwitchedByIgnition" SG_ 1411 DWA_aktiv 0;
BA_ "GenSigSendType" SG_ 1411 FBS_IDG_in_Reichweite 6;
BA_ "GenSigSwitchedByIgnition" SG_ 1411 FBS_IDG_in_Reichweite 0;
BA_ "GenSigSendType" SG_ 1411 FBS_Warn_Schluessel_Batt 3;
BA_ "GenSigSwitchedByIgnition" SG_ 1411 FBS_Warn_Schluessel_Batt 0;
BA_ "GenSigSendType" SG_ 1411 FFB_Auf_Taste 6;
BA_ "GenSigSwitchedByIgnition" SG_ 1411 FFB_Auf_Taste 0;
BA_ "GenSigSendType" SG_ 1411 FFB_CarFinder 6;
BA_ "GenSigSwitchedByIgnition" SG_ 1411 FFB_CarFinder 0;
BA_ "GenSigSendType" SG_ 1411 FFB_HDF_Taste 6;
BA_ "GenSigSwitchedByIgnition" SG_ 1411 FFB_HDF_Taste 0;
BA_ "GenSigSendType" SG_ 1411 FFB_Komfortoeffnen 6;
BA_ "GenSigSwitchedByIgnition" SG_ 1411 FFB_Komfortoeffnen 0;
BA_ "GenSigSendType" SG_ 1411 FFB_Komfortschliessen 6;
BA_ "GenSigSwitchedByIgnition" SG_ 1411 FFB_Komfortschliessen 0;
BA_ "GenSigSendType" SG_ 1411 FFB_Panik_Taste 6;
BA_ "GenSigSwitchedByIgnition" SG_ 1411 FFB_Panik_Taste 0;
BA_ "GenSigSendType" SG_ 1411 FFB_Zu_Taste 6;
BA_ "GenSigSwitchedByIgnition" SG_ 1411 FFB_Zu_Taste 0;
BA_ "GenSigSendType" SG_ 1411 HBFS_gesafet 3;
BA_ "GenSigSwitchedByIgnition" SG_ 1411 HBFS_gesafet 0;
BA_ "GenSigSendType" SG_ 1411 HBFS_verriegelt 3;
BA_ "GenSigSwitchedByIgnition" SG_ 1411 HBFS_verriegelt 0;
BA_ "GenSigSendType" SG_ 1411 HD_Hauptraste 3;
BA_ "GenSigSwitchedByIgnition" SG_ 1411 HD_Hauptraste 0;
BA_ "GenSigSendType" SG_ 1411 HD_Vorraste 3;
BA_ "GenSigSwitchedByIgnition" SG_ 1411 HD_Vorraste 0;
BA_ "GenSigSendType" SG_ 1411 HFS_gesafet 3;
BA_ "GenSigSwitchedByIgnition" SG_ 1411 HFS_gesafet 0;
BA_ "GenSigSendType" SG_ 1411 HFS_verriegelt 3;
BA_ "GenSigSwitchedByIgnition" SG_ 1411 HFS_verriegelt 0;
BA_ "GenSigSendType" SG_ 1411 IRUE_aktiv 3;
BA_ "GenSigSwitchedByIgnition" SG_ 1411 IRUE_aktiv 0;
BA_ "GenSigSendType" SG_ 1411 IRUE_Taster_Fkts_LED 3;
BA_ "GenSigSwitchedByIgnition" SG_ 1411 IRUE_Taster_Fkts_LED 0;
BA_ "GenSigSendType" SG_ 1411 VIP_Sensor_STSG_HBFS_betaetigt 6;
BA_ "GenSigSwitchedByIgnition" SG_ 1411 VIP_Sensor_STSG_HBFS_betaetigt 0;
BA_ "GenSigSendType" SG_ 1411 VIP_Sensor_STSG_HFS_betaetigt 6;
BA_ "GenSigSwitchedByIgnition" SG_ 1411 VIP_Sensor_STSG_HFS_betaetigt 0;
BA_ "GenSigSendType" SG_ 1411 ZV_Anf_Challenge_Auth 6;
BA_ "GenSigSwitchedByIgnition" SG_ 1411 ZV_Anf_Challenge_Auth 0;
BA_ "GenSigSendType" SG_ 1411 ZV_BT_offen 3;
BA_ "GenSigSwitchedByIgnition" SG_ 1411 ZV_BT_offen 0;
BA_ "GenSigSendType" SG_ 1411 ZV_Einzeltuerentriegelung 3;
BA_ "GenSigSwitchedByIgnition" SG_ 1411 ZV_Einzeltuerentriegelung 0;
BA_ "GenSigSendType" SG_ 1411 ZV_eRWK_Umfeld_Pruefung 6;
BA_ "GenSigSwitchedByIgnition" SG_ 1411 ZV_eRWK_Umfeld_Pruefung 0;
BA_ "GenSigSendType" SG_ 1411 ZV_FT_offen 3;
BA_ "GenSigSwitchedByIgnition" SG_ 1411 ZV_FT_offen 0;
BA_ "GenSigSendType" SG_ 1411 ZV_gesafet_extern_ist 3;
BA_ "GenSigSwitchedByIgnition" SG_ 1411 ZV_gesafet_extern_ist 0;
BA_ "GenSigSendType" SG_ 1411 ZV_gesafet_extern_soll 3;
BA_ "GenSigSwitchedByIgnition" SG_ 1411 ZV_gesafet_extern_soll 0;
BA_ "GenSigSendType" SG_ 1411 ZV_HBFS_offen 3;
BA_ "GenSigSwitchedByIgnition" SG_ 1411 ZV_HBFS_offen 0;
BA_ "GenSigSendType" SG_ 1411 ZV_HD_offen 3;
BA_ "GenSigSwitchedByIgnition" SG_ 1411 ZV_HD_offen 0;
BA_ "GenSigSendType" SG_ 1411 ZV_Heckeinzelentriegelung 3;
BA_ "GenSigSwitchedByIgnition" SG_ 1411 ZV_Heckeinzelentriegelung 0;
BA_ "GenSigSendType" SG_ 1411 ZV_HFS_offen 3;
BA_ "GenSigSwitchedByIgnition" SG_ 1411 ZV_HFS_offen 0;
BA_ "GenSigSendType" SG_ 1411 ZV_HS_offen 3;
BA_ "GenSigSwitchedByIgnition" SG_ 1411 ZV_HS_offen 0;
BA_ "GenSigSendType" SG_ 1411 ZV_ist_Zustand_verfuegbar 3;
BA_ "GenSigSwitchedByIgnition" SG_ 1411 ZV_ist_Zustand_verfuegbar 0;
BA_ "GenSigSendType" SG_ 1411 ZV_Oeffnungsmodus 3;
BA_ "GenSigSwitchedByIgnition" SG_ 1411 ZV_Oeffnungsmodus 0;
BA_ "GenSigSendType" SG_ 1411 ZV_Rollo_auf 3;
BA_ "GenSigSwitchedByIgnition" SG_ 1411 ZV_Rollo_auf 0;
BA_ "GenSigSendType" SG_ 1411 ZV_Rollo_zu 3;
BA_ "GenSigSwitchedByIgnition" SG_ 1411 ZV_Rollo_zu 0;
BA_ "GenSigSendType" SG_ 1411 ZV_SAD_auf 3;
BA_ "GenSigSwitchedByIgnition" SG_ 1411 ZV_SAD_auf 0;
BA_ "GenSigSendType" SG_ 1411 ZV_SAD_zu 3;
BA_ "GenSigSwitchedByIgnition" SG_ 1411 ZV_SAD_zu 0;
BA_ "GenSigSendType" SG_ 1411 ZV_SafeFunktion_aktiv 3;
BA_ "GenSigSwitchedByIgnition" SG_ 1411 ZV_SafeFunktion_aktiv 0;
BA_ "GenSigSendType" SG_ 1411 ZV_Schluessel_Zugang 3;
BA_ "GenSigSwitchedByIgnition" SG_ 1411 ZV_Schluessel_Zugang 0;
BA_ "GenSigSendType" SG_ 1411 ZV_STSG_Crashzustand 4;
BA_ "GenSigSwitchedByIgnition" SG_ 1411 ZV_STSG_Crashzustand 0;
BA_ "GenSigSendType" SG_ 1411 ZV_STSG_eKiSi_defekt 4;
BA_ "GenSigSwitchedByIgnition" SG_ 1411 ZV_STSG_eKiSi_defekt 0;
BA_ "GenSigSendType" SG_ 1411 ZV_STSG_HBFS_Anf 3;
BA_ "GenSigSwitchedByIgnition" SG_ 1411 ZV_STSG_HBFS_Anf 0;
BA_ "GenSigSendType" SG_ 1411 ZV_STSG_HFS_Anf 3;
BA_ "GenSigSwitchedByIgnition" SG_ 1411 ZV_STSG_HFS_Anf 0;
BA_ "GenSigSendType" SG_ 1411 ZV_Tankklappe_offen 0;
BA_ "GenSigSwitchedByIgnition" SG_ 1411 ZV_Tankklappe_offen 0;
BA_ "GenSigSendType" SG_ 1411 ZV_verriegeln_Anf 6;
BA_ "GenSigSwitchedByIgnition" SG_ 1411 ZV_verriegeln_Anf 0;
BA_ "GenSigSendType" SG_ 1411 ZV_verriegelt_extern_ist 3;
BA_ "GenSigSwitchedByIgnition" SG_ 1411 ZV_verriegelt_extern_ist 0;
BA_ "GenSigSendType" SG_ 1411 ZV_verriegelt_extern_soll 3;
BA_ "GenSigSwitchedByIgnition" SG_ 1411 ZV_verriegelt_extern_soll 0;
BA_ "GenSigSendType" SG_ 1411 ZV_verriegelt_intern_ist 3;
BA_ "GenSigSwitchedByIgnition" SG_ 1411 ZV_verriegelt_intern_ist 0;
BA_ "GenSigSendType" SG_ 1411 ZV_verriegelt_intern_soll 3;
BA_ "GenSigSwitchedByIgnition" SG_ 1411 ZV_verriegelt_intern_soll 0;
BA_ "GenSigSendType" SG_ 1411 ZV_verriegelt_soll 3;
BA_ "GenSigSwitchedByIgnition" SG_ 1411 ZV_verriegelt_soll 0;
BA_REL_ "GenSigTimeoutTime" BU_SG_REL_ Gateway_Max SG_ 1001 Thermo_Pred_T_dyn_Innen 1000;
BA_REL_ "GenSigTimeoutTime" BU_SG_REL_ Gateway_Max SG_ 1001 Thermo_Pred_Innen_Kunde_Anf 1000;
BA_REL_ "GenSigTimeoutTime" BU_SG_REL_ Gateway_Max SG_ 1001 Thermo_Pred_P_dyn_Innen 1000;
BA_REL_ "GenSigTimeoutTime" BU_SG_REL_ Gateway_Max SG_ 1001 Thermo_Pred_P_stat_Innen 1000;
BA_REL_ "GenSigTimeoutTime" BU_SG_REL_ Gateway_Max SG_ 1001 Thermo_Verbrauch_BTL 1000;
BA_REL_ "GenSigTimeoutTime" BU_SG_REL_ Gateway_Max SG_ 1001 Thermo_Verbrauch_BTL_Ueberlauf 1000;
BA_REL_ "GenSigTimeoutTime" BU_SG_REL_ Gateway_Max SG_ 1001 Thermo_Pred_Innen_System_Anf 1000;
BA_REL_ "GenSigTimeoutTime" BU_SG_REL_ Gateway_Max SG_ 1001 Thermo_Verbrauch_Innen 1000;
BA_REL_ "GenSigTimeoutTime" BU_SG_REL_ Gateway_Max SG_ 1001 Thermo_Verbrauch_Innen_Ueberlauf 1000;
BA_REL_ "GenSigTimeoutTime" BU_SG_REL_ Klima SG_ 1413 SI_P_Mode_gueltig 5000;
BA_REL_ "GenSigTimeoutTime" BU_SG_REL_ Klima SG_ 1413 SI_QRS_Mode 5000;
BA_REL_ "GenSigTimeoutTime" BU_SG_REL_ Klima SG_ 1413 SI_T_Mode 5000;
BA_REL_ "GenSigTimeoutTime" BU_SG_REL_ Klima SG_ 1413 SI_NWDF 5000;
BA_REL_ "GenSigTimeoutTime" BU_SG_REL_ Klima SG_ 1413 SI_NWDF_gueltig 5000;
BA_REL_ "GenSigTimeoutTime" BU_SG_REL_ Klima SG_ 1413 SI_T_Schutz 5000;
BA_REL_ "GenSigTimeoutTime" BU_SG_REL_ Klima SG_ 1413 SI_P_Mode 5000;
BA_REL_ "GenSigTimeoutTime" BU_SG_REL_ Klima SG_ 1413 SI_BUS_04 5000;
BA_REL_ "GenSigTimeoutTime" BU_SG_REL_ Klima SG_ 1413 SI_CAB_V14 5000;
BA_REL_ "GenSigTimeoutTime" BU_SG_REL_ Klima SG_ 1447 eCall_Funktionsstatus_02 5000;
BA_REL_ "GenSigTimeoutTime" BU_SG_REL_ Klima SG_ 977 BT_FH_Oeffnung 1000;
BA_REL_ "GenSigTimeoutTime" BU_SG_REL_ Klima SG_ 976 FT_Tuer_geoeffnet 1000;
BA_REL_ "GenSigTimeoutTime" BU_SG_REL_ Klima SG_ 976 FT_FH_Oeffnung 1000;
BA_REL_ "GenSigTimeoutTime" BU_SG_REL_ Klima SG_ 975 HBFS_Tuer_geoeffnet 1000;
BA_REL_ "GenSigTimeoutTime" BU_SG_REL_ Klima SG_ 975 HBFS_FH_Oeffnung 1000;
BA_REL_ "GenSigTimeoutTime" BU_SG_REL_ Klima SG_ 974 HFS_Tuer_geoeffnet 1000;
BA_REL_ "GenSigTimeoutTime" BU_SG_REL_ Klima SG_ 974 HFS_FH_Oeffnung 1000;
BA_REL_ "GenSigTimeoutTime" BU_SG_REL_ Klima SG_ 1718 UH_DLS 5000;
BA_REL_ "GenSigTimeoutTime" BU_SG_REL_ Klima SG_ 2463978710 OPS_ComfortReadyStatus 1000;
BA_REL_ "GenSigTimeoutTime" BU_SG_REL_ Klima SG_ 2463978710 OPS_OccupantPresenceStatus 1000;
BA_REL_ "GenSigTimeoutTime" BU_SG_REL_ Klima SG_ 2463978710 OPS_DriverPresenceStatus 1000;
BA_REL_ "GenSigTimeoutTime" BU_SG_REL_ Klima SG_ 2463978710 OPS_QBit_DriverPresence 1000;
BA_REL_ "GenSigTimeoutTime" BU_SG_REL_ Klima SG_ 995 VS_VD_zu_ver 1000;
BA_REL_ "GenSigTimeoutTime" BU_SG_REL_ Klima SG_ 995 VS_VD_Bew_auf 1000;
BA_REL_ "GenSigTimeoutTime" BU_SG_REL_ Klima SG_ 995 VS_VD_Bew_zu 1000;
BA_REL_ "GenSigTimeoutTime" BU_SG_REL_ Klima SG_ 1716 VIN_01_MUX 2000;
BA_REL_ "GenSigTimeoutTime" BU_SG_REL_ Klima SG_ 1716 VIN_4 2000;
BA_REL_ "GenSigTimeoutTime" BU_SG_REL_ Klima SG_ 1716 VIN_11 2000;
BA_REL_ "GenSigTimeoutTime" BU_SG_REL_ Klima SG_ 1716 VIN_5 2000;
BA_REL_ "GenSigTimeoutTime" BU_SG_REL_ Klima SG_ 1716 VIN_12 2000;
BA_REL_ "GenSigTimeoutTime" BU_SG_REL_ Klima SG_ 1716 VIN_6 2000;
BA_REL_ "GenSigTimeoutTime" BU_SG_REL_ Klima SG_ 1716 VIN_13 2000;
BA_REL_ "GenSigTimeoutTime" BU_SG_REL_ Klima SG_ 1716 VIN_7 2000;
BA_REL_ "GenSigTimeoutTime" BU_SG_REL_ Klima SG_ 1716 VIN_14 2000;
BA_REL_ "GenSigTimeoutTime" BU_SG_REL_ Klima SG_ 1716 VIN_1 2000;
BA_REL_ "GenSigTimeoutTime" BU_SG_REL_ Klima SG_ 1716 VIN_8 2000;
BA_REL_ "GenSigTimeoutTime" BU_SG_REL_ Klima SG_ 1716 VIN_15 2000;
BA_REL_ "GenSigTimeoutTime" BU_SG_REL_ Klima SG_ 1716 VIN_2 2000;
BA_REL_ "GenSigTimeoutTime" BU_SG_REL_ Klima SG_ 1716 VIN_9 2000;
BA_REL_ "GenSigTimeoutTime" BU_SG_REL_ Klima SG_ 1716 VIN_16 2000;
BA_REL_ "GenSigTimeoutTime" BU_SG_REL_ Klima SG_ 1716 VIN_3 2000;
BA_REL_ "GenSigTimeoutTime" BU_SG_REL_ Klima SG_ 1716 VIN_10 2000;
BA_REL_ "GenSigTimeoutTime" BU_SG_REL_ Klima SG_ 1716 VIN_17 2000;
BA_REL_ "GenSigTimeoutTime" BU_SG_REL_ Klima SG_ 1702 Wischer_vorne_aktiv 5000;
BA_REL_ "GenSigTimeoutTime" BU_SG_REL_ Klima SG_ 1702 Waschen_vorne_aktiv 5000;
BA_REL_ "GenSigTimeoutTime" BU_SG_REL_ Klima SG_ 1702 Wischer_vorne_defekt 5000;
BA_REL_ "GenSigTimeoutTime" BU_SG_REL_ Klima SG_ 1702 Wischer1_Wischgeschwindigkeit 5000;
BA_REL_ "GenSigTimeoutTime" BU_SG_REL_ Klima SG_ 1411 ZV_verriegelt_intern_ist 2000;
BA_REL_ "GenSigTimeoutTime" BU_SG_REL_ Klima SG_ 1411 ZV_verriegelt_extern_ist 2000;
BA_REL_ "GenSigTimeoutTime" BU_SG_REL_ Klima SG_ 1411 ZV_verriegelt_intern_soll 2000;
BA_REL_ "GenSigTimeoutTime" BU_SG_REL_ Klima SG_ 1411 ZV_verriegelt_extern_soll 2000;
BA_REL_ "GenSigTimeoutTime" BU_SG_REL_ Klima SG_ 1411 ZV_gesafet_extern_ist 2000;
BA_REL_ "GenSigTimeoutTime" BU_SG_REL_ Klima SG_ 1411 ZV_FT_offen 2000;
BA_REL_ "GenSigTimeoutTime" BU_SG_REL_ Klima SG_ 1411 ZV_BT_offen 2000;
BA_REL_ "GenSigTimeoutTime" BU_SG_REL_ Klima SG_ 1411 ZV_HFS_offen 2000;
BA_REL_ "GenSigTimeoutTime" BU_SG_REL_ Klima SG_ 1411 ZV_HBFS_offen 2000;
BA_REL_ "GenSigTimeoutTime" BU_SG_REL_ Klima SG_ 1411 ZV_HD_offen 2000;
BA_REL_ "GenSigTimeoutTime" BU_SG_REL_ Klima SG_ 1411 ZV_Schluessel_Zugang 2000;
VAL_ 1413 SI_Sammel_SG_Fehler 61 "Reserviert" 62 "Overflow" 63 "ungueltig" ;
VAL_ 1413 SI_P_Mode_gueltig 0 "dezentraler_Produktionsmode" 1 "zentraler_Produktionsmode" ;
VAL_ 1413 SI_Diagnose_Aktiv 0 "inaktiv" 1 "aktiv" ;
VAL_ 1413 SI_QRS_Mode 0 "QRS_Messmodus_nicht_aktiv" 1 "QRS_Messmodus_aktiv" ;
VAL_ 1413 SI_T_Mode 0 "Transportmodus_nicht_aktiv" 1 "Transportmodus_aktiv" ;
VAL_ 1413 SI_NWDF 0 "Ueberwachung_nicht_freigegeben" 1 "Ueberwachung_freigegeben" ;
VAL_ 1413 SI_NWDF_gueltig 0 "NWDF_wird_nicht_unterstuetzt" 1 "NWDF_wird_unterstuetzt" ;
VAL_ 1413 SI_Sammelfehler 0 "kein_Sammelfehler" 1 "Sammelfehler" ;
VAL_ 1413 GW_KD_Fehler 0 "kein_KD_Fehler" 1 "KD_Fehler" ;
VAL_ 1413 SI_T_Schutz 0 "Transportschutz_nicht_aktiv" 1 "Transportschutz_aktiv" ;
VAL_ 1413 SI_P_Mode 0 "inaktiv" 1 "aktiv" ;
VAL_ 1413 SI_BUS_01 0 "keine_Busruhe" 1 "Busruhe" ;
VAL_ 1413 SI_BUS_02 0 "keine_Busruhe" 1 "Busruhe" ;
VAL_ 1413 SI_BUS_03 0 "keine_Busruhe" 1 "Busruhe" ;
VAL_ 1413 SI_BUS_04 0 "keine_Busruhe" 1 "Busruhe" ;
VAL_ 1413 SI_BUS_05 0 "keine_Busruhe" 1 "Busruhe" ;
VAL_ 1413 SI_BUS_06 0 "keine_Busruhe" 1 "Busruhe" ;
VAL_ 1413 SI_BUS_07 0 "keine_Busruhe" 1 "Busruhe" ;
VAL_ 1413 SI_BUS_08 0 "keine_Busruhe" 1 "Busruhe" ;
VAL_ 1413 SI_BUS_09 0 "keine_Busruhe" 1 "Busruhe" ;
VAL_ 1413 SI_BUS_10 0 "keine_Busruhe" 1 "Busruhe" ;
VAL_ 1413 SI_BUS_11 0 "keine_Busruhe" 1 "Busruhe" ;
VAL_ 1413 SI_BUS_12 0 "keine_Busruhe" 1 "Busruhe" ;
VAL_ 1413 SI_BUS_13 0 "keine_Busruhe" 1 "Busruhe" ;
VAL_ 1413 SI_BUS_14 0 "keine_Busruhe" 1 "Busruhe" ;
VAL_ 1413 SI_BUS_15 0 "keine_Busruhe" 1 "Busruhe" ;
VAL_ 1413 SI_NWDF_30 0 "Ueberwachung_nicht_freigegeben" 1 "Ueberwachung_freigegeben" ;
VAL_ 1413 SI_Bus_Identifikation 16 "CAN_Diagnose" 17 "CAN_Antrieb" 18 "CAN_Komfort" 19 "CAN_Infotainment" 20 "CAN_Fahrwerk" 21 "CAN_Extended" 22 "CAN_Hybrid" 23 "CAN_Lade" 24 "CAN_Kombi" 25 "CAN_Komfort_2" 26 "CAN_AFS" 27 "CAN_MIB" 28 "CAN_Batterie_BMC" 29 "CAN_Motor" 31 "CAN_Airbag_Sicherheitssysteme" 33 "CAN_FahrerAssistenzSysteme" 34 "CAN_Migration" 35 "CAN_Connect" 36 "CAN_AnzeigeBedienung" 37 "CAN_ElectricalVehicle" 40 "CAN_Telematik" 41 "CAN_MFL" 42 "CAN_FahrerAssistenzSysteme_2" 43 "CAN_FahrerAssistenzSysteme_3" 47 "CAN_Komfort_3" 48 "FlexRay_A" 49 "FlexRay_B" 97 "VLAN_FAS" 98 "VLAN_Infotainment" 99 "VLAN_Connect" 100 "VLAN_Komfort" 101 "VLAN_Antrieb" 102 "VLAN_Diagnose" 103 "VLAN_Internet" 104 "VLAN_Gateway" 105 "VLAN_Remote_FC" 106 "VLAN_Connect_2" 107 "VLAN_Licht" 108 "VLAN_Charge" 109 "VLAN_Cockpit" 110 "VLAN_Connect_3" 111 "VLAN_IoT" 112 "VLAN_CarPerformance" 113 "VLAN_ConMod" 114 "VLAN_FAS2" 176 "HCP1_CANFD01" 177 "HCP1_CANFD02" 178 "HCP1_CANFD03" 179 "HCP1_CANFD04" 180 "HCP1_CANFD05" 181 "HCP1_CANFD06" 182 "HCP1_CANFD07" 183 "HCP1_CANFD08" 186 "HCP4_CANFD03" 187 "HCP4_CANFD04" 188 "HCP1_CANFD09" 189 "HCP4_CANFD06" 190 "HCP4_CANFD07" 191 "HCP4_CANFD08" 192 "HCP4_CANFD09" 193 "HCP4_CANFD10" 194 "HCP1_CANFD10" 195 "ICAS1_CANFD2_HCP5_CANFD02" 196 "HCP1_CANFD11" 197 "WU_HCP1_CANFD" 199 "WU_HCP2_CANFD" 200 "WU_HCP3_CANFD" 201 "WU_HCP4_CANFD" 202 "HCP3_CANFD02" 204 "ESC_CANFD" 205 "HCP4_CANFD11" 206 "HCP4_CANFD12" 207 "CAN_Innenraumsensorik" 212 "WU_ConMod_CANFD" 213 "WU_PASD_CANFD" 215 "CAN_MobileDeviceKey" 217 "CAN_Tuerantrieb_VL" 218 "CAN_Tuerantrieb_VR" 219 "CAN_Tuerantrieb_HL" 220 "CAN_Tuerantrieb_HR" ;
VAL_ 1413 SI_CAB_V14 0 "Init" 1 "CAB_01_Antrieb" 2 "CAB_02_Hybrid_Laden" 4 "CAB_03_Fahrwerk" 8 "CAB_04_Fahrerassistenz" 16 "CAB_05_Komfort" 32 "CAB_06_Anzeige" 64 "CAB_07_Connect" 128 "CAB_08_MIB" 256 "CAB_09_Standheizung" 1024 "CAB_11_VLAN_Fahrerassistenz" 2048 "CAB_12_VLAN_Komfort" 4096 "CAB_13_VLAN_Connect" 8192 "CAB_14_VLAN_Infotainment" 16384 "CAB_15_Laden" 32768 "CAB_16_Licht" ;
VAL_ 1001 Thermo_Pred_T_dyn_Innen 254 "Init" 255 "Fehler" ;
VAL_ 1001 Thermo_Pred_P_dyn_Innen 2046 "Init" 2047 "Fehler" ;
VAL_ 1001 Thermo_Pred_P_stat_Innen 2046 "Init" 2047 "Fehler" ;
VAL_ 1001 Thermo_Verbrauch_BTL_Ueberlauf 0 "kein_Ueberlauf" 1 "Ueberlauf" ;
VAL_ 1001 Thermo_Verbrauch_Innen_Ueberlauf 0 "kein_Ueberlauf" 1 "Ueberlauf" ;
VAL_ 2527679738 Thermo_Pred_T_dyn_In_Standard 254 "Init" 255 "Fehler" ;
VAL_ 2527679738 Thermo_Pred_P_stat_In_Standard 2046 "Init" 2047 "Fehler" ;
VAL_ 2527679738 Thermo_Pred_T_dyn_In_Efficien1 254 "Init" 255 "Fehler" ;
VAL_ 2527679738 Thermo_Pred_P_dyn_In_Efficien1 2046 "Init" 2047 "Fehler" ;
VAL_ 2527679738 Thermo_Pred_P_stat_In_Efficien1 2046 "Init" 2047 "Fehler" ;
VAL_ 2527679738 Thermo_Pred_P_dyn_In_Efficien2 2046 "Init" 2047 "Fehler" ;
VAL_ 2527679738 Thermo_Pred_P_stat_In_Efficien2 2046 "Init" 2047 "Fehler" ;
VAL_ 2527679738 Thermo_Pred_T_dyn_In_Efficien2 254 "Init" 255 "Fehler" ;
VAL_ 2527679738 Thermo_Pred_P_dyn_In_Standard 2046 "Init" 2047 "Fehler" ;
VAL_ 1447 ORU_KombiTimer 0 "ORU_Inaktiv" 1 "ORU_Start" ;
VAL_ 1447 MOD_Energie_Anf 0 "Keine_Anforderung" 1 "Anforderung_NV" 2 "Anforderung_HV_Nutzung_Erlaubt" 3 "Fehler" ;
VAL_ 1447 FaceRec_Enroll_Challenge_Request 0 "SEND_NOTHING" 1 "SEND_CHALLENGE" ;
VAL_ 1447 eCall_Mute_Anf 0 "kein_mute" 1 "mute" ;
VAL_ 1447 FoD_Anz_Funktionsabschaltung 0 "Init" 1 "Popup_aufschalten" ;
VAL_ 1447 iCall_active 0 "inaktiv" 1 "aktiv" ;
VAL_ 1447 bCall_active 0 "bcall_inactive" 1 "bcall_active" ;
VAL_ 1447 MOD_Request_ServiceKey 0 "Init" 1 "Aktuallisierungsanfrage" ;
VAL_ 1447 eCall_Funktionsstatus_02 0 "kein_Fehler" 1 "Manueller_Notruf_aktiv" 2 "Automatischer_Notruf_aktiv" 7 "Init" ;
VAL_ 1447 eCall_Funktionsstatus 0 "kein_Fehler" 1 "Fkt_eingeschraenkt" 2 "Fkt_eingeschraenkt_service" 3 "Fkt_nicht_verfuegbar" 4 "Fkt_Service" 5 "Fkt_deaktiviert" 6 "Fkt_aktiviert" 7 "init" ;
VAL_ 1447 TM_Spiegel_Anklappen 0 "Init" 1 "Spiegel_anklappen" ;
VAL_ 1447 TM_Nur_Hupen 0 "inaktiv" 1 "aktiv" ;
VAL_ 1447 TM_Door_Lock 0 "Init" 1 "door_lock" ;
VAL_ 1447 TM_Door_Unlock 0 "Init" 1 "door_unlock" ;
VAL_ 1447 TM_Warnblinken 0 "Init" 1 "Warnblinken_on" ;
VAL_ 1447 TM_Panik_Alarm 0 "Init" 1 "panik_alarm_on" ;
VAL_ 1447 TM_ZV_Signatur 0 "Init" ;
VAL_ 977 BT_Tuer_geoeffnet 0 "geschlossen" 1 "offen" ;
VAL_ 977 BT_verriegelt 0 "Init" 1 "verriegelt" ;
VAL_ 977 BT_gesafet 0 "Init" 1 "gesafet" ;
VAL_ 977 BT_Schluesselschalter_auf 0 "Init" 1 "Schluesselschalter_auf_betaetigt" ;
VAL_ 977 BT_Schluesselschalter_zu 0 "Init" 1 "Schluesselschalter_zu_betaetigt" ;
VAL_ 977 BT_Unlock_Taster 0 "Init" 1 "Unlock_Taster_betaetigt" ;
VAL_ 977 BT_Lock_Taster 0 "Init" 1 "Lock_Taster_betaetigt" ;
VAL_ 977 BT_Sperrklinke 0 "Schloss_in_Vorraste_und_Hauptraste" 1 "Tuer_auf_oder_Tuer_Position_zwischen_Vor_und_Hauptraste" ;
VAL_ 977 BT_TAG_betaetigt 0 "Init" 1 "Tuerinnengriff_betaetigt" ;
VAL_ 977 BT_TIG_betaetigt 0 "Init" 1 "Tuerinnengriff_betaetigt" ;
VAL_ 977 BT_Tuer_Status 0 "Init" 1 "Tuer_geschlossen" 2 "Tuer_offen" 3 "Fehler" ;
VAL_ 977 BT_TSG_hinten_verbaut 0 "nicht verbaut" 1 "verbaut" ;
VAL_ 977 BT_Sp_Blk_def 0 "iO" 1 "Spiegel_Blinker_defekt" ;
VAL_ 977 BT_FH_S_ManHoch 0 "Init" 1 "FH_Schalter_man_hoch_gedrueckt" ;
VAL_ 977 BT_FH_S_AutoHoch 0 "Init" 1 "FH_Schalter_auto_hoch_gedrueckt" ;
VAL_ 977 BT_FH_S_ManTief 0 "Init" 1 "FH_Schalter_man_tief_gedrueckt" ;
VAL_ 977 BT_FH_S_AutoTief 0 "Init" 1 "FH_Schalter_auto_tief_gedrueckt" ;
VAL_ 977 BT_FH_Bew_hoch 0 "Init" 1 "FH_ist_in_Bewegung_hoch" ;
VAL_ 977 BT_FH_Bew_tief 0 "Init" 1 "FH_ist_in_Bewegung_tief" ;
VAL_ 977 BT_FH_Fang 0 "ausserhalb_Fangbereich" 1 "innerhalb_Fangbereich" ;
VAL_ 977 BT_FH_Block 0 "Init" 1 "Fensterheber_Block" ;
VAL_ 977 BT_FH_Thermo 0 "Init" 1 "Thermoschutz_aktiv" ;
VAL_ 977 BT_UEKB_aktiviert 0 "Init" 1 "aktiv" ;
VAL_ 977 BT_Kisi_Fehler 0 "kein_Fehler" 1 "Fehler" ;
VAL_ 977 BT_FH_normiert 0 "Init" 1 "Fenster_normiert" ;
VAL_ 977 BT_Schliesstaster 0 "nicht_betaetigt" 1 "betaetigt" ;
VAL_ 977 BT_Zuziehhilfe_aktiv 0 "Init" 1 "Zuziehhilfe_aktiv" ;
VAL_ 977 BT_SP_ausgerastet 0 "Init" 1 "Spiegel_ausgerastet" ;
VAL_ 977 BT_SP_lr_aktiv 0 "Init" 1 "Spiegel_xAchse_aktiv" ;
VAL_ 977 BT_SP_ht_aktiv 0 "Init" 1 "Spiegel_yAchse_aktiv" ;
VAL_ 977 BT_SP_Heizung_aktiv 0 "BF_Spiegelheizung_aus" 1 "BF_Spiegelheizung_ein" ;
VAL_ 977 BT_Oben_Block_erw 0 "Fensterheber_nicht_in_Blockerwar" 1 "Fensterheber_in_Blockerwartung_o" ;
VAL_ 977 BT_Unten_Block_erw 0 "Fensterheber_nicht_in_Blockerwar" 1 "Fensterheber_in_Blockerwartung_u" ;
VAL_ 977 BT_Tuer_Status_QBit 0 "Status_Tuerkontakt_sicher" 1 "Status_Tuerkontakt_unsicher" ;
VAL_ 977 BFS_Status_eTAG 0 "Init" 1 "Griff_ausgefahren" 2 "Griff_eingefahren" 3 "Fehler" ;
VAL_ 977 BT_TCR_Mode_aktiv 0 "TCR_Mode_deaktiv" 1 "TCR_Mode_aktiv" ;
VAL_ 977 BT_Lock_Unlock_Taster 0 "nicht_betaetigt" 1 "betaetigt" ;
VAL_ 977 BT_SP_Heizung_Status 0 "Init" 1 "Status_Spiegelheizung_ein" ;
VAL_ 977 ASW_Warnung_aktiv_BFS 0 "nicht_angefordert" 1 "angefordert" ;
VAL_ 977 BT_FH_Pos_oben 1 "Scheibe oben (nach Absenken auf Position) " ;
VAL_ 977 BT_Tuerschloss_defekt 0 "Tuerschloss_funktionsfaehig" 1 "Tuerschloss_defekt" ;
VAL_ 977 BT_Tueroeffnen_Warnung 0 "Tuerwarnung_nicht_aktiv" 1 "Tuerwarnung_aktiv" ;
VAL_ 977 BT_Lock_Taster_inv 0 "Lock Taster betätigt" 1 "Lock Taster nicht betätigt" ;
VAL_ 977 BT_Schluesselschalter_zu_inv 0 "Schlüsselschalter betätigt" 1 "Schlüsselschalter nicht betätigt" ;
VAL_ 977 BT_SWA_HMI_defekt 0 "SWA_kein_Fehler" 1 "SWA_Fehler" ;
VAL_ 977 BT_ASW_HMI_defekt 0 "ASW_kein_Fehler" 1 "ASW_Fehler" ;
VAL_ 976 FT_Tuer_geoeffnet 0 "geschlossen" 1 "Tuer_offen" ;
VAL_ 976 FT_verriegelt 0 "Init" 1 "verriegelt" ;
VAL_ 976 FT_gesafet 0 "Init" 1 "gesafet" ;
VAL_ 976 FT_Schluesselschalter_auf 0 "Init" 1 "Schluesselschalter_auf_betaetigt" ;
VAL_ 976 FT_Schluesselschalter_zu 1 "Schluesselschalter zu betaetigt" ;
VAL_ 976 FT_Unlock_Taster 0 "Init" 1 "Unlock_Taster_betaetigt" ;
VAL_ 976 FT_Lock_Taster 0 "Init" 1 "Lock_Taster_betaetigt" ;
VAL_ 976 FT_Sperrklinke 0 "Schloss_in_Vorraste_und_Hauptraste" 1 "Tuer_auf_oder_Tuer_Position_zwischen_Vor_und_Hauptraste" ;
VAL_ 976 FT_TAG_betaetigt 0 "nicht_betaetigt" 1 "betaetigt" ;
VAL_ 976 FT_TIG_betaetigt 0 "nicht_betaetigt" 1 "betaetigt" ;
VAL_ 976 FT_IRUE_Taste 0 "Init" 1 "IRUE_Taste_betaetigt" ;
VAL_ 976 FT_HD_Taste 0 "nicht_betaetigt" 1 "Heckdeckeltaste_betaetigt" ;
VAL_ 976 FT_TD_Taste_Fehler 0 "iO" 1 "defekt" ;
VAL_ 976 FT_TD_Taste 0 "Init" 1 "Tankdeckel_Taster_betaetigt" ;
VAL_ 976 SSR_Temp_Freigabe 0 "SSR_Deaktiviert" 1 "SSR_Freigegeben" ;
VAL_ 976 FT_HD_Taste_2 0 "Taste_nicht_gedrueckt" 1 "Taste_gedrueckt" ;
VAL_ 976 FT_Lock_Unlock_Taster 0 "nicht_betaetigt" 1 "betaetigt" ;
VAL_ 976 FT_TSG_hinten_verbaut 0 "nicht verbaut" 1 "verbaut" ;
VAL_ 976 FT_Sp_Blk_def 0 "iO" 1 "defekt" ;
VAL_ 976 FT_FH_S_ManHoch 0 "Init" 1 "FH_Schalter_man_hoch_betaetigt" ;
VAL_ 976 FT_FH_S_AutoHoch 0 "Init" 1 "FH_Schalter_auto_hoch_betaetigt" ;
VAL_ 976 FT_FH_S_ManTief 0 "Init" 1 "FH_Schalter_man_tief_betaetigt" ;
VAL_ 976 FT_FH_S_AutoTief 0 "Init" 1 "FH_Schalter_auto_tief_betaetigt" ;
VAL_ 976 FT_FH_Bew_hoch 0 "Init" 1 "FH_in_Bewegung_hoch" ;
VAL_ 976 FT_FH_Bew_tief 0 "Init" 1 "FH_in_Bewegung_tief" ;
VAL_ 976 FT_FH_Fang 0 "ausserhalb_Fangbereich" 1 "innerhalb_Fangbereich" ;
VAL_ 976 FT_FH_Block 0 "Init" 1 "Fenster_Block" ;
VAL_ 976 FT_FH_Thermo 0 "Init" 1 "Thermoschutz_aktiv" ;
VAL_ 976 FT_UEKB_aktiviert 0 "Init" 1 "UEKB_aktiv" ;
VAL_ 976 ASW_HMI_defekt 0 "iO" 1 "defekt" ;
VAL_ 976 FT_FH_normiert 0 "Init" 1 "Fenster_normiert" ;
VAL_ 976 FT_Schliesstaster 1 "Schliesstaster_betaetigt" ;
VAL_ 976 FT_Zuziehhilfe_aktiv 0 "Init" 1 "Zuziehilfe_aktiv" ;
VAL_ 976 FT_SP_ausgerastet 0 "Init" 1 "Spiegel_ausgerastet" ;
VAL_ 976 FT_SP_lr_aktiv 0 "Init" 1 "Spiegel_xAchse_aktiv" ;
VAL_ 976 FT_SP_ht_aktiv 0 "Init" 1 "Spiegel_yAchse_aktiv" ;
VAL_ 976 ASW_wakeup 0 "Sleep" 1 "Wakeup" ;
VAL_ 976 FT_Oben_Block_erw 0 "Fensterheber_nicht_in_Blockerwar" 1 "Fensterheber_in_Blockerwartung_o" ;
VAL_ 976 FT_Unten_Block_erw 0 "Fensterheber_nicht_in_Blockerwar" 1 "Fensterheber_in_Blockerwartung_u" ;
VAL_ 976 FT_Kisi_li_aktiv 0 "inaktiv" 1 "aktiv" ;
VAL_ 976 FT_Kisi_re_aktiv 0 "inaktiv" 1 "aktiv" ;
VAL_ 976 FT_Kisi_Taster_li 0 "nicht_betaetigt" 1 "betaetigt" ;
VAL_ 976 FT_Kisi_Taster_re 0 "nicht_betaetigt" 1 "betaetigt" ;
VAL_ 976 FT_BFS_Fond_Freigabe 0 "Init" 1 "Freigabe_fuer_Fondbedienung_BFS" ;
VAL_ 976 FT_Kisi_Fehler 0 "kein_Fehler" 1 "Fehler" ;
VAL_ 976 FT_Daemmglas 0 "Normalglas_verbaut" 1 "Daemmglas_verbaut" ;
VAL_ 976 FT_SP_Heizung_Status 0 "Init" 1 "Status_Spiegelheizung_ein" ;
VAL_ 976 ASW_Warnung_aktiv_FS 0 "nicht_angefordert" 1 "angefordert" ;
VAL_ 976 FT_FH_Pos_oben 1 "Scheibe oben (nach Absenken auf Position) " ;
VAL_ 976 FT_Tuerschloss_defekt 0 "Tuerschloss_funktionsfaehig" 1 "Tuerschloss_defekt" ;
VAL_ 976 FT_SWA_Taster 0 "Taster_nicht_betaetigt" 1 "Taster_betaetigt" ;
VAL_ 976 SWA_HMI_Diagnose 0 "kein_Fehler_erkannt" 1 "Fehler_Taster_erkannt" 2 "Fehler_LED_erkannt" 3 "Fehler_LED_und_Taster_erkannt" ;
VAL_ 976 FS_Status_eTAG 0 "Init" 1 "Griff_ausgefahren" 2 "Griff_eingefahren" 3 "Fehler" ;
VAL_ 975 HBFS_Tuer_geoeffnet 0 "geschlossen" 1 "offen" ;
VAL_ 975 HBFS_verriegelt 0 "nicht_verriegelt" 1 "verriegelt" ;
VAL_ 975 HBFS_gesafet 0 "nicht_gesafet" 1 "gesafet" ;
VAL_ 975 HBFS_Heckrollotaster_betaetigt 0 "keine_Verfahranweisung_in_Richtung_Hoch" 1 "In_Richtung_Hoch_Verfahren" ;
VAL_ 975 HBFS_Tuerschloss_defekt 0 "Tuerschloss_funktionsfaehig" 1 "Tuerschloss_defekt" ;
VAL_ 975 HBFS_Unlock_Taster 0 "nicht_betaetigt" 1 "betaetigt" ;
VAL_ 975 HBFS_Lock_Taster 0 "nicht_betaetigt" 1 "betaetigt" ;
VAL_ 975 HBFS_Sperrklinke 0 "Schloss_in_Vorraste_und_Hauptraste" 1 "Tuer_auf_oder_Tuer_Position_zwischen_Vor_und_Hauptraste" ;
VAL_ 975 HBFS_TAG_betaetigt 0 "nicht_betaetigt" 1 "betaetigt" ;
VAL_ 975 HBFS_TIG_betaetigt 0 "nicht_betaetigt" 1 "betaetigt" ;
VAL_ 975 HBFS_FH_S_HFS_AutoHoch 0 "keine_Bedienung" 1 "Automatiklauf_Angefordert" ;
VAL_ 975 HBFS_FH_S_HFS_AutoTief 0 "keine_Bedienung" 1 "Automatiklauf_Angefordert" ;
VAL_ 975 HBFS_FH_S_HFS_ManHoch 0 "keine_Bedienung" 1 "Manueller_Lauf_Angefordert" ;
VAL_ 975 HBFS_FH_S_HFS_ManTief 0 "keine_Bedienung" 1 "Manueller_Lauf_Angefordert" ;
VAL_ 975 HBFS_Tuer_Status 0 "Init" 1 "Tuer_geschlossen" 2 "Tuer_offen" 3 "Fehler" ;
VAL_ 975 HBFS_SAD_Schalter 0 "nicht_betaetigt" 5 "AUF_manuell" 6 "AUF_automatik" 7 "ZU_manuell" 8 "ZU_automatik" 13 "nicht_verfuegbar" 14 "Init" 15 "Fehler" ;
VAL_ 975 HBFS_FH_S_ManHoch 0 "nicht_betaetigt" 1 "betaetigt" ;
VAL_ 975 HBFS_FH_S_AutoHoch 0 "nicht_betaetigt" 1 "betaetigt" ;
VAL_ 975 HBFS_FH_S_ManTief 0 "nicht_betaetigt" 1 "betaetigt" ;
VAL_ 975 HBFS_FH_S_AutoTief 0 "nicht_betaetigt" 1 "betaetigt" ;
VAL_ 975 HBFS_FH_Bew_hoch 0 "inaktiv" 1 "aktiv" ;
VAL_ 975 HBFS_FH_Bew_tief 0 "inaktiv" 1 "aktiv" ;
VAL_ 975 HBFS_FH_Fang 0 "ausserhalb_Fangbereich" 1 "innerhalb_Fangbereich" ;
VAL_ 975 HBFS_FH_Block 0 "inaktiv" 1 "aktiv" ;
VAL_ 975 HBFS_FH_Thermo 0 "inaktiv" 1 "aktiv" ;
VAL_ 975 HBFS_UEKB_aktiviert 0 "inaktiv" 1 "aktiv" ;
VAL_ 975 HBFS_Tueroeffnen_Warnung 0 "Tuerwarnung_nicht_aktiv" 1 "Tuerwarnung_aktiv" ;
VAL_ 975 HBFS_FH_normiert 0 "inaktiv" 1 "aktiv" ;
VAL_ 975 ASW_Warnung_aktiv_HBFS 0 "nicht_angefordert" 1 "angefordert" ;
VAL_ 975 HBFS_Zuziehhilfe_aktiv 0 "Init" 1 "Zuziehhilfe_aktiv" ;
VAL_ 975 HBFS_Seitenrollo_hoch 1 "Seitenrollo_in_Bewegung_hoch" ;
VAL_ 975 HBFS_Seitenrollo_tief 0 "Init" 1 "Seitenrollo_in_Bewegung_tief" ;
VAL_ 975 HBFS_Status_KiSi 0 "inaktiv" 1 "aktiv" ;
VAL_ 975 SSR_HBFS_Pos_Unten 0 "SSR_Oben" 1 "SSR_Unten" ;
VAL_ 975 HBFS_Oben_Block_erw 0 "Fensterheber_nicht_in_Blockerwar" 1 "Fensterheber_in_Blockerwartung_o" ;
VAL_ 975 HBFS_Unten_Block_erw 0 "Fensterheber_nicht_in_Blockerwar" 1 "Fensterheber_in_Blockerwartung_u" ;
VAL_ 975 MTHBFS_M_Taste 0 "nicht_betaetigt" 1 "betaetigt" ;
VAL_ 975 MTHBFS_Pos1 0 "nicht_betaetigt" 1 "betaetigt" ;
VAL_ 975 MTHBFS_Pos2 0 "nicht_betaetigt" 1 "betaetigt" ;
VAL_ 975 MTHBFS_Pos3 0 "nicht_betaetigt" 1 "betaetigt" ;
VAL_ 975 HBFS_MRollo_Schalter 0 "nicht_betaetigt" 1 "ZU_manuell" 2 "ZU_automatik" 3 "AUF_manuell" 4 "AUF_automatik" 5 "nicht_verfuegbar" 6 "Init" 7 "Fehler" ;
VAL_ 975 HBFS_Lock_Taster_inv 0 "Lock Taster betätgit" 1 "Lock Taster nicht betätigt" ;
VAL_ 975 HBFS_Status_KiSi_inv 0 "aktiv" 1 "inaktiv" ;
VAL_ 975 HBFS_Status_eTAG 0 "Init" 1 "Griff_ausgefahren" 2 "Griff_eingefahren" 3 "Fehler" ;
VAL_ 975 HBFS_Tuer_Status_QBit 0 "Status_Tuerkontakt_sicher" 1 "Status_Tuerkontakt_unsicher" ;
VAL_ 975 HBFS_TIG_betaetigt_schliessen 0 "nicht_betaetigt" 1 "betaetigt" ;
VAL_ 975 HBFS_TIG_betaetigt_oeffnen 0 "nicht_betaetigt" 1 "betaetigt" ;
VAL_ 975 HBFS_Vorraste_betaetigt 0 "nicht_in_Vorraste" 1 "in_Vorraste" ;
VAL_ 975 HBFS_SK_betaetigt 0 "ausgehoben" 1 "eingefallen" ;
VAL_ 974 HFS_Tuer_geoeffnet 0 "geschlossen" 1 "offen" ;
VAL_ 974 HFS_verriegelt 0 "nicht_verriegelt" 1 "verriegelt" ;
VAL_ 974 HFS_gesafet 0 "nicht_gesafet" 1 "gesafet" ;
VAL_ 974 HFS_Heckrollotaster_betaetigt 0 "keine_Verfahranweisung_in_Richtung_Hoch" 1 "In_Richtung_Hoch_Verfahren" ;
VAL_ 974 HFS_Tuerschloss_defekt 0 "Tuerschloss_funktionsfaehig" 1 "Tuerschloss_defekt" ;
VAL_ 974 HFS_Unlock_Taster 0 "nicht_betaetigt" 1 "betaetigt" ;
VAL_ 974 HFS_Lock_Taster 0 "nicht_betaetigt" 1 "betaetigt" ;
VAL_ 974 HFS_Sperrklinke 0 "Schloss_in_Vorraste_und_Hauptraste" 1 "Tuer_auf_oder_Tuer_Position_zwischen_Vor_und_Hauptraste" ;
VAL_ 974 HFS_TAG_betaetigt 0 "nicht_betaetigt" 1 "betaetigt" ;
VAL_ 974 HFS_TIG_betaetigt 0 "nicht_betaetigt" 1 "betaetigt" ;
VAL_ 974 HFS_FH_S_HBFS_AutoHoch 0 "keine_Bedienung" 1 "Automatiklauf_Angefordert" ;
VAL_ 974 HFS_FH_S_HBFS_AutoTief 0 "keine_Bedienung" 1 "Automatiklauf_Angefordert" ;
VAL_ 974 HFS_FH_S_HBFS_ManHoch 0 "keine_Bedienung" 1 "Manueller_Lauf_Angefordert" ;
VAL_ 974 HFS_FH_S_HBFS_ManTief 0 "keine_Bedienung" 1 "Manueller_Lauf_Angefordert" ;
VAL_ 974 HFS_Tuer_Status 0 "Init" 1 "Tuer_geschlossen" 2 "Tuer_offen" 3 "Fehler" ;
VAL_ 974 HFS_SAD_Schalter 0 "nicht_betaetigt" 5 "AUF_manuell" 6 "AUF_automatik" 7 "ZU_manuell" 8 "ZU_automatik" 13 "nicht_verfuegbar" 14 "Init" 15 "Fehler" ;
VAL_ 974 HFS_FH_S_ManHoch 0 "nicht_betaetigt" 1 "betaetigt" ;
VAL_ 974 HFS_FH_S_AutoHoch 0 "nicht_betaetigt" 1 "betaetigt" ;
VAL_ 974 HFS_FH_S_ManTief 0 "nicht_betaetigt" 1 "betaetigt" ;
VAL_ 974 HFS_FH_S_AutoTief 0 "nicht_betaetigt" 1 "betaetigt" ;
VAL_ 974 HFS_FH_Bew_hoch 0 "inaktiv" 1 "aktiv" ;
VAL_ 974 HFS_FH_Bew_tief 0 "inaktiv" 1 "aktiv" ;
VAL_ 974 HFS_FH_Fang 0 "ausserhalb_Fangbereich" 1 "innerhalb_Fangbereich" ;
VAL_ 974 HFS_FH_Block 0 "inaktiv" 1 "aktiv" ;
VAL_ 974 HFS_FH_Thermo 0 "inaktiv" 1 "aktiv" ;
VAL_ 974 HFS_UEKB_aktiviert 0 "inaktiv" 1 "aktiv" ;
VAL_ 974 HFS_Tueroeffnen_Warnung 0 "Tuerwarnung_nicht_aktiv" 1 "Tuerwarnung_aktiv" ;
VAL_ 974 HFS_FH_normiert 0 "inaktiv" 1 "aktiv" ;
VAL_ 974 ASW_Warnung_aktiv_HFS 0 "nicht_angefordert" 1 "angefordert" ;
VAL_ 974 HFS_Zuziehhilfe_aktiv 0 "Init" 1 "Zuziehhilfe_aktiv" ;
VAL_ 974 HFS_Seitenrollo_hoch 0 "Init" 1 "Seitenrollo_in_Bewegung_hoch" ;
VAL_ 974 HFS_Seitenrollo_tief 0 "Init" 1 "Seitenrollo_in_Bewegung_tief" ;
VAL_ 974 HFS_Status_KiSi 0 "inaktiv" 1 "aktiv" ;
VAL_ 974 SSR_HFS_Pos_Unten 0 "SSR_Oben" 1 "SSR_Unten" ;
VAL_ 974 HFS_Oben_Block_erw 0 "Fensterheber_nicht_in_Blockerwar" 1 "Fensterheber_in_Blockerwartung_o" ;
VAL_ 974 HFS_Unten_Block_erw 0 "Fensterheber_nicht_in_Blockerwar" 1 "Fensterheber_in_Blockerwartung_u" ;
VAL_ 974 MTHFS_M_Taste 0 "nicht_betaetigt" 1 "betaetigt" ;
VAL_ 974 MTHFS_Pos1 0 "nicht_betaetigt" 1 "betaetigt" ;
VAL_ 974 MTHFS_Pos2 0 "nicht_betaetigt" 1 "betaetigt" ;
VAL_ 974 MTHFS_Pos3 0 "nicht_betaetigt" 1 "betaetigt" ;
VAL_ 974 HFS_MRollo_Schalter 0 "nicht_betaetigt" 1 "ZU_manuell" 2 "ZU_automatik" 3 "AUF_manuell" 4 "AUF_automatik" 5 "nicht_verfuegbar" 6 "Init" 7 "Fehler" ;
VAL_ 974 HFS_Lock_Taster_inv 0 "Lock Taster betätgit" 1 "Lock Taster nicht betätigt" ;
VAL_ 974 HFS_Status_eTAG 0 "Init" 1 "Griff_ausgefahren" 2 "Griff_eingefahren" 3 "Fehler" ;
VAL_ 974 HFS_Tuer_Status_QBit 0 "Status_Tuerkontakt_sicher" 1 "Status_Tuerkontakt_unsicher" ;
VAL_ 974 HFS_TCR_Mode_aktiv 0 "TCR_Mode_deaktiv" 1 "TCR_Mode_aktiv" ;
VAL_ 974 HFS_TIG_betaetigt_schliessen 0 "nicht_betaetigt" 1 "betaetigt" ;
VAL_ 974 HFS_TIG_betaetigt_oeffnen 0 "nicht_betaetigt" 1 "betaetigt" ;
VAL_ 974 HFS_Vorraste_betaetigt 0 "nicht_in_Vorraste" 1 "in_Vorraste" ;
VAL_ 974 HFS_SK_betaetigt 0 "ausgehoben" 1 "eingefallen" ;
VAL_ 1718 UH_Typ 0 "undefiniert" 1 "Quarzuhr" 2 "DCF" 3 "GPS" ;
VAL_ 1718 UH_DLS 0 "Winterzeit" 1 "Sommerzeit" ;
VAL_ 1718 UH_Monat 0 "Init" 14 "Relatives_Datum" 15 "Fehler" ;
VAL_ 1718 UH_Tag 0 "Init" ;
VAL_ 2463978710 OPS_ComfortReadyStatus 0 "Init" 1 "aktiv" 2 "inaktiv" 3 "Fehler" ;
VAL_ 2463978710 OPS_OccupantPresenceStatus 0 "Init" 1 "OccupantAbsent" 2 "reserviert" 3 "OccupantEntryExit" 4 "reserviert" 5 "OccupantPresent" 6 "OccupantPresentVerified" 7 "Fehler" ;
VAL_ 2463978710 OPS_DriverPresenceStatus 0 "Init" 1 "reserviert" 2 "DriverAbsent" 3 "reserviert" 4 "DriverEntry" 5 "reserviert" 6 "DriverPresent" 7 "reserviert" 8 "DriverPresentVerified" 9 "reserviert" 10 "reserviert" 11 "DriverExitIntent" 12 "reserviert" 13 "DriverExit" 14 "reserviert" 15 "Fehler" ;
VAL_ 2463978710 OPS_QBit_DriverPresence 0 "gueltiger_Wert" 1 "Ersatz_Init_oder_Fehlerwert" ;
VAL_ 2463978710 OPS_SafeDriverPresenceStatus 0 "Init" 1 "Driver_Safe_Present" 2 "Driver_Not_Safe_Present" 3 "Fehler" ;
VAL_ 2463978710 OPS_SafeDriverPresence_available 0 "Verfuegbar" 1 "Verfuegbar_eingeschr_Performance" ;
VAL_ 995 VS_VD_zu_ver 1 "Zustand des Verdecks verriegelt und geschlossen" ;
VAL_ 995 VS_VD_entriegelt 0 "Init" 1 "Zustand_des_Verdeck_entriegelt" ;
VAL_ 995 VS_VD_offen_ver 0 "Init" 1 "Verdeck_verriegelt_und_offen" ;
VAL_ 995 VS_VD_Zwischenposition 0 "Init" 1 "Verdeck_in_Zwischenposition" ;
VAL_ 995 VS_VD_Bew_auf 1 "Verdeck in Bewegung auf" ;
VAL_ 995 VS_VD_Bew_zu 1 "Verdeck in Bewegung zu" ;
VAL_ 995 VS_Verdeck_Anf 0 "init_nicht_aktiv" 1 "aktiv" ;
VAL_ 995 VS_Hardtop 0 "Init" 1 "Hardtop_montiert" ;
VAL_ 995 VS_VD_Fehler 0 "Init" 1 "Fehlerzustand Verdeck" ;
VAL_ 995 VS_Lampe_Blk 0 "Kontrollleuchte_inaktiv" 1 "Kontrollleuchte_aktiv" ;
VAL_ 995 VS_HD_sperren 0 "HD Entriegelung freigegeben" 1 "HD Entriegelung gesperrt" ;
VAL_ 995 VS_HHS_enable 0 "Init" 1 "Freigabe HHS" ;
VAL_ 995 VD_SpannungsAnf 0 "keine_Anforderung" 1 "Anforderung_Stufe1" 2 "Anforderung_Stufe2" 3 "Anforderung_Stufe3" ;
VAL_ 995 VS_VDKD_auf 0 "VDKD_nicht_vollst_auf" 1 "VDKD_vollstaendig_auf" ;
VAL_ 995 VS_FS_AutoHoch 0 "Keine_Verfahranforderung" 1 "Automatischer_Hochlauf" ;
VAL_ 995 VS_FS_AutoTief 0 "Keine_Verfahranforderung" 1 "Automatischer_Tieflauf" ;
VAL_ 995 VS_FS_ManHoch 0 "Keine_Verfahranforderung" 1 "Manueller_Hochlauf" ;
VAL_ 995 VS_FS_ManTief 0 "Keine_Verfahranforderung" 1 "Manueller_Tieflauf" ;
VAL_ 995 VS_BFS_AutoHoch 0 "Keine_Verfahranforderung" 1 "Automatischer_Hochlauf" ;
VAL_ 995 VS_BFS_AutoTief 0 "Keine_Verfahranforderung" 1 "Automatischer_Tieflauf" ;
VAL_ 995 VS_BFS_ManHoch 0 "Keine_Verfahranforderung" 1 "Manueller_Hochlauf" ;
VAL_ 995 VS_BFS_ManTief 0 "Keine_Verfahranforderung" 1 "Manueller_Tieflauf" ;
VAL_ 995 VS_HFS_AutoHoch 0 "Keine_Verfahranforderung" 1 "Automatischer_Hochlauf" ;
VAL_ 995 VS_HFS_AutoTief 0 "Keine_Verfahranforderung" 1 "Automatischer_Tieflauf" ;
VAL_ 995 VS_HFS_ManHoch 0 "Keine_Verfahranforderung" 1 "Manueller_Hochlauf" ;
VAL_ 995 VS_HFS_ManTief 0 "Keine_Verfahranforderung" 1 "Manueller_Tieflauf" ;
VAL_ 995 VS_HBFS_AutoHoch 0 "Keine_Verfahranforderung" 1 "Automatischer_Hochlauf" ;
VAL_ 995 VS_HBFS_AutoTief 0 "Keine_Verfahranforderung" 1 "Automatischer_Tieflauf" ;
VAL_ 995 VS_HBFS_ManHoch 0 "Keine_Verfahranforderung" 1 "Manueller_Hochlauf" ;
VAL_ 995 VS_HBFS_ManTief 0 "Keine_Verfahranforderung" 1 "Manueller_Tieflauf" ;
VAL_ 995 VS_FH_FT_Langhub 0 "Init" ;
VAL_ 995 VS_Windschott_nicht_abgelegt 0 "inaktiv" 1 "aktiv" ;
VAL_ 995 VS_FH_BT_Langhub 0 "Init" ;
VAL_ 995 VS_FH_HFS_Langhub 0 "Init" ;
VAL_ 995 VS_Heckschloss_auf 0 "kein_Oeffnen" 1 "Heckschloss_oeffnen" ;
VAL_ 995 VS_FH_HBFS_Langhub 0 "Init" ;
VAL_ 995 VSG_Meldungen 0 "keine_Meldung" ;
VAL_ 995 VS_StartStopp_Info 0 "Stoppfreigabe" 1 "Stoppverbot" 2 "Startanforderung" 3 "Fehler" ;
VAL_ 1702 Wischer_vorne_aktiv 0 "Init" 1 "Wischer_vorne_laeuft" ;
VAL_ 1702 Waschen_vorne_aktiv 0 "inaktiv" 1 "Waschen_aktiv" ;
VAL_ 1702 Wischer_vorne_Normal 1 "Wischer Front normal aktiv" ;
VAL_ 1702 Wischer_vorne_Schnell 1 "Wischer vorne schnell aktiv" ;
VAL_ 1702 Wischer_vorne_Parklage 0 "Wischer_Front_nicht_in_Parklage" 1 "Wischer_Front_in_Parklage__Initialzustand" ;
VAL_ 1702 WWSs_01_alt 0 "aktuell" 1 "veraltet" ;
VAL_ 1702 Wischer_vorne_defekt 0 "Init" 1 "Wischer vorne defekt" ;
VAL_ 1702 Wischer_vorne_blockiert 1 "Wischer vorne blockiert" ;
VAL_ 1702 Wischer1_Wischgeschwindigkeit 0 "0 U/min" 62 "Init" 63 "Fehler" ;
VAL_ 1702 BCM1_SRA_aktiv 0 "nicht aktiv" 1 "aktiv" ;
VAL_ 1702 Heckwischer_Anforderung 0 "Aus" 1 "Ein" ;
VAL_ 1702 Wischer_Anzeigetext 0 "keine_Anzeige" 1 "Hinweis_Service_Position" 2 "void" 3 "void" ;
VAL_ 1702 Wischer_WH_Typ 0 "Lenkstockschalter_0_Int_Stufen" 1 "Lenkstockschalter_2_Int_Stufen" 2 "Lenkstockschalter_4_Int_Stufen" ;
VAL_ 1702 Wischer_WH_PopUp_Anf 0 "keine_Anzeige" 1 "Intervallstufe_1_aktiv" 2 "Intervallstufe_2_aktiv" 3 "Intervallstufe_3_aktiv" 4 "Intervallstufe_4_aktiv" 5 "Regensensorstufe_1_aktiv" 6 "Regensensorstufe_2_aktiv" 7 "Regensensorstufe_3_aktiv" 8 "Regensensorstufe_4_aktiv" 9 "Wischerstufe_1_aktiv" 10 "Wischerstufe_2_aktiv" 11 "Tippwischen_aktiv" 12 "Heckwischen_aktiv" ;
VAL_ 1411 ZV_verriegeln_Anf 0 "nicht_betaetigt" 1 "betaetigt" ;
VAL_ 1411 ZV_STSG_HFS_Anf 0 "keine_Anforderung" 1 "Anforderung" ;
VAL_ 1411 ZV_STSG_HBFS_Anf 0 "keine_Anforderung" 1 "Anforderung" ;
VAL_ 1411 ZV_Anf_Challenge_Auth 0 "nicht_aktiv" 1 "aktiv" ;
VAL_ 1411 ZV_STSG_Crashzustand 0 "inaktiv" 1 "aktiv" ;
VAL_ 1411 ZV_STSG_eKiSi_defekt 0 "inaktiv" 1 "aktiv" ;
VAL_ 1411 ZV_eRWK_Umfeld_Pruefung 0 "nicht_aktiv" 1 "aktiv" ;
VAL_ 1411 VIP_Sensor_STSG_HFS_betaetigt 0 "keine_VIP_Anforderung_STSG_HFS" 1 "VIP_Anforderung_STSG_HFS" ;
VAL_ 1411 VIP_Sensor_STSG_HBFS_betaetigt 0 "keine_VIP_Anforderung_STSG_HBFS" 1 "VIP_Anforderung_STSG_HBFS" ;
VAL_ 1411 BCM_FH_Freigabe 1 "Funktionsfreigabe Fensterheber" ;
VAL_ 1411 BCM_Komfortfkt_Freigabe 0 "Komfortfunktion gesperrt" 1 "globale Freigabe der Komfortfunktion erteilt" ;
VAL_ 1411 BCM_HSK_Freigabe 0 "erlauben" 1 "sperren" ;
VAL_ 1411 BCM_Verdeck_Freigabe 0 "Verdeckbetrieb nicht erlaubt" 1 "Verdeckbetrieb erlaubt" ;
VAL_ 1411 ZV_verriegelt_intern_ist 1 "Fahrzeug innen verriegelt; Istzustand" ;
VAL_ 1411 ZV_verriegelt_extern_ist 1 "Fahrzeug_aussen_verriegelt_Istzustand" ;
VAL_ 1411 ZV_verriegelt_intern_soll 1 "Fahrzeug verriegelt intern; Sollzusstand" ;
VAL_ 1411 ZV_verriegelt_extern_soll 1 "Fahrzeug verriegelt extern; Sollzusstand" ;
VAL_ 1411 ZV_gesafet_extern_ist 1 "Fahrzeug aussen gesafet; Istzustand" ;
VAL_ 1411 ZV_gesafet_extern_soll 1 "Fahrzeug_aussen_gesafet_Sollzustand" ;
VAL_ 1411 ZV_Einzeltuerentriegelung 1 "Fahrzeug an Einzeltuer entriegelt" ;
VAL_ 1411 ZV_Heckeinzelentriegelung 1 "Heckdeckeleinzelentriegelung" ;
VAL_ 1411 ZV_FT_offen 0 "FT_geschlossen" 1 "FT_geoeffnet" ;
VAL_ 1411 ZV_BT_offen 0 "BT_geschlossen" 1 "BT_geoeffnet" ;
VAL_ 1411 ZV_HFS_offen 0 "geschlossen" 1 "offen" ;
VAL_ 1411 ZV_HBFS_offen 0 "geschlossen" 1 "offen" ;
VAL_ 1411 ZV_HD_offen 1 "Heckdeckel_auf" ;
VAL_ 1411 ZV_HS_offen 0 "Heckscheibe_geschlossen" 1 "Heckscheibe auf" ;
VAL_ 1411 IRUE_aktiv 0 "unscharf" 1 "scharf" ;
VAL_ 1411 DWA_aktiv 0 "unscharf" 1 "scharf" ;
VAL_ 1411 HD_Hauptraste 0 "geschlossen" 1 "offen" ;
VAL_ 1411 HD_Vorraste 0 "geschlossen" 1 "offen" ;
VAL_ 1411 FFB_HDF_Taste 0 "Taste_nicht_betaetigt" 1 "HDF_Taste_am_Funkschluessel_betaetigt" ;
VAL_ 1411 FFB_Panik_Taste 0 "Taste_nicht_betaetigt" 1 "Panik_Taste_am_Funkschluessel_betaetigt" ;
VAL_ 1411 FFB_Auf_Taste 0 "Taste_nicht_betaetigt" 1 "Oeffnentaste_betaetigt" ;
VAL_ 1411 FFB_Zu_Taste 0 "Taste_nicht_betaetigt" 1 "Zu_Taste_am_Funkschluessel_betaetigt" ;
VAL_ 1411 FFB_CarFinder 0 "nicht aktiv" 1 "aktiv" ;
VAL_ 1411 FFB_Komfortoeffnen 0 "kein_Komfortoeffnen_empfangen" 1 "Komfortoeffnen ueber Funk empfangen" ;
VAL_ 1411 FFB_Komfortschliessen 0 "kein_Komfortschliessen_empfangen" 1 "Komfortschliessen ueber Funk empfangen" ;
VAL_ 1411 FBS_IDG_in_Reichweite 0 "ausser_Reichweite_bzw_nicht_ermittelbar" 1 "innerhalb_Reichweite" ;
VAL_ 1411 ZV_Schluessel_Zugang 0 "kein_auth_Schluessel_erkannt" 1 "aktive_Funkschluessel_Nr_01" 2 "aktive_Funkschluessel_Nr_02" 3 "aktive_Funkschluessel_Nr_03" 4 "aktive_Funkschluessel_Nr_04" 5 "aktive_Funkschluessel_Nr_05" 6 "aktive_Funkschluessel_Nr_06" 7 "aktive_Funkschluessel_Nr_07" 8 "aktive_Funkschluessel_Nr_08" 9 "aktive_SmartDevice_Nr_09" 10 "ungueltig_10" 11 "ungueltig_11" 12 "ungueltig_12" 13 "ungueltig_13" 14 "ungueltig_14" 15 "ungueltig_15" ;
VAL_ 1411 ZV_SafeFunktion_aktiv 0 "inaktiv" 1 "aktiv" ;
VAL_ 1411 FBS_Warn_Schluessel_Batt 0 "i.O." 1 "defekt" ;
VAL_ 1411 ZV_Oeffnungsmodus 0 "globale_Oeffnung" 1 "ZV_mit_Einzeltuerentr" 2 "ZV_individuell_selektiv" 3 "ZV_seitenselektiv" ;
VAL_ 1411 HFS_verriegelt 0 "nicht_verriegelt" 1 "verriegelt" ;
VAL_ 1411 HFS_gesafet 0 "nicht_gesafet" 1 "gesafet" ;
VAL_ 1411 HBFS_verriegelt 0 "nicht_verriegelt" 1 "verriegelt" ;
VAL_ 1411 HBFS_gesafet 0 "nicht_gesafet" 1 "gesafet" ;
VAL_ 1411 ZV_ist_Zustand_verfuegbar 0 "nicht_verfuegbar" 1 "verfuegbar_alle_TSGs_am_Bus" ;
VAL_ 1411 IRUE_Taster_Fkts_LED 0 "LED_aus" 1 "LED_ein" ;
VAL_ 1411 ZV_Tankklappe_offen 0 "Tankklappe_geschlossen" 1 "Tankklappe_offen" ;
VAL_ 1411 ZV_Rollo_auf 0 "inaktiv" 1 "aktiv" ;
VAL_ 1411 ZV_Rollo_zu 0 "inaktiv" 1 "aktiv" ;
VAL_ 1411 ZV_SAD_auf 0 "inaktiv" 1 "aktiv" ;
VAL_ 1411 ZV_SAD_zu 0 "inaktiv" 1 "aktiv" ;
VAL_ 1411 BCM_Tankklappensteller_Fehler 0 "kein_Fehler" 1 "Fehler" ;
VAL_ 1411 ZV_verriegelt_soll 0 "Init" 1 "nicht_verriegelt" 2 "verriegelt" ;
